[part 1 of 4: packages /MICROSAR/vDem42_swc/DataTypes to /MICROSAR/vDem42_swc/ComponentTypes]
AUTOSAR XML (schema 4-2-1)
package /MICROSAR/vDem42_swc/DataTypes
  12 x impl type:
    Dem_DTCFormatType: compu {0=DEM_DTC_FORMAT_OBD, 1=DEM_DTC_FORMAT_UDS, 2=DEM_DTC_FORMAT_J1939}, range raw 0..255, implementation-data-type=uint8
    Dem_DTCOriginType:
      compu {1=DEM_DTC_ORIGIN_PRIMARY_MEMORY, 2=DEM_DTC_ORIGIN_MIRROR_MEMORY, 3=DEM_DTC_ORIGIN_PERMANENT_MEMORY, 4=DEM_DTC_ORIGIN_OBD_RELEVANT_MEMORY, 5=DEM_DTC_ORIGIN_SECONDARY_MEMORY, 5=DEM_DTC_ORIGIN_USERDEFINED_MEMORY_10, 5=DEM_DTC_ORIGIN_USERDEFINED_MEMORY_11, 5=DEM_DTC_ORIGIN_USERDEFINED_MEMORY_12, 5=DEM_DTC_ORIGIN_USERDEFINED_MEMORY_13, 5=DEM_DTC_ORIGIN_USERDEFINED_MEMORY_14, 5=DEM_DTC_ORIGIN_USERDEFINED_MEMORY_15, 5=DEM_DTC_ORIGIN_USERDEFINED_MEMORY_16, 5=DEM_DTC_ORIGIN_USERDEFINED_MEMORY_17, 5=DEM_DTC_ORIGIN_USERDEFINED_MEMORY_18, 5=DEM_DTC_ORIGIN_USERDEFINED_MEMORY_19, 5=DEM_DTC_ORIGIN_USERDEFINED_MEMORY_1A, 5=DEM_DTC_ORIGIN_USERDEFINED_MEMORY_1B, 5=DEM_DTC_ORIGIN_USERDEFINED_MEMORY_1C, 5=DEM_DTC_ORIGIN_USERDEFINED_MEMORY_1D, 5=DEM_DTC_ORIGIN_USERDEFINED_MEMORY_1E, 5=DEM_DTC_ORIGIN_USERDEFINED_MEMORY_1F, 5=DEM_DTC_ORIGIN_USERDEFINED_MEMORY_20, 5=DEM_DTC_ORIGIN_USERDEFINED_MEMORY_21, 5=DEM_DTC_ORIGIN_USERDEFINED_MEMORY_22, 5=DEM_DTC_ORIGIN_USERDEFINED_MEMORY_23, 5=DEM_DTC_ORIGIN_USERDEFINED_MEMORY_24, 5=DEM_DTC_ORIGIN_USERDEFINED_MEMORY_25, 5=DEM_DTC_ORIGIN_USERDEFINED_MEMORY_26, 5=DEM_DTC_ORIGIN_USERDEFINED_MEMORY_27, 5=DEM_DTC_ORIGIN_USERDEFINED_MEMORY_28, 5=DEM_DTC_ORIGIN_USERDEFINED_MEMORY_29, 5=DEM_DTC_ORIGIN_USERDEFINED_MEMORY_2A, 5=DEM_DTC_ORIGIN_USERDEFINED_MEMORY_2B, 5=DEM_DTC_ORIGIN_USERDEFINED_MEMORY_2C, 5=DEM_DTC_ORIGIN_USERDEFINED_MEMORY_2D, 5=DEM_DTC_ORIGIN_USERDEFINED_MEMORY_2E, 5=DEM_DTC_ORIGIN_USERDEFINED_MEMORY_2F, 5=DEM_DTC_ORIGIN_USERDEFINED_MEMORY_30, 5=DEM_DTC_ORIGIN_USERDEFINED_MEMORY_31, 5=DEM_DTC_ORIGIN_USERDEFINED_MEMORY_32, 5=DEM_DTC_ORIGIN_USERDEFINED_MEMORY_33, 5=DEM_DTC_ORIGIN_USERDEFINED_MEMORY_34, 5=DEM_DTC_ORIGIN_USERDEFINED_MEMORY_35, 5=DEM_DTC_ORIGIN_USERDEFINED_MEMORY_36, 5=DEM_DTC_ORIGIN_USERDEFINED_MEMORY_37, 5=DEM_DTC_ORIGIN_USERDEFINED_MEMORY_38, 5=DEM_DTC_ORIGIN_USERDEFINED_MEMORY_39, 5=DEM_DTC_ORIGIN_USERDEFINED_MEMORY_3A, 5=DEM_DTC_ORIGIN_USERDEFINED_MEMORY_3B, 5=DEM_DTC_ORIGIN_USERDEFINED_MEMORY_3C, 5=DEM_DTC_ORIGIN_USERDEFINED_MEMORY_3D, 5=DEM_DTC_ORIGIN_USERDEFINED_MEMORY_3E, 5=DEM_DTC_ORIGIN_USERDEFINED_MEMORY_3F, 5=DEM_DTC_ORIGIN_USERDEFINED_MEMORY_40, 5=DEM_DTC_ORIGIN_USERDEFINED_MEMORY_41, 5=DEM_DTC_ORIGIN_USERDEFINED_MEMORY_42, 5=DEM_DTC_ORIGIN_USERDEFINED_MEMORY_43, 5=DEM_DTC_ORIGIN_USERDEFINED_MEMORY_44, 5=DEM_DTC_ORIGIN_USERDEFINED_MEMORY_45, 5=DEM_DTC_ORIGIN_USERDEFINED_MEMORY_46, 5=DEM_DTC_ORIGIN_USERDEFINED_MEMORY_47, 5=DEM_DTC_ORIGIN_USERDEFINED_MEMORY_48, 5=DEM_DTC_ORIGIN_USERDEFINED_MEMORY_49, 5=DEM_DTC_ORIGIN_USERDEFINED_MEMORY_4A, 5=DEM_DTC_ORIGIN_USERDEFINED_MEMORY_4B, 5=DEM_DTC_ORIGIN_USERDEFINED_MEMORY_4C, 5=DEM_DTC_ORIGIN_USERDEFINED_MEMORY_4D, 5=DEM_DTC_ORIGIN_USERDEFINED_MEMORY_4E, 5=DEM_DTC_ORIGIN_USERDEFINED_MEMORY_4F, 5=DEM_DTC_ORIGIN_USERDEFINED_MEMORY_50, 5=DEM_DTC_ORIGIN_USERDEFINED_MEMORY_51, 5=DEM_DTC_ORIGIN_USERDEFINED_MEMORY_52, 5=DEM_DTC_ORIGIN_USERDEFINED_MEMORY_53, 5=DEM_DTC_ORIGIN_USERDEFINED_MEMORY_54, 5=DEM_DTC_ORIGIN_USERDEFINED_MEMORY_55, 5=DEM_DTC_ORIGIN_USERDEFINED_MEMORY_56, 5=DEM_DTC_ORIGIN_USERDEFINED_MEMORY_57, 5=DEM_DTC_ORIGIN_USERDEFINED_MEMORY_58, 5=DEM_DTC_ORIGIN_USERDEFINED_MEMORY_59, 5=DEM_DTC_ORIGIN_USERDEFINED_MEMORY_5A, 5=DEM_DTC_ORIGIN_USERDEFINED_MEMORY_5B, 5=DEM_DTC_ORIGIN_USERDEFINED_MEMORY_5C, 5=DEM_DTC_ORIGIN_USERDEFINED_MEMORY_5D, 5=DEM_DTC_ORIGIN_USERDEFINED_MEMORY_5E, 5=DEM_DTC_ORIGIN_USERDEFINED_MEMORY_5F, 5=DEM_DTC_ORIGIN_USERDEFINED_MEMORY_60, 5=DEM_DTC_ORIGIN_USERDEFINED_MEMORY_61, 5=DEM_DTC_ORIGIN_USERDEFINED_MEMORY_62, 5=DEM_DTC_ORIGIN_USERDEFINED_MEMORY_63, 5=DEM_DTC_ORIGIN_USERDEFINED_MEMORY_64, 5=DEM_DTC_ORIGIN_USERDEFINED_MEMORY_65, 5=DEM_DTC_ORIGIN_USERDEFINED_MEMORY_66, 5=DEM_DTC_ORIGIN_USERDEFINED_MEMORY_67, 5=DEM_DTC_ORIGIN_USERDEFINED_MEMORY_68, 5=DEM_DTC_ORIGIN_USERDEFINED_MEMORY_69, 5=DEM_DTC_ORIGIN_USERDEFINED_MEMORY_6A, 5=DEM_DTC_ORIGIN_USERDEFINED_MEMORY_6B, 5=DEM_DTC_ORIGIN_USERDEFINED_MEMORY_6C, 5=DEM_DTC_ORIGIN_USERDEFINED_MEMORY_6D, 5=DEM_DTC_ORIGIN_USERDEFINED_MEMORY_6E, 5=DEM_DTC_ORIGIN_USERDEFINED_MEMORY_6F, 5=DEM_DTC_ORIGIN_USERDEFINED_MEMORY_70, 5=DEM_DTC_ORIGIN_USERDEFINED_MEMORY_71, 5=DEM_DTC_ORIGIN_USERDEFINED_MEMORY_72, 5=DEM_DTC_ORIGIN_USERDEFINED_MEMORY_73, 5=DEM_DTC_ORIGIN_USERDEFINED_MEMORY_74, 5=DEM_DTC_ORIGIN_USERDEFINED_MEMORY_75, 5=DEM_DTC_ORIGIN_USERDEFINED_MEMORY_76, 5=DEM_DTC_ORIGIN_USERDEFINED_MEMORY_77, 5=DEM_DTC_ORIGIN_USERDEFINED_MEMORY_78, 5=DEM_DTC_ORIGIN_USERDEFINED_MEMORY_79, 5=DEM_DTC_ORIGIN_USERDEFINED_MEMORY_7A, 5=DEM_DTC_ORIGIN_USERDEFINED_MEMORY_7B, 5=DEM_DTC_ORIGIN_USERDEFINED_MEMORY_7C, 5=DEM_DTC_ORIGIN_USERDEFINED_MEMORY_7D, 5=DEM_DTC_ORIGIN_USERDEFINED_MEMORY_7E, 5=DEM_DTC_ORIGIN_USERDEFINED_MEMORY_7F, 5=DEM_DTC_ORIGIN_USERDEFINED_MEMORY_80, 5=DEM_DTC_ORIGIN_USERDEFINED_MEMORY_81, 5=DEM_DTC_ORIGIN_USERDEFINED_MEMORY_82, 5=DEM_DTC_ORIGIN_USERDEFINED_MEMORY_83, 5=DEM_DTC_ORIGIN_USERDEFINED_MEMORY_84, 5=DEM_DTC_ORIGIN_USERDEFINED_MEMORY_85, 5=DEM_DTC_ORIGIN_USERDEFINED_MEMORY_86, 5=DEM_DTC_ORIGIN_USERDEFINED_MEMORY_87, 5=DEM_DTC_ORIGIN_USERDEFINED_MEMORY_88, 5=DEM_DTC_ORIGIN_USERDEFINED_MEMORY_89, 5=DEM_DTC_ORIGIN_USERDEFINED_MEMORY_8A, 5=DEM_DTC_ORIGIN_USERDEFINED_MEMORY_8B, 5=DEM_DTC_ORIGIN_USERDEFINED_MEMORY_8C, 5=DEM_DTC_ORIGIN_USERDEFINED_MEMORY_8D, 5=DEM_DTC_ORIGIN_USERDEFINED_MEMORY_8E, 5=DEM_DTC_ORIGIN_USERDEFINED_MEMORY_8F, 5=DEM_DTC_ORIGIN_USERDEFINED_MEMORY_90, 5=DEM_DTC_ORIGIN_USERDEFINED_MEMORY_91, 5=DEM_DTC_ORIGIN_USERDEFINED_MEMORY_92, 5=DEM_DTC_ORIGIN_USERDEFINED_MEMORY_93, 5=DEM_DTC_ORIGIN_USERDEFINED_MEMORY_94, 5=DEM_DTC_ORIGIN_USERDEFINED_MEMORY_95, 5=DEM_DTC_ORIGIN_USERDEFINED_MEMORY_96, 5=DEM_DTC_ORIGIN_USERDEFINED_MEMORY_97, 5=DEM_DTC_ORIGIN_USERDEFINED_MEMORY_98, 5=DEM_DTC_ORIGIN_USERDEFINED_MEMORY_99, 5=DEM_DTC_ORIGIN_USERDEFINED_MEMORY_9A, 5=DEM_DTC_ORIGIN_USERDEFINED_MEMORY_9B, 5=DEM_DTC_ORIGIN_USERDEFINED_MEMORY_9C, 5=DEM_DTC_ORIGIN_USERDEFINED_MEMORY_9D, 5=DEM_DTC_ORIGIN_USERDEFINED_MEMORY_9E, 5=DEM_DTC_ORIGIN_USERDEFINED_MEMORY_9F, 5=DEM_DTC_ORIGIN_USERDEFINED_MEMORY_A0, 5=DEM_DTC_ORIGIN_USERDEFINED_MEMORY_A1, 5=DEM_DTC_ORIGIN_USERDEFINED_MEMORY_A2, 5=DEM_DTC_ORIGIN_USERDEFINED_MEMORY_A3, 5=DEM_DTC_ORIGIN_USERDEFINED_MEMORY_A4, 5=DEM_DTC_ORIGIN_USERDEFINED_MEMORY_A5, 5=DEM_DTC_ORIGIN_USERDEFINED_MEMORY_A6, 5=DEM_DTC_ORIGIN_USERDEFINED_MEMORY_A7, 5=DEM_DTC_ORIGIN_USERDEFINED_MEMORY_A8, 5=DEM_DTC_ORIGIN_USERDEFINED_MEMORY_A9, 5=DEM_DTC_ORIGIN_USERDEFINED_MEMORY_AA, 5=DEM_DTC_ORIGIN_USERDEFINED_MEMORY_AB, 5=DEM_DTC_ORIGIN_USERDEFINED_MEMORY_AC, 5=DEM_DTC_ORIGIN_USERDEFINED_MEMORY_AD, 5=DEM_DTC_ORIGIN_USERDEFINED_MEMORY_AE, 5=DEM_DTC_ORIGIN_USERDEFINED_MEMORY_AF, 5=DEM_DTC_ORIGIN_USERDEFINED_MEMORY_B0, 5=DEM_DTC_ORIGIN_USERDEFINED_MEMORY_B1, 5=DEM_DTC_ORIGIN_USERDEFINED_MEMORY_B2, 5=DEM_DTC_ORIGIN_USERDEFINED_MEMORY_B3, 5=DEM_DTC_ORIGIN_USERDEFINED_MEMORY_B4, 5=DEM_DTC_ORIGIN_USERDEFINED_MEMORY_B5, 5=DEM_DTC_ORIGIN_USERDEFINED_MEMORY_B6, 5=DEM_DTC_ORIGIN_USERDEFINED_MEMORY_B7, 5=DEM_DTC_ORIGIN_USERDEFINED_MEMORY_B8, 5=DEM_DTC_ORIGIN_USERDEFINED_MEMORY_B9, 5=DEM_DTC_ORIGIN_USERDEFINED_MEMORY_BA, 5=DEM_DTC_ORIGIN_USERDEFINED_MEMORY_BB, 5=DEM_DTC_ORIGIN_USERDEFINED_MEMORY_BC, 5=DEM_DTC_ORIGIN_USERDEFINED_MEMORY_BD, 5=DEM_DTC_ORIGIN_USERDEFINED_MEMORY_BE, 5=DEM_DTC_ORIGIN_USERDEFINED_MEMORY_BF, 5=DEM_DTC_ORIGIN_USERDEFINED_MEMORY_C0, 5=DEM_DTC_ORIGIN_USERDEFINED_MEMORY_C1, 5=DEM_DTC_ORIGIN_USERDEFINED_MEMORY_C2, 5=DEM_DTC_ORIGIN_USERDEFINED_MEMORY_C3, 5=DEM_DTC_ORIGIN_USERDEFINED_MEMORY_C4, 5=DEM_DTC_ORIGIN_USERDEFINED_MEMORY_C5, 5=DEM_DTC_ORIGIN_USERDEFINED_MEMORY_C6, 5=DEM_DTC_ORIGIN_USERDEFINED_MEMORY_C7, 5=DEM_DTC_ORIGIN_USERDEFINED_MEMORY_C8, 5=DEM_DTC_ORIGIN_USERDEFINED_MEMORY_C9, 5=DEM_DTC_ORIGIN_USERDEFINED_MEMORY_CA, 5=DEM_DTC_ORIGIN_USERDEFINED_MEMORY_CB, 5=DEM_DTC_ORIGIN_USERDEFINED_MEMORY_CC, 5=DEM_DTC_ORIGIN_USERDEFINED_MEMORY_CD, 5=DEM_DTC_ORIGIN_USERDEFINED_MEMORY_CE, 5=DEM_DTC_ORIGIN_USERDEFINED_MEMORY_CF, 5=DEM_DTC_ORIGIN_USERDEFINED_MEMORY_D0, 5=DEM_DTC_ORIGIN_USERDEFINED_MEMORY_D1, 5=DEM_DTC_ORIGIN_USERDEFINED_MEMORY_D2, 5=DEM_DTC_ORIGIN_USERDEFINED_MEMORY_D3, 5=DEM_DTC_ORIGIN_USERDEFINED_MEMORY_D4, 5=DEM_DTC_ORIGIN_USERDEFINED_MEMORY_D5, 5=DEM_DTC_ORIGIN_USERDEFINED_MEMORY_D6, 5=DEM_DTC_ORIGIN_USERDEFINED_MEMORY_D7, 5=DEM_DTC_ORIGIN_USERDEFINED_MEMORY_D8, 5=DEM_DTC_ORIGIN_USERDEFINED_MEMORY_D9, 5=DEM_DTC_ORIGIN_USERDEFINED_MEMORY_DA, 5=DEM_DTC_ORIGIN_USERDEFINED_MEMORY_DB, 5=DEM_DTC_ORIGIN_USERDEFINED_MEMORY_DC, 5=DEM_DTC_ORIGIN_USERDEFINED_MEMORY_DD, 5=DEM_DTC_ORIGIN_USERDEFINED_MEMORY_DE, 5=DEM_DTC_ORIGIN_USERDEFINED_MEMORY_DF, 5=DEM_DTC_ORIGIN_USERDEFINED_MEMORY_E0, 5=DEM_DTC_ORIGIN_USERDEFINED_MEMORY_E1, 5=DEM_DTC_ORIGIN_USERDEFINED_MEMORY_E2, 5=DEM_DTC_ORIGIN_USERDEFINED_MEMORY_E3, 5=DEM_DTC_ORIGIN_USERDEFINED_MEMORY_E4, 5=DEM_DTC_ORIGIN_USERDEFINED_MEMORY_E5, 5=DEM_DTC_ORIGIN_USERDEFINED_MEMORY_E6, 5=DEM_DTC_ORIGIN_USERDEFINED_MEMORY_E7, 5=DEM_DTC_ORIGIN_USERDEFINED_MEMORY_E8, 5=DEM_DTC_ORIGIN_USERDEFINED_MEMORY_E9, 5=DEM_DTC_ORIGIN_USERDEFINED_MEMORY_EA, 5=DEM_DTC_ORIGIN_USERDEFINED_MEMORY_EB, 5=DEM_DTC_ORIGIN_USERDEFINED_MEMORY_EC, 5=DEM_DTC_ORIGIN_USERDEFINED_MEMORY_ED, 5=DEM_DTC_ORIGIN_USERDEFINED_MEMORY_EE, 5=DEM_DTC_ORIGIN_USERDEFINED_MEMORY_EF, 5=DEM_DTC_ORIGIN_USERDEFINED_MEMORY_F0, 5=DEM_DTC_ORIGIN_USERDEFINED_MEMORY_F1, 5=DEM_DTC_ORIGIN_USERDEFINED_MEMORY_F2, 5=DEM_DTC_ORIGIN_USERDEFINED_MEMORY_F3, 5=DEM_DTC_ORIGIN_USERDEFINED_MEMORY_F4, 5=DEM_DTC_ORIGIN_USERDEFINED_MEMORY_F5, 5=DEM_DTC_ORIGIN_USERDEFINED_MEMORY_F6, 5=DEM_DTC_ORIGIN_USERDEFINED_MEMORY_F7, 5=DEM_DTC_ORIGIN_USERDEFINED_MEMORY_F8, 5=DEM_DTC_ORIGIN_USERDEFINED_MEMORY_F9, 5=DEM_DTC_ORIGIN_USERDEFINED_MEMORY_FA, 5=DEM_DTC_ORIGIN_USERDEFINED_MEMORY_FB, 5=DEM_DTC_ORIGIN_USERDEFINED_MEMORY_FC, 5=DEM_DTC_ORIGIN_USERDEFINED_MEMORY_FD, 5=DEM_DTC_ORIGIN_USERDEFINED_MEMORY_FE, 5=DEM_DTC_ORIGIN_USERDEFINED_MEMORY_FF}
      range raw 0..65535
      implementation-data-type=uint16
    Dem_UdsStatusByteType: compu {mask 1: 1=DEM_UDS_STATUS_TF, mask 2: 2=DEM_UDS_STATUS_TFTOC, mask 4: 4=DEM_UDS_STATUS_PDTC, mask 8: 8=DEM_UDS_STATUS_CDTC, mask 16: 16=DEM_UDS_STATUS_TNCSLC, mask 32: 32=DEM_UDS_STATUS_TFSLC, mask 64: 64=DEM_UDS_STATUS_TNCTOC, mask 128: 128=DEM_UDS_STATUS_WIR}, range raw 0..255, implementation-data-type=uint8
    Dem_EventIdType: range raw 1..65535, implementation-data-type=uint16
    Dem_DebouncingStateType: compu {mask 1: 1=DEM_TEMPORARILY_DEFECTIVE, mask 2: 2=DEM_FINALLY_DEFECTIVE, mask 4: 4=DEM_TEMPORARILY_HEALED, mask 8: 8=DEM_TEST_COMPLETE, mask 16: 16=DEM_DTR_UPDATE}, range raw 0..255, implementation-data-type=uint8
    VDem42_DTCFormatType: compu {0=VDEM42_DTC_FORMAT_OBD, 1=VDEM42_DTC_FORMAT_UDS, 2=VDEM42_DTC_FORMAT_J1939}, range raw 0..255, implementation-data-type=uint8
    VDem42_DTCOriginType:
      compu {1=VDEM42_DTC_ORIGIN_PRIMARY_MEMORY, 2=VDEM42_DTC_ORIGIN_MIRROR_MEMORY, 3=VDEM42_DTC_ORIGIN_PERMANENT_MEMORY, 4=VDEM42_DTC_ORIGIN_OBD_RELEVANT_MEMORY, 5=VDEM42_DTC_ORIGIN_SECONDARY_MEMORY, 5=VDEM42_DTC_ORIGIN_USERDEFINED_MEMORY_10, 5=VDEM42_DTC_ORIGIN_USERDEFINED_MEMORY_11, 5=VDEM42_DTC_ORIGIN_USERDEFINED_MEMORY_12, 5=VDEM42_DTC_ORIGIN_USERDEFINED_MEMORY_13, 5=VDEM42_DTC_ORIGIN_USERDEFINED_MEMORY_14, 5=VDEM42_DTC_ORIGIN_USERDEFINED_MEMORY_15, 5=VDEM42_DTC_ORIGIN_USERDEFINED_MEMORY_16, 5=VDEM42_DTC_ORIGIN_USERDEFINED_MEMORY_17, 5=VDEM42_DTC_ORIGIN_USERDEFINED_MEMORY_18, 5=VDEM42_DTC_ORIGIN_USERDEFINED_MEMORY_19, 5=VDEM42_DTC_ORIGIN_USERDEFINED_MEMORY_1A, 5=VDEM42_DTC_ORIGIN_USERDEFINED_MEMORY_1B, 5=VDEM42_DTC_ORIGIN_USERDEFINED_MEMORY_1C, 5=VDEM42_DTC_ORIGIN_USERDEFINED_MEMORY_1D, 5=VDEM42_DTC_ORIGIN_USERDEFINED_MEMORY_1E, 5=VDEM42_DTC_ORIGIN_USERDEFINED_MEMORY_1F, 5=VDEM42_DTC_ORIGIN_USERDEFINED_MEMORY_20, 5=VDEM42_DTC_ORIGIN_USERDEFINED_MEMORY_21, 5=VDEM42_DTC_ORIGIN_USERDEFINED_MEMORY_22, 5=VDEM42_DTC_ORIGIN_USERDEFINED_MEMORY_23, 5=VDEM42_DTC_ORIGIN_USERDEFINED_MEMORY_24, 5=VDEM42_DTC_ORIGIN_USERDEFINED_MEMORY_25, 5=VDEM42_DTC_ORIGIN_USERDEFINED_MEMORY_26, 5=VDEM42_DTC_ORIGIN_USERDEFINED_MEMORY_27, 5=VDEM42_DTC_ORIGIN_USERDEFINED_MEMORY_28, 5=VDEM42_DTC_ORIGIN_USERDEFINED_MEMORY_29, 5=VDEM42_DTC_ORIGIN_USERDEFINED_MEMORY_2A, 5=VDEM42_DTC_ORIGIN_USERDEFINED_MEMORY_2B, 5=VDEM42_DTC_ORIGIN_USERDEFINED_MEMORY_2C, 5=VDEM42_DTC_ORIGIN_USERDEFINED_MEMORY_2D, 5=VDEM42_DTC_ORIGIN_USERDEFINED_MEMORY_2E, 5=VDEM42_DTC_ORIGIN_USERDEFINED_MEMORY_2F, 5=VDEM42_DTC_ORIGIN_USERDEFINED_MEMORY_30, 5=VDEM42_DTC_ORIGIN_USERDEFINED_MEMORY_31, 5=VDEM42_DTC_ORIGIN_USERDEFINED_MEMORY_32, 5=VDEM42_DTC_ORIGIN_USERDEFINED_MEMORY_33, 5=VDEM42_DTC_ORIGIN_USERDEFINED_MEMORY_34, 5=VDEM42_DTC_ORIGIN_USERDEFINED_MEMORY_35, 5=VDEM42_DTC_ORIGIN_USERDEFINED_MEMORY_36, 5=VDEM42_DTC_ORIGIN_USERDEFINED_MEMORY_37, 5=VDEM42_DTC_ORIGIN_USERDEFINED_MEMORY_38, 5=VDEM42_DTC_ORIGIN_USERDEFINED_MEMORY_39, 5=VDEM42_DTC_ORIGIN_USERDEFINED_MEMORY_3A, 5=VDEM42_DTC_ORIGIN_USERDEFINED_MEMORY_3B, 5=VDEM42_DTC_ORIGIN_USERDEFINED_MEMORY_3C, 5=VDEM42_DTC_ORIGIN_USERDEFINED_MEMORY_3D, 5=VDEM42_DTC_ORIGIN_USERDEFINED_MEMORY_3E, 5=VDEM42_DTC_ORIGIN_USERDEFINED_MEMORY_3F, 5=VDEM42_DTC_ORIGIN_USERDEFINED_MEMORY_40, 5=VDEM42_DTC_ORIGIN_USERDEFINED_MEMORY_41, 5=VDEM42_DTC_ORIGIN_USERDEFINED_MEMORY_42, 5=VDEM42_DTC_ORIGIN_USERDEFINED_MEMORY_43, 5=VDEM42_DTC_ORIGIN_USERDEFINED_MEMORY_44, 5=VDEM42_DTC_ORIGIN_USERDEFINED_MEMORY_45, 5=VDEM42_DTC_ORIGIN_USERDEFINED_MEMORY_46, 5=VDEM42_DTC_ORIGIN_USERDEFINED_MEMORY_47, 5=VDEM42_DTC_ORIGIN_USERDEFINED_MEMORY_48, 5=VDEM42_DTC_ORIGIN_USERDEFINED_MEMORY_49, 5=VDEM42_DTC_ORIGIN_USERDEFINED_MEMORY_4A, 5=VDEM42_DTC_ORIGIN_USERDEFINED_MEMORY_4B, 5=VDEM42_DTC_ORIGIN_USERDEFINED_MEMORY_4C, 5=VDEM42_DTC_ORIGIN_USERDEFINED_MEMORY_4D, 5=VDEM42_DTC_ORIGIN_USERDEFINED_MEMORY_4E, 5=VDEM42_DTC_ORIGIN_USERDEFINED_MEMORY_4F, 5=VDEM42_DTC_ORIGIN_USERDEFINED_MEMORY_50, 5=VDEM42_DTC_ORIGIN_USERDEFINED_MEMORY_51, 5=VDEM42_DTC_ORIGIN_USERDEFINED_MEMORY_52, 5=VDEM42_DTC_ORIGIN_USERDEFINED_MEMORY_53, 5=VDEM42_DTC_ORIGIN_USERDEFINED_MEMORY_54, 5=VDEM42_DTC_ORIGIN_USERDEFINED_MEMORY_55, 5=VDEM42_DTC_ORIGIN_USERDEFINED_MEMORY_56, 5=VDEM42_DTC_ORIGIN_USERDEFINED_MEMORY_57, 5=VDEM42_DTC_ORIGIN_USERDEFINED_MEMORY_58, 5=VDEM42_DTC_ORIGIN_USERDEFINED_MEMORY_59, 5=VDEM42_DTC_ORIGIN_USERDEFINED_MEMORY_5A, 5=VDEM42_DTC_ORIGIN_USERDEFINED_MEMORY_5B, 5=VDEM42_DTC_ORIGIN_USERDEFINED_MEMORY_5C, 5=VDEM42_DTC_ORIGIN_USERDEFINED_MEMORY_5D, 5=VDEM42_DTC_ORIGIN_USERDEFINED_MEMORY_5E, 5=VDEM42_DTC_ORIGIN_USERDEFINED_MEMORY_5F, 5=VDEM42_DTC_ORIGIN_USERDEFINED_MEMORY_60, 5=VDEM42_DTC_ORIGIN_USERDEFINED_MEMORY_61, 5=VDEM42_DTC_ORIGIN_USERDEFINED_MEMORY_62, 5=VDEM42_DTC_ORIGIN_USERDEFINED_MEMORY_63, 5=VDEM42_DTC_ORIGIN_USERDEFINED_MEMORY_64, 5=VDEM42_DTC_ORIGIN_USERDEFINED_MEMORY_65, 5=VDEM42_DTC_ORIGIN_USERDEFINED_MEMORY_66, 5=VDEM42_DTC_ORIGIN_USERDEFINED_MEMORY_67, 5=VDEM42_DTC_ORIGIN_USERDEFINED_MEMORY_68, 5=VDEM42_DTC_ORIGIN_USERDEFINED_MEMORY_69, 5=VDEM42_DTC_ORIGIN_USERDEFINED_MEMORY_6A, 5=VDEM42_DTC_ORIGIN_USERDEFINED_MEMORY_6B, 5=VDEM42_DTC_ORIGIN_USERDEFINED_MEMORY_6C, 5=VDEM42_DTC_ORIGIN_USERDEFINED_MEMORY_6D, 5=VDEM42_DTC_ORIGIN_USERDEFINED_MEMORY_6E, 5=VDEM42_DTC_ORIGIN_USERDEFINED_MEMORY_6F, 5=VDEM42_DTC_ORIGIN_USERDEFINED_MEMORY_70, 5=VDEM42_DTC_ORIGIN_USERDEFINED_MEMORY_71, 5=VDEM42_DTC_ORIGIN_USERDEFINED_MEMORY_72, 5=VDEM42_DTC_ORIGIN_USERDEFINED_MEMORY_73, 5=VDEM42_DTC_ORIGIN_USERDEFINED_MEMORY_74, 5=VDEM42_DTC_ORIGIN_USERDEFINED_MEMORY_75, 5=VDEM42_DTC_ORIGIN_USERDEFINED_MEMORY_76, 5=VDEM42_DTC_ORIGIN_USERDEFINED_MEMORY_77, 5=VDEM42_DTC_ORIGIN_USERDEFINED_MEMORY_78, 5=VDEM42_DTC_ORIGIN_USERDEFINED_MEMORY_79, 5=VDEM42_DTC_ORIGIN_USERDEFINED_MEMORY_7A, 5=VDEM42_DTC_ORIGIN_USERDEFINED_MEMORY_7B, 5=VDEM42_DTC_ORIGIN_USERDEFINED_MEMORY_7C, 5=VDEM42_DTC_ORIGIN_USERDEFINED_MEMORY_7D, 5=VDEM42_DTC_ORIGIN_USERDEFINED_MEMORY_7E, 5=VDEM42_DTC_ORIGIN_USERDEFINED_MEMORY_7F, 5=VDEM42_DTC_ORIGIN_USERDEFINED_MEMORY_80, 5=VDEM42_DTC_ORIGIN_USERDEFINED_MEMORY_81, 5=VDEM42_DTC_ORIGIN_USERDEFINED_MEMORY_82, 5=VDEM42_DTC_ORIGIN_USERDEFINED_MEMORY_83, 5=VDEM42_DTC_ORIGIN_USERDEFINED_MEMORY_84, 5=VDEM42_DTC_ORIGIN_USERDEFINED_MEMORY_85, 5=VDEM42_DTC_ORIGIN_USERDEFINED_MEMORY_86, 5=VDEM42_DTC_ORIGIN_USERDEFINED_MEMORY_87, 5=VDEM42_DTC_ORIGIN_USERDEFINED_MEMORY_88, 5=VDEM42_DTC_ORIGIN_USERDEFINED_MEMORY_89, 5=VDEM42_DTC_ORIGIN_USERDEFINED_MEMORY_8A, 5=VDEM42_DTC_ORIGIN_USERDEFINED_MEMORY_8B, 5=VDEM42_DTC_ORIGIN_USERDEFINED_MEMORY_8C, 5=VDEM42_DTC_ORIGIN_USERDEFINED_MEMORY_8D, 5=VDEM42_DTC_ORIGIN_USERDEFINED_MEMORY_8E, 5=VDEM42_DTC_ORIGIN_USERDEFINED_MEMORY_8F, 5=VDEM42_DTC_ORIGIN_USERDEFINED_MEMORY_90, 5=VDEM42_DTC_ORIGIN_USERDEFINED_MEMORY_91, 5=VDEM42_DTC_ORIGIN_USERDEFINED_MEMORY_92, 5=VDEM42_DTC_ORIGIN_USERDEFINED_MEMORY_93, 5=VDEM42_DTC_ORIGIN_USERDEFINED_MEMORY_94, 5=VDEM42_DTC_ORIGIN_USERDEFINED_MEMORY_95, 5=VDEM42_DTC_ORIGIN_USERDEFINED_MEMORY_96, 5=VDEM42_DTC_ORIGIN_USERDEFINED_MEMORY_97, 5=VDEM42_DTC_ORIGIN_USERDEFINED_MEMORY_98, 5=VDEM42_DTC_ORIGIN_USERDEFINED_MEMORY_99, 5=VDEM42_DTC_ORIGIN_USERDEFINED_MEMORY_9A, 5=VDEM42_DTC_ORIGIN_USERDEFINED_MEMORY_9B, 5=VDEM42_DTC_ORIGIN_USERDEFINED_MEMORY_9C, 5=VDEM42_DTC_ORIGIN_USERDEFINED_MEMORY_9D, 5=VDEM42_DTC_ORIGIN_USERDEFINED_MEMORY_9E, 5=VDEM42_DTC_ORIGIN_USERDEFINED_MEMORY_9F, 5=VDEM42_DTC_ORIGIN_USERDEFINED_MEMORY_A0, 5=VDEM42_DTC_ORIGIN_USERDEFINED_MEMORY_A1, 5=VDEM42_DTC_ORIGIN_USERDEFINED_MEMORY_A2, 5=VDEM42_DTC_ORIGIN_USERDEFINED_MEMORY_A3, 5=VDEM42_DTC_ORIGIN_USERDEFINED_MEMORY_A4, 5=VDEM42_DTC_ORIGIN_USERDEFINED_MEMORY_A5, 5=VDEM42_DTC_ORIGIN_USERDEFINED_MEMORY_A6, 5=VDEM42_DTC_ORIGIN_USERDEFINED_MEMORY_A7, 5=VDEM42_DTC_ORIGIN_USERDEFINED_MEMORY_A8, 5=VDEM42_DTC_ORIGIN_USERDEFINED_MEMORY_A9, 5=VDEM42_DTC_ORIGIN_USERDEFINED_MEMORY_AA, 5=VDEM42_DTC_ORIGIN_USERDEFINED_MEMORY_AB, 5=VDEM42_DTC_ORIGIN_USERDEFINED_MEMORY_AC, 5=VDEM42_DTC_ORIGIN_USERDEFINED_MEMORY_AD, 5=VDEM42_DTC_ORIGIN_USERDEFINED_MEMORY_AE, 5=VDEM42_DTC_ORIGIN_USERDEFINED_MEMORY_AF, 5=VDEM42_DTC_ORIGIN_USERDEFINED_MEMORY_B0, 5=VDEM42_DTC_ORIGIN_USERDEFINED_MEMORY_B1, 5=VDEM42_DTC_ORIGIN_USERDEFINED_MEMORY_B2, 5=VDEM42_DTC_ORIGIN_USERDEFINED_MEMORY_B3, 5=VDEM42_DTC_ORIGIN_USERDEFINED_MEMORY_B4, 5=VDEM42_DTC_ORIGIN_USERDEFINED_MEMORY_B5, 5=VDEM42_DTC_ORIGIN_USERDEFINED_MEMORY_B6, 5=VDEM42_DTC_ORIGIN_USERDEFINED_MEMORY_B7, 5=VDEM42_DTC_ORIGIN_USERDEFINED_MEMORY_B8, 5=VDEM42_DTC_ORIGIN_USERDEFINED_MEMORY_B9, 5=VDEM42_DTC_ORIGIN_USERDEFINED_MEMORY_BA, 5=VDEM42_DTC_ORIGIN_USERDEFINED_MEMORY_BB, 5=VDEM42_DTC_ORIGIN_USERDEFINED_MEMORY_BC, 5=VDEM42_DTC_ORIGIN_USERDEFINED_MEMORY_BD, 5=VDEM42_DTC_ORIGIN_USERDEFINED_MEMORY_BE, 5=VDEM42_DTC_ORIGIN_USERDEFINED_MEMORY_BF, 5=VDEM42_DTC_ORIGIN_USERDEFINED_MEMORY_C0, 5=VDEM42_DTC_ORIGIN_USERDEFINED_MEMORY_C1, 5=VDEM42_DTC_ORIGIN_USERDEFINED_MEMORY_C2, 5=VDEM42_DTC_ORIGIN_USERDEFINED_MEMORY_C3, 5=VDEM42_DTC_ORIGIN_USERDEFINED_MEMORY_C4, 5=VDEM42_DTC_ORIGIN_USERDEFINED_MEMORY_C5, 5=VDEM42_DTC_ORIGIN_USERDEFINED_MEMORY_C6, 5=VDEM42_DTC_ORIGIN_USERDEFINED_MEMORY_C7, 5=VDEM42_DTC_ORIGIN_USERDEFINED_MEMORY_C8, 5=VDEM42_DTC_ORIGIN_USERDEFINED_MEMORY_C9, 5=VDEM42_DTC_ORIGIN_USERDEFINED_MEMORY_CA, 5=VDEM42_DTC_ORIGIN_USERDEFINED_MEMORY_CB, 5=VDEM42_DTC_ORIGIN_USERDEFINED_MEMORY_CC, 5=VDEM42_DTC_ORIGIN_USERDEFINED_MEMORY_CD, 5=VDEM42_DTC_ORIGIN_USERDEFINED_MEMORY_CE, 5=VDEM42_DTC_ORIGIN_USERDEFINED_MEMORY_CF, 5=VDEM42_DTC_ORIGIN_USERDEFINED_MEMORY_D0, 5=VDEM42_DTC_ORIGIN_USERDEFINED_MEMORY_D1, 5=VDEM42_DTC_ORIGIN_USERDEFINED_MEMORY_D2, 5=VDEM42_DTC_ORIGIN_USERDEFINED_MEMORY_D3, 5=VDEM42_DTC_ORIGIN_USERDEFINED_MEMORY_D4, 5=VDEM42_DTC_ORIGIN_USERDEFINED_MEMORY_D5, 5=VDEM42_DTC_ORIGIN_USERDEFINED_MEMORY_D6, 5=VDEM42_DTC_ORIGIN_USERDEFINED_MEMORY_D7, 5=VDEM42_DTC_ORIGIN_USERDEFINED_MEMORY_D8, 5=VDEM42_DTC_ORIGIN_USERDEFINED_MEMORY_D9, 5=VDEM42_DTC_ORIGIN_USERDEFINED_MEMORY_DA, 5=VDEM42_DTC_ORIGIN_USERDEFINED_MEMORY_DB, 5=VDEM42_DTC_ORIGIN_USERDEFINED_MEMORY_DC, 5=VDEM42_DTC_ORIGIN_USERDEFINED_MEMORY_DD, 5=VDEM42_DTC_ORIGIN_USERDEFINED_MEMORY_DE, 5=VDEM42_DTC_ORIGIN_USERDEFINED_MEMORY_DF, 5=VDEM42_DTC_ORIGIN_USERDEFINED_MEMORY_E0, 5=VDEM42_DTC_ORIGIN_USERDEFINED_MEMORY_E1, 5=VDEM42_DTC_ORIGIN_USERDEFINED_MEMORY_E2, 5=VDEM42_DTC_ORIGIN_USERDEFINED_MEMORY_E3, 5=VDEM42_DTC_ORIGIN_USERDEFINED_MEMORY_E4, 5=VDEM42_DTC_ORIGIN_USERDEFINED_MEMORY_E5, 5=VDEM42_DTC_ORIGIN_USERDEFINED_MEMORY_E6, 5=VDEM42_DTC_ORIGIN_USERDEFINED_MEMORY_E7, 5=VDEM42_DTC_ORIGIN_USERDEFINED_MEMORY_E8, 5=VDEM42_DTC_ORIGIN_USERDEFINED_MEMORY_E9, 5=VDEM42_DTC_ORIGIN_USERDEFINED_MEMORY_EA, 5=VDEM42_DTC_ORIGIN_USERDEFINED_MEMORY_EB, 5=VDEM42_DTC_ORIGIN_USERDEFINED_MEMORY_EC, 5=VDEM42_DTC_ORIGIN_USERDEFINED_MEMORY_ED, 5=VDEM42_DTC_ORIGIN_USERDEFINED_MEMORY_EE, 5=VDEM42_DTC_ORIGIN_USERDEFINED_MEMORY_EF, 5=VDEM42_DTC_ORIGIN_USERDEFINED_MEMORY_F0, 5=VDEM42_DTC_ORIGIN_USERDEFINED_MEMORY_F1, 5=VDEM42_DTC_ORIGIN_USERDEFINED_MEMORY_F2, 5=VDEM42_DTC_ORIGIN_USERDEFINED_MEMORY_F3, 5=VDEM42_DTC_ORIGIN_USERDEFINED_MEMORY_F4, 5=VDEM42_DTC_ORIGIN_USERDEFINED_MEMORY_F5, 5=VDEM42_DTC_ORIGIN_USERDEFINED_MEMORY_F6, 5=VDEM42_DTC_ORIGIN_USERDEFINED_MEMORY_F7, 5=VDEM42_DTC_ORIGIN_USERDEFINED_MEMORY_F8, 5=VDEM42_DTC_ORIGIN_USERDEFINED_MEMORY_F9, 5=VDEM42_DTC_ORIGIN_USERDEFINED_MEMORY_FA, 5=VDEM42_DTC_ORIGIN_USERDEFINED_MEMORY_FB, 5=VDEM42_DTC_ORIGIN_USERDEFINED_MEMORY_FC, 5=VDEM42_DTC_ORIGIN_USERDEFINED_MEMORY_FD, 5=VDEM42_DTC_ORIGIN_USERDEFINED_MEMORY_FE, 5=VDEM42_DTC_ORIGIN_USERDEFINED_MEMORY_FF}
      range raw 0..255
      implementation-data-type=uint8
    VDem42_UdsStatusByteType: compu {mask 1: 1=VDEM42_UDS_STATUS_TF, mask 2: 2=VDEM42_UDS_STATUS_TFTOC, mask 4: 4=VDEM42_UDS_STATUS_PDTC, mask 8: 8=VDEM42_UDS_STATUS_CDTC, mask 16: 16=VDEM42_UDS_STATUS_TNCSLC, mask 32: 32=VDEM42_UDS_STATUS_TFSLC, mask 64: 64=VDEM42_UDS_STATUS_TNCTOC, mask 128: 128=VDEM42_UDS_STATUS_WIR}, range raw 0..255, implementation-data-type=uint8
    VDem42_EventIdType: range raw 1..65535, implementation-data-type=uint16
    VDem42_DebouncingStateType: compu {mask 1: 1=VDEM42_TEMPORARILY_DEFECTIVE, mask 2: 2=VDEM42_FINALLY_DEFECTIVE, mask 4: 4=VDEM42_TEMPORARILY_HEALED, mask 8: 8=VDEM42_TEST_COMPLETE, mask 16: 16=VDEM42_DTR_UPDATE}, range raw 0..255, implementation-data-type=uint8
    Dem_MaxDataValueType: category=ARRAY, sw-calibration-access=READ-ONLY
      element Dem_MaxDataValueTypeElement: array-size=2, array-size-semantics=FIXED-SIZE, implementation-data-type=uint8
    VDem42_MaxDataValueType: category=ARRAY, sw-calibration-access=READ-ONLY
      element VDem42_MaxDataValueTypeElement: array-size=2, array-size-semantics=FIXED-SIZE, implementation-data-type=uint8
package /MICROSAR/vDem42_swc/Interfaces
  7 x client server interface, all with is-service=true, service-kind=VENDOR-SPECIFIC:
    CddIf
      operation ClearDTC: possible-error=[CddIf/DEM_CLEAR_FAILED, DEM_CLEAR_PENDING, CddIf/DEM_CLEAR_BUSY, CddIf/DEM_CLEAR_MEMORY_ERROR, DEM_CLEAR_WRONG_DTC, DEM_CLEAR_WRONG_DTCORIGIN]
        arg DTC: type=uint32, direction=IN
        arg DTCFormat: type=VDem42_DTCFormatType, direction=IN
        arg DTCOrigin: type=VDem42_DTCOriginType, direction=IN
      6 x error:
        DEM_CLEAR_FAILED: error-code=3
        DEM_CLEAR_PENDING: error-code=4
        DEM_CLEAR_BUSY: error-code=5
        DEM_CLEAR_MEMORY_ERROR: error-code=6
        DEM_CLEAR_WRONG_DTC: error-code=1
        DEM_CLEAR_WRONG_DTCORIGIN: error-code=2
    DTCSuppression422
      operation SetDTCSuppression: possible-error=DTCSuppression422/E_NOT_OK
        arg DTC: type=uint32, direction=IN
        arg DTCFormat: type=VDem42_DTCFormatType, direction=IN
        arg SuppressionStatus: type=boolean, direction=IN
      operation GetDTCSuppression: possible-error=DTCSuppression422/E_NOT_OK
        arg DTC: type=uint32, direction=IN
        arg DTCFormat: type=VDem42_DTCFormatType, direction=IN
        arg SuppressionStatus: type=boolean, direction=OUT
      error E_NOT_OK: error-code=1
    ClearDTC
      operation ClearDTC: possible-error=[ClearDTC/E_NOT_OK, ClearDTC/DEM_CLEAR_FAILED, ClearDTC/DEM_PENDING, ClearDTC/DEM_CLEAR_BUSY, ClearDTC/DEM_CLEAR_MEMORY_ERROR, ClearDTC/DEM_WRONG_DTC, ClearDTC/DEM_WRONG_DTCORIGIN]
      operation SelectDTC: possible-error=ClearDTC/E_NOT_OK
        arg DTC: type=uint32, direction=IN
        arg DTCFormat: type=Dem_DTCFormatType, direction=IN
        arg DTCOrigin: type=Dem_DTCOriginType, direction=IN
      7 x error:
        E_NOT_OK: error-code=1
        DEM_CLEAR_FAILED: error-code=7
        DEM_PENDING: error-code=4
        DEM_CLEAR_BUSY: error-code=5
        DEM_CLEAR_MEMORY_ERROR: error-code=6
        DEM_WRONG_DTC: error-code=8
        DEM_WRONG_DTCORIGIN: error-code=9
    DTCSuppression43
      operation SetDTCSuppression: possible-error=[DTCSuppression43/E_NOT_OK, DTCSuppression43/DEM_WRONG_DTC, DTCSuppression43/DEM_WRONG_DTCORIGIN, DTCSuppression43/DEM_PENDING]
        arg SuppressionStatus: type=boolean, direction=IN
      operation GetDTCSuppression: possible-error=[DTCSuppression43/E_NOT_OK, DTCSuppression43/DEM_WRONG_DTC, DTCSuppression43/DEM_WRONG_DTCORIGIN, DTCSuppression43/DEM_PENDING]
        arg SuppressionStatus: type=boolean, direction=OUT
      4 x error:
        E_NOT_OK: error-code=1
        DEM_WRONG_DTC: error-code=8
        DEM_WRONG_DTCORIGIN: error-code=9
        DEM_PENDING: error-code=4
    GeneralDiagnosticInfo422
      10 x operation:
        GetEventStatus: possible-error=GeneralDiagnosticInfo422/E_NOT_OK
          arg EventId: type=VDem42_EventIdType, direction=IN
          arg EventStatusByte: type=VDem42_UdsStatusByteType, direction=OUT
        GetEventFailed: possible-error=GeneralDiagnosticInfo422/E_NOT_OK
          arg EventId: type=VDem42_EventIdType, direction=IN
          arg EventFailed: type=boolean, direction=OUT
        GetEventTested: possible-error=GeneralDiagnosticInfo422/E_NOT_OK
          arg EventId: type=VDem42_EventIdType, direction=IN
          arg EventTested: type=boolean, direction=OUT
        GetDTCOfEvent: possible-error=[GeneralDiagnosticInfo422/E_NOT_OK, GeneralDiagnosticInfo422/DEM_E_NO_DTC_AVAILABLE]
          arg EventId: type=VDem42_EventIdType, direction=IN
          arg DTCFormat: type=VDem42_DTCFormatType, direction=IN
          arg DTCOfEvent: type=uint32, direction=OUT
        GetFaultDetectionCounter: possible-error=[GeneralDiagnosticInfo422/E_NOT_OK, GeneralDiagnosticInfo422/DEM_E_NO_FDC_AVAILABLE]
          arg EventId: type=VDem42_EventIdType, direction=IN
          arg FaultDetectionCounter: type=sint8, direction=OUT
        GetEventFreezeFrameData: possible-error=[GeneralDiagnosticInfo422/E_NOT_OK, GeneralDiagnosticInfo422/DEM_E_NODATAAVAILABLE, GeneralDiagnosticInfo422/DEM_E_WRONG_RECORDNUMBER, GeneralDiagnosticInfo422/DEM_E_WRONG_DIDNUMBER]
          5 x arg:
            EventId: type=VDem42_EventIdType, direction=IN
            RecordNumber: type=uint8, direction=IN
            ReportTotalRecord: type=boolean, direction=IN
            DataId: type=uint16, direction=IN
            DestBuffer: type=VDem42_MaxDataValueType, direction=OUT
        GetEventFreezeFrameDataEx: possible-error=[GeneralDiagnosticInfo422/E_NOT_OK, GeneralDiagnosticInfo422/DEM_E_WRONG_BUFFERSIZE, GeneralDiagnosticInfo422/DEM_E_NODATAAVAILABLE, GeneralDiagnosticInfo422/DEM_E_WRONG_RECORDNUMBER, GeneralDiagnosticInfo422/DEM_E_WRONG_DIDNUMBER]
          5 x arg:
            EventId: type=VDem42_EventIdType, direction=IN
            RecordNumber: type=uint8, direction=IN
            DataId: type=uint16, direction=IN
            DestBuffer: type=VDem42_MaxDataValueType, direction=OUT
            BufSize: type=uint16, direction=INOUT
        GetEventExtendedDataRecord: possible-error=[GeneralDiagnosticInfo422/E_NOT_OK, GeneralDiagnosticInfo422/DEM_E_NODATAAVAILABLE, GeneralDiagnosticInfo422/DEM_E_WRONG_RECORDNUMBER]
          arg EventId: type=VDem42_EventIdType, direction=IN
          arg RecordNumber: type=uint8, direction=IN
          arg DestBuffer: type=VDem42_MaxDataValueType, direction=OUT
        GetEventExtendedDataRecordEx: possible-error=[GeneralDiagnosticInfo422/E_NOT_OK, GeneralDiagnosticInfo422/DEM_E_WRONG_BUFFERSIZE, GeneralDiagnosticInfo422/DEM_E_NODATAAVAILABLE, GeneralDiagnosticInfo422/DEM_E_WRONG_RECORDNUMBER]
          4 x arg:
            EventId: type=VDem42_EventIdType, direction=IN
            RecordNumber: type=uint8, direction=IN
            DestBuffer: type=VDem42_MaxDataValueType, direction=OUT
            BufSize: type=uint16, direction=INOUT
        GetDebouncingOfEvent: possible-error=GeneralDiagnosticInfo422/E_NOT_OK
          arg EventId: type=VDem42_EventIdType, direction=IN
          arg DebouncingState: type=VDem42_DebouncingStateType, direction=OUT
      7 x error:
        E_NOT_OK: error-code=1
        DEM_E_NO_DTC_AVAILABLE: error-code=2
        DEM_E_NO_FDC_AVAILABLE: error-code=3
        DEM_E_WRONG_BUFFERSIZE: error-code=21
        DEM_E_NODATAAVAILABLE: error-code=48
        DEM_E_WRONG_RECORDNUMBER: error-code=49
        DEM_E_WRONG_DIDNUMBER: error-code=50
    DiagnosticInfo422
      10 x operation:
        GetEventStatus: possible-error=DiagnosticInfo422/E_NOT_OK
          arg EventStatusByte: type=VDem42_UdsStatusByteType, direction=OUT
        GetEventFailed: possible-error=DiagnosticInfo422/E_NOT_OK
          arg EventFailed: type=boolean, direction=OUT
        GetEventTested: possible-error=DiagnosticInfo422/E_NOT_OK
          arg EventTested: type=boolean, direction=OUT
        GetDTCOfEvent: possible-error=[DiagnosticInfo422/E_NOT_OK, DiagnosticInfo422/DEM_E_NO_DTC_AVAILABLE]
          arg DTCFormat: type=VDem42_DTCFormatType, direction=IN
          arg DTCOfEvent: type=uint32, direction=OUT
        GetFaultDetectionCounter: possible-error=[DiagnosticInfo422/E_NOT_OK, DiagnosticInfo422/DEM_E_NO_FDC_AVAILABLE]
          arg FaultDetectionCounter: type=sint8, direction=OUT
        GetEventFreezeFrameData: possible-error=[DiagnosticInfo422/E_NOT_OK, DiagnosticInfo422/DEM_E_NODATAAVAILABLE, DiagnosticInfo422/DEM_E_WRONG_RECORDNUMBER, DiagnosticInfo422/DEM_E_WRONG_DIDNUMBER]
          4 x arg:
            RecordNumber: type=uint8, direction=IN
            ReportTotalRecord: type=boolean, direction=IN
            DataId: type=uint16, direction=IN
            DestBuffer: type=VDem42_MaxDataValueType, direction=OUT
        GetEventFreezeFrameDataEx: possible-error=[DiagnosticInfo422/E_NOT_OK, DiagnosticInfo422/DEM_E_WRONG_BUFFERSIZE, DiagnosticInfo422/DEM_E_NODATAAVAILABLE, DiagnosticInfo422/DEM_E_WRONG_RECORDNUMBER, DiagnosticInfo422/DEM_E_WRONG_DIDNUMBER]
          4 x arg:
            RecordNumber: type=uint8, direction=IN
            DataId: type=uint16, direction=IN
            DestBuffer: type=VDem42_MaxDataValueType, direction=OUT
            BufSize: type=uint16, direction=INOUT
        GetEventExtendedDataRecord: possible-error=[DiagnosticInfo422/E_NOT_OK, DiagnosticInfo422/DEM_E_NODATAAVAILABLE, DiagnosticInfo422/DEM_E_WRONG_RECORDNUMBER]
          arg RecordNumber: type=uint8, direction=IN
          arg DestBuffer: type=VDem42_MaxDataValueType, direction=OUT
        GetEventExtendedDataRecordEx: possible-error=[DiagnosticInfo422/E_NOT_OK, DiagnosticInfo422/DEM_E_WRONG_BUFFERSIZE, DiagnosticInfo422/DEM_E_NODATAAVAILABLE, DiagnosticInfo422/DEM_E_WRONG_RECORDNUMBER]
          arg RecordNumber: type=uint8, direction=IN
          arg DestBuffer: type=VDem42_MaxDataValueType, direction=OUT
          arg BufSize: type=uint16, direction=INOUT
        GetDebouncingOfEvent: possible-error=DiagnosticInfo422/E_NOT_OK
          arg DebouncingState: type=VDem42_DebouncingStateType, direction=OUT
      7 x error:
        E_NOT_OK: error-code=1
        DEM_E_NO_DTC_AVAILABLE: error-code=2
        DEM_E_NO_FDC_AVAILABLE: error-code=3
        DEM_E_WRONG_BUFFERSIZE: error-code=21
        DEM_E_NODATAAVAILABLE: error-code=48
        DEM_E_WRONG_RECORDNUMBER: error-code=49
        DEM_E_WRONG_DIDNUMBER: error-code=50
    GeneralDiagnosticInfo43
      8 x operation:
        GetEventUdsStatus: possible-error=GeneralDiagnosticInfo43/E_NOT_OK
          arg EventId: type=Dem_EventIdType, direction=IN
          arg UDSStatusByte: type=Dem_UdsStatusByteType, direction=OUT
        GetEventFailed: possible-error=GeneralDiagnosticInfo43/E_NOT_OK
          arg EventId: type=Dem_EventIdType, direction=IN
          arg EventFailed: type=boolean, direction=OUT
        GetEventTested: possible-error=GeneralDiagnosticInfo43/E_NOT_OK
          arg EventId: type=Dem_EventIdType, direction=IN
          arg EventTested: type=boolean, direction=OUT
        GetDTCOfEvent: possible-error=[GeneralDiagnosticInfo43/E_NOT_OK, GeneralDiagnosticInfo43/DEM_E_NO_DTC_AVAILABLE]
          arg EventId: type=Dem_EventIdType, direction=IN
          arg DTCFormat: type=Dem_DTCFormatType, direction=IN
          arg DTCOfEvent: type=uint32, direction=OUT
        GetFaultDetectionCounter: possible-error=[GeneralDiagnosticInfo43/E_NOT_OK, GeneralDiagnosticInfo43/DEM_E_NO_FDC_AVAILABLE]
          arg EventId: type=Dem_EventIdType, direction=IN
          arg FaultDetectionCounter: type=sint8, direction=OUT
        GetEventFreezeFrameDataEx: possible-error=[GeneralDiagnosticInfo43/E_NOT_OK, DEM_BUFFER_TOO_SMALL, DEM_NO_SUCH_ELEMENT]
          5 x arg:
            EventId: type=Dem_EventIdType, direction=IN
            RecordNumber: type=uint8, direction=IN
            DataId: type=uint16, direction=IN
            DestBuffer: type=Dem_MaxDataValueType, direction=OUT
            BufSize: type=uint16, direction=INOUT
        GetEventExtendedDataRecordEx: possible-error=[GeneralDiagnosticInfo43/E_NOT_OK, DEM_BUFFER_TOO_SMALL, DEM_NO_SUCH_ELEMENT]
          4 x arg:
            EventId: type=Dem_EventIdType, direction=IN
            RecordNumber: type=uint8, direction=IN
            DestBuffer: type=Dem_MaxDataValueType, direction=OUT
            BufSize: type=uint16, direction=INOUT
        GetDebouncingOfEvent: possible-error=GeneralDiagnosticInfo43/E_NOT_OK
          arg EventId: type=Dem_EventIdType, direction=IN
          arg DebouncingState: type=Dem_DebouncingStateType, direction=OUT
      5 x error:
        E_NOT_OK: error-code=1
        DEM_E_NO_DTC_AVAILABLE: error-code=10
        DEM_E_NO_FDC_AVAILABLE: error-code=14
        DEM_BUFFER_TOO_SMALL: error-code=21
        DEM_NO_SUCH_ELEMENT: error-code=48
package /MICROSAR/vDem42_swc/ComponentTypes
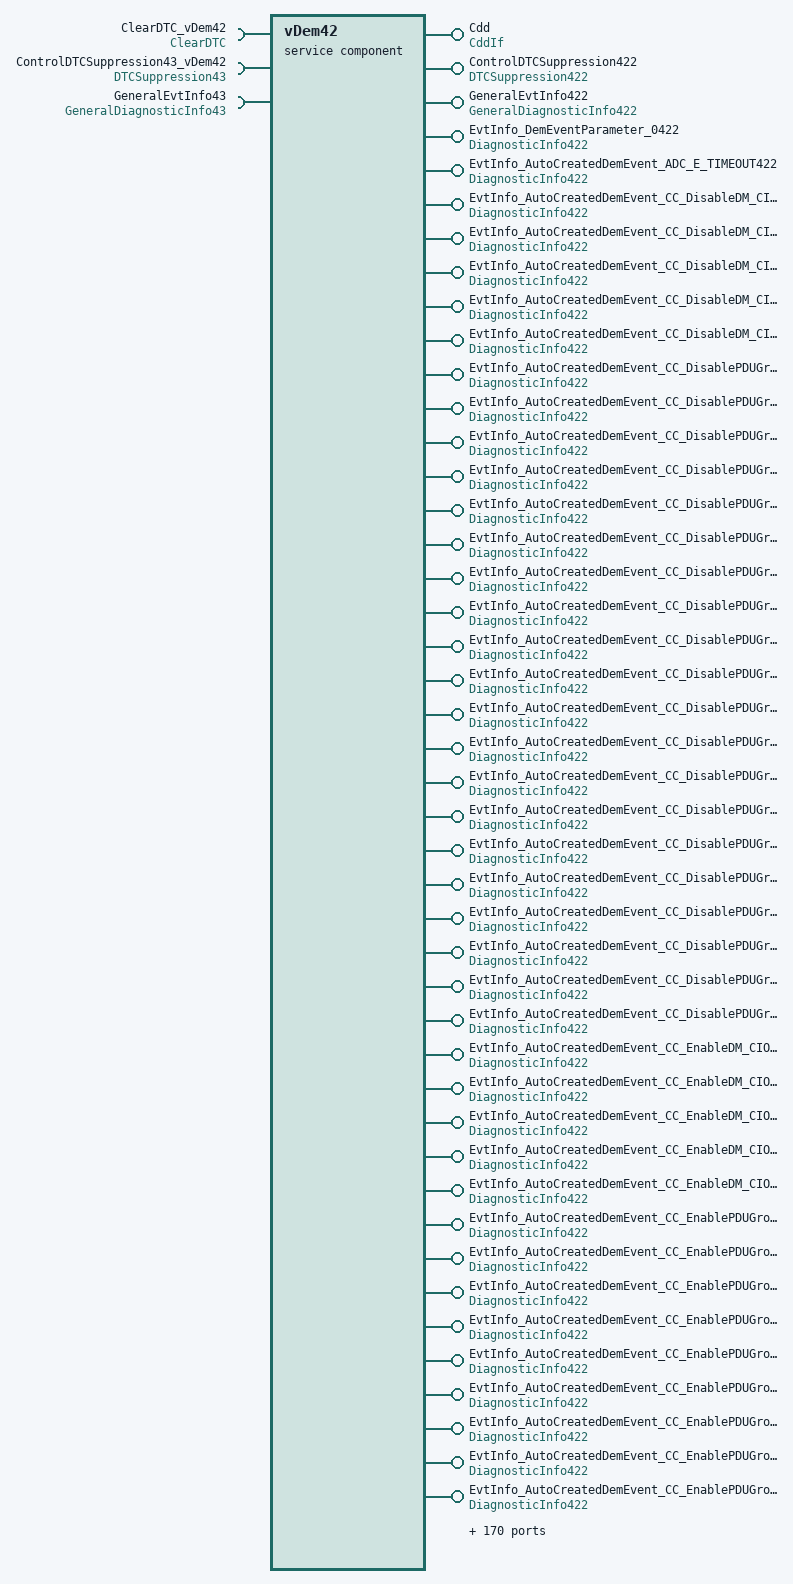
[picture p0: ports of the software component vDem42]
  service sw component type vDem42: category=SERVICE_COMPONENT
    provide port Cdd: provided-interface=CddIf
    provide port ControlDTCSuppression422: provided-interface=DTCSuppression422
    require port ClearDTC_vDem42: required-interface=ClearDTC
    require port ControlDTCSuppression43_vDem42: required-interface=DTCSuppression43
    provide port GeneralEvtInfo422: provided-interface=GeneralDiagnosticInfo422
    provide port EvtInfo_DemEventParameter_0422: provided-interface=DiagnosticInfo422
    require port GeneralEvtInfo43: required-interface=GeneralDiagnosticInfo43
    210 x provide port, all with provided-interface=DiagnosticInfo422:
      EvtInfo_AutoCreatedDemEvent_ADC_E_TIMEOUT422
      EvtInfo_AutoCreatedDemEvent_CC_DisableDM_CIOM_oBackbone1J1939_Rx_BC_405bc776_BswMReportFailToDemRef422
      EvtInfo_AutoCreatedDemEvent_CC_DisableDM_CIOM_oBackbone2_Rx_4e624434_BswMReportFailToDemRef422
      EvtInfo_AutoCreatedDemEvent_CC_DisableDM_CIOM_oCabSubnet_Rx_063a5fbc_BswMReportFailToDemRef422
      EvtInfo_AutoCreatedDemEvent_CC_DisableDM_CIOM_oFMSNet_Rx_BC_dd2c1510_BswMReportFailToDemRef422
      EvtInfo_AutoCreatedDemEvent_CC_DisableDM_CIOM_oSecuritySubnet_Rx_3a3c1dbc_BswMReportFailToDemRef422
      EvtInfo_AutoCreatedDemEvent_CC_DisablePDUGroup_CIOM_oBackbone1J1939_Rx_BC_405bc776_BswMReportFailToDemRef422
      EvtInfo_AutoCreatedDemEvent_CC_DisablePDUGroup_CIOM_oBackbone1J1939_Tx_0x31_BC_3782f500_BswMReportFailToDemRef422
      EvtInfo_AutoCreatedDemEvent_CC_DisablePDUGroup_CIOM_oBackbone2_Rx_4e624434_BswMReportFailToDemRef422
      EvtInfo_AutoCreatedDemEvent_CC_DisablePDUGroup_CIOM_oBackbone2_Tx_1838e3b2_BswMReportFailToDemRef422
      EvtInfo_AutoCreatedDemEvent_CC_DisablePDUGroup_CIOM_oCabSubnet_Rx_063a5fbc_BswMReportFailToDemRef422
      EvtInfo_AutoCreatedDemEvent_CC_DisablePDUGroup_CIOM_oCabSubnet_Tx_5060f83a_BswMReportFailToDemRef422
      EvtInfo_AutoCreatedDemEvent_CC_DisablePDUGroup_CIOM_oFMSNet_Rx_BC_dd2c1510_BswMReportFailToDemRef422
      EvtInfo_AutoCreatedDemEvent_CC_DisablePDUGroup_CIOM_oFMSNet_Tx_0x31_BC_38fc8c7d_BswMReportFailToDemRef422
      EvtInfo_AutoCreatedDemEvent_CC_DisablePDUGroup_CIOM_oLIN00_Rx_dd181faa_BswMReportFailToDemRef422
      EvtInfo_AutoCreatedDemEvent_CC_DisablePDUGroup_CIOM_oLIN00_Tx_8b42b82c_BswMReportFailToDemRef422
      EvtInfo_AutoCreatedDemEvent_CC_DisablePDUGroup_CIOM_oLIN01_Rx_65a478cf_BswMReportFailToDemRef422
      EvtInfo_AutoCreatedDemEvent_CC_DisablePDUGroup_CIOM_oLIN01_Tx_33fedf49_BswMReportFailToDemRef422
      EvtInfo_AutoCreatedDemEvent_CC_DisablePDUGroup_CIOM_oLIN02_Rx_7711d721_BswMReportFailToDemRef422
      EvtInfo_AutoCreatedDemEvent_CC_DisablePDUGroup_CIOM_oLIN02_Tx_214b70a7_BswMReportFailToDemRef422
      EvtInfo_AutoCreatedDemEvent_CC_DisablePDUGroup_CIOM_oLIN03_Rx_cfadb044_BswMReportFailToDemRef422
      EvtInfo_AutoCreatedDemEvent_CC_DisablePDUGroup_CIOM_oLIN03_Tx_99f717c2_BswMReportFailToDemRef422
      EvtInfo_AutoCreatedDemEvent_CC_DisablePDUGroup_CIOM_oLIN04_Rx_527a88fd_BswMReportFailToDemRef422
      EvtInfo_AutoCreatedDemEvent_CC_DisablePDUGroup_CIOM_oLIN04_Tx_04202f7b_BswMReportFailToDemRef422
      EvtInfo_AutoCreatedDemEvent_CC_DisablePDUGroup_CIOM_oSecuritySubnet_Rx_3a3c1dbc_BswMReportFailToDemRef422
      EvtInfo_AutoCreatedDemEvent_CC_DisablePDUGroup_CIOM_oSecuritySubnet_Tx_6c66ba3a_BswMReportFailToDemRef422
      EvtInfo_AutoCreatedDemEvent_CC_EnableDM_CIOM_oBackbone1J1939_Rx_BC_405bc776_BswMReportFailToDemRef422
      EvtInfo_AutoCreatedDemEvent_CC_EnableDM_CIOM_oBackbone2_Rx_4e624434_BswMReportFailToDemRef422
      EvtInfo_AutoCreatedDemEvent_CC_EnableDM_CIOM_oCabSubnet_Rx_063a5fbc_BswMReportFailToDemRef422
      EvtInfo_AutoCreatedDemEvent_CC_EnableDM_CIOM_oFMSNet_Rx_BC_dd2c1510_BswMReportFailToDemRef422
      EvtInfo_AutoCreatedDemEvent_CC_EnableDM_CIOM_oSecuritySubnet_Rx_3a3c1dbc_BswMReportFailToDemRef422
      EvtInfo_AutoCreatedDemEvent_CC_EnablePDUGroup_CIOM_oBackbone1J1939_Rx_BC_405bc776_BswMReportFailToDemRef422
      EvtInfo_AutoCreatedDemEvent_CC_EnablePDUGroup_CIOM_oBackbone1J1939_Tx_0x31_BC_3782f500_BswMReportFailToDemRef422
      EvtInfo_AutoCreatedDemEvent_CC_EnablePDUGroup_CIOM_oBackbone2_Rx_4e624434_BswMReportFailToDemRef422
      EvtInfo_AutoCreatedDemEvent_CC_EnablePDUGroup_CIOM_oBackbone2_Tx_1838e3b2_BswMReportFailToDemRef422
      EvtInfo_AutoCreatedDemEvent_CC_EnablePDUGroup_CIOM_oCabSubnet_Rx_063a5fbc_BswMReportFailToDemRef422
      EvtInfo_AutoCreatedDemEvent_CC_EnablePDUGroup_CIOM_oCabSubnet_Tx_5060f83a_BswMReportFailToDemRef422
      EvtInfo_AutoCreatedDemEvent_CC_EnablePDUGroup_CIOM_oFMSNet_Rx_BC_dd2c1510_BswMReportFailToDemRef422
      EvtInfo_AutoCreatedDemEvent_CC_EnablePDUGroup_CIOM_oFMSNet_Tx_0x31_BC_38fc8c7d_BswMReportFailToDemRef422
      EvtInfo_AutoCreatedDemEvent_CC_EnablePDUGroup_CIOM_oLIN00_Rx_dd181faa_BswMReportFailToDemRef422
      EvtInfo_AutoCreatedDemEvent_CC_EnablePDUGroup_CIOM_oLIN00_Tx_8b42b82c_BswMReportFailToDemRef422
      EvtInfo_AutoCreatedDemEvent_CC_EnablePDUGroup_CIOM_oLIN01_Rx_65a478cf_BswMReportFailToDemRef422
      EvtInfo_AutoCreatedDemEvent_CC_EnablePDUGroup_CIOM_oLIN01_Tx_33fedf49_BswMReportFailToDemRef422
      EvtInfo_AutoCreatedDemEvent_CC_EnablePDUGroup_CIOM_oLIN02_Rx_7711d721_BswMReportFailToDemRef422
      EvtInfo_AutoCreatedDemEvent_CC_EnablePDUGroup_CIOM_oLIN02_Tx_214b70a7_BswMReportFailToDemRef422
      EvtInfo_AutoCreatedDemEvent_CC_EnablePDUGroup_CIOM_oLIN03_Rx_cfadb044_BswMReportFailToDemRef422
      EvtInfo_AutoCreatedDemEvent_CC_EnablePDUGroup_CIOM_oLIN03_Tx_99f717c2_BswMReportFailToDemRef422
      EvtInfo_AutoCreatedDemEvent_CC_EnablePDUGroup_CIOM_oLIN04_Rx_527a88fd_BswMReportFailToDemRef422
      EvtInfo_AutoCreatedDemEvent_CC_EnablePDUGroup_CIOM_oLIN04_Tx_04202f7b_BswMReportFailToDemRef422
      EvtInfo_AutoCreatedDemEvent_CC_EnablePDUGroup_CIOM_oSecuritySubnet_Rx_3a3c1dbc_BswMReportFailToDemRef422
      EvtInfo_AutoCreatedDemEvent_CC_EnablePDUGroup_CIOM_oSecuritySubnet_Tx_6c66ba3a_BswMReportFailToDemRef422
      EvtInfo_AutoCreatedDemEvent_CC_J1939RmStateSwitch_CN_Backbone1J1939_0b1f4bae_CIOM_4d5cd289_J1939RM_STATE_OFFLINE_BswMRe_f9c55035
      EvtInfo_AutoCreatedDemEvent_CC_J1939RmStateSwitch_CN_Backbone1J1939_0b1f4bae_CIOM_4d5cd289_J1939RM_STATE_ONLINE_BswMRep_5375d7eb
      EvtInfo_AutoCreatedDemEvent_CC_J1939RmStateSwitch_CN_FMSNet_fce1aae5_CIOM_3a3d59b1_J1939RM_STATE_OFFLINE_BswMReportFail_5f9bde08
      EvtInfo_AutoCreatedDemEvent_CC_J1939RmStateSwitch_CN_FMSNet_fce1aae5_CIOM_3a3d59b1_J1939RM_STATE_ONLINE_BswMReportFailT_e97c0723
      EvtInfo_AutoCreatedDemEvent_CHNL_53cce282_CANSM_E_BUS_OFF422
      EvtInfo_AutoCreatedDemEvent_CHNL_53cce282_CANSM_E_MODE_REQUEST_TIMEOUT422
      EvtInfo_AutoCreatedDemEvent_CHNL_17344684_CANSM_E_BUS_OFF422
      EvtInfo_AutoCreatedDemEvent_CHNL_17344684_CANSM_E_MODE_REQUEST_TIMEOUT422
      EvtInfo_AutoCreatedDemEvent_CHNL_a6b6a922_CANSM_E_BUS_OFF422
      EvtInfo_AutoCreatedDemEvent_CHNL_a6b6a922_CANSM_E_MODE_REQUEST_TIMEOUT422
      EvtInfo_AutoCreatedDemEvent_CHNL_df893ad5_CANSM_E_BUS_OFF422
      EvtInfo_AutoCreatedDemEvent_CHNL_df893ad5_CANSM_E_MODE_REQUEST_TIMEOUT422
      EvtInfo_AutoCreatedDemEvent_CHNL_e058b4ae_CANSM_E_BUS_OFF422
      EvtInfo_AutoCreatedDemEvent_CHNL_e058b4ae_CANSM_E_MODE_REQUEST_TIMEOUT422
      EvtInfo_AutoCreatedDemEvent_ECUM_E_ALL_RUN_REQUESTS_KILLED422
      EvtInfo_AutoCreatedDemEvent_ECUM_E_CONFIGURATION_DATA_INCONSISTENT422
      EvtInfo_AutoCreatedDemEvent_ECUM_E_IMPROPER_CALLER422
      EvtInfo_AutoCreatedDemEvent_ECUM_E_RAM_CHECK_FAILED422
      EvtInfo_AutoCreatedDemEvent_ESH_Action_CancelNvMWriteAll_BswMReportFailToDemRef422
      EvtInfo_AutoCreatedDemEvent_ESH_Action_CancelWriteAllTimer_Start_BswMReportFailToDemRef422
      EvtInfo_AutoCreatedDemEvent_ESH_Action_CancelWriteAllTimer_Stop_BswMReportFailToDemRef422
      EvtInfo_AutoCreatedDemEvent_ESH_Action_ComMAllow_CN_Backbone1J1939_0b1f4bae_BswMReportFailToDemRef422
      EvtInfo_AutoCreatedDemEvent_ESH_Action_ComMAllow_CN_Backbone1J1939_0b1f4bae_BswMReportFailToDemRef_1422
      EvtInfo_AutoCreatedDemEvent_ESH_Action_ComMAllow_CN_Backbone2_78967e2c_BswMReportFailToDemRef422
      EvtInfo_AutoCreatedDemEvent_ESH_Action_ComMAllow_CN_Backbone2_78967e2c_BswMReportFailToDemRef_1422
      EvtInfo_AutoCreatedDemEvent_ESH_Action_ComMAllow_CN_CabSubnet_9ea693f1_BswMReportFailToDemRef422
      EvtInfo_AutoCreatedDemEvent_ESH_Action_ComMAllow_CN_CabSubnet_9ea693f1_BswMReportFailToDemRef_1422
      EvtInfo_AutoCreatedDemEvent_ESH_Action_ComMAllow_CN_FMSNet_fce1aae5_BswMReportFailToDemRef422
      EvtInfo_AutoCreatedDemEvent_ESH_Action_ComMAllow_CN_FMSNet_fce1aae5_BswMReportFailToDemRef_1422
      EvtInfo_AutoCreatedDemEvent_ESH_Action_ComMAllow_CN_LIN00_2cd9a7df_BswMReportFailToDemRef422
      EvtInfo_AutoCreatedDemEvent_ESH_Action_ComMAllow_CN_LIN00_2cd9a7df_BswMReportFailToDemRef_1422
      EvtInfo_AutoCreatedDemEvent_ESH_Action_ComMAllow_CN_LIN01_5bde9749_BswMReportFailToDemRef422
      EvtInfo_AutoCreatedDemEvent_ESH_Action_ComMAllow_CN_LIN01_5bde9749_BswMReportFailToDemRef_1422
      EvtInfo_AutoCreatedDemEvent_ESH_Action_ComMAllow_CN_LIN02_c2d7c6f3_BswMReportFailToDemRef422
      EvtInfo_AutoCreatedDemEvent_ESH_Action_ComMAllow_CN_LIN02_c2d7c6f3_BswMReportFailToDemRef_1422
      EvtInfo_AutoCreatedDemEvent_ESH_Action_ComMAllow_CN_LIN03_b5d0f665_BswMReportFailToDemRef422
      EvtInfo_AutoCreatedDemEvent_ESH_Action_ComMAllow_CN_LIN03_b5d0f665_BswMReportFailToDemRef_1422
      EvtInfo_AutoCreatedDemEvent_ESH_Action_ComMAllow_CN_LIN04_2bb463c6_BswMReportFailToDemRef422
      EvtInfo_AutoCreatedDemEvent_ESH_Action_ComMAllow_CN_LIN04_2bb463c6_BswMReportFailToDemRef_1422
      EvtInfo_AutoCreatedDemEvent_ESH_Action_ComMAllow_CN_SecuritySubnet_e7a0ee54_BswMReportFailToDemRef422
      EvtInfo_AutoCreatedDemEvent_ESH_Action_ComMAllow_CN_SecuritySubnet_e7a0ee54_BswMReportFailToDemRef_1422
      EvtInfo_AutoCreatedDemEvent_ESH_Action_ComMCheckPendingRequests_BswMReportFailToDemRef422
      EvtInfo_AutoCreatedDemEvent_ESH_Action_ComMCheckPendingRequests_BswMReportFailToDemRef_1422
      EvtInfo_AutoCreatedDemEvent_ESH_Action_ComMCheckPendingRequests_BswMReportFailToDemRef_2422
      EvtInfo_AutoCreatedDemEvent_ESH_Action_ComMDisallow_CN_Backbone1J1939_0b1f4bae_BswMReportFailToDemRef422
      EvtInfo_AutoCreatedDemEvent_ESH_Action_ComMDisallow_CN_Backbone2_78967e2c_BswMReportFailToDemRef422
      EvtInfo_AutoCreatedDemEvent_ESH_Action_ComMDisallow_CN_CabSubnet_9ea693f1_BswMReportFailToDemRef422
      EvtInfo_AutoCreatedDemEvent_ESH_Action_ComMDisallow_CN_FMSNet_fce1aae5_BswMReportFailToDemRef422
      EvtInfo_AutoCreatedDemEvent_ESH_Action_ComMDisallow_CN_LIN00_2cd9a7df_BswMReportFailToDemRef422
      EvtInfo_AutoCreatedDemEvent_ESH_Action_ComMDisallow_CN_LIN01_5bde9749_BswMReportFailToDemRef422
      EvtInfo_AutoCreatedDemEvent_ESH_Action_ComMDisallow_CN_LIN02_c2d7c6f3_BswMReportFailToDemRef422
      EvtInfo_AutoCreatedDemEvent_ESH_Action_ComMDisallow_CN_LIN03_b5d0f665_BswMReportFailToDemRef422
      EvtInfo_AutoCreatedDemEvent_ESH_Action_ComMDisallow_CN_LIN04_2bb463c6_BswMReportFailToDemRef422
      EvtInfo_AutoCreatedDemEvent_ESH_Action_ComMDisallow_CN_SecuritySubnet_e7a0ee54_BswMReportFailToDemRef422
      EvtInfo_AutoCreatedDemEvent_ESH_Action_DemInit_BswMReportFailToDemRef422
      EvtInfo_AutoCreatedDemEvent_ESH_Action_DemInitialized_BswMReportFailToDemRef422
      EvtInfo_AutoCreatedDemEvent_ESH_Action_DemNotInitialized_BswMReportFailToDemRef422
      EvtInfo_AutoCreatedDemEvent_ESH_Action_DemShutdown_BswMReportFailToDemRef422
      EvtInfo_AutoCreatedDemEvent_ESH_Action_ESH_PostRun_BswMReportFailToDemRef422
      EvtInfo_AutoCreatedDemEvent_ESH_Action_ESH_PrepShutdown_BswMReportFailToDemRef422
      EvtInfo_AutoCreatedDemEvent_ESH_Action_ESH_PrepShutdown_BswMReportFailToDemRef_1422
      EvtInfo_AutoCreatedDemEvent_ESH_Action_ESH_Run_BswMReportFailToDemRef422
      EvtInfo_AutoCreatedDemEvent_ESH_Action_ESH_Run_BswMReportFailToDemRef_1422
      EvtInfo_AutoCreatedDemEvent_ESH_Action_ESH_WaitForNvm_BswMReportFailToDemRef422
      EvtInfo_AutoCreatedDemEvent_ESH_Action_ESH_Wakeup_BswMReportFailToDemRef422
      EvtInfo_AutoCreatedDemEvent_ESH_Action_ESH_Wakeup_BswMReportFailToDemRef_1422
      EvtInfo_AutoCreatedDemEvent_ESH_Action_EcuMClearValidatedWakeupEvents_BswMReportFailToDemRef422
      EvtInfo_AutoCreatedDemEvent_ESH_Action_EcuMGoToSelectedShutdownTarget_BswMReportFailToDemRef422
      EvtInfo_AutoCreatedDemEvent_ESH_Action_EnterExclusiveArea_BswMReportFailToDemRef422
      EvtInfo_AutoCreatedDemEvent_ESH_Action_EnterExclusiveArea_BswMReportFailToDemRef_1422
      EvtInfo_AutoCreatedDemEvent_ESH_Action_ExitExclusiveArea_BswMReportFailToDemRef422
      EvtInfo_AutoCreatedDemEvent_ESH_Action_ExitExclusiveArea_BswMReportFailToDemRef_1422
      EvtInfo_AutoCreatedDemEvent_ESH_Action_NvMWriteAll_BswMReportFailToDemRef422
      EvtInfo_AutoCreatedDemEvent_ESH_Action_OnEnterPostRun_BswMReportFailToDemRef422
      EvtInfo_AutoCreatedDemEvent_ESH_Action_OnEnterPrepShutdown_BswMReportFailToDemRef422
      EvtInfo_AutoCreatedDemEvent_ESH_Action_OnEnterPrepShutdown_BswMReportFailToDemRef_1422
      EvtInfo_AutoCreatedDemEvent_ESH_Action_OnEnterRun_BswMReportFailToDemRef422
      EvtInfo_AutoCreatedDemEvent_ESH_Action_OnEnterRun_BswMReportFailToDemRef_1422
      EvtInfo_AutoCreatedDemEvent_ESH_Action_OnEnterShutdown_BswMReportFailToDemRef422
      EvtInfo_AutoCreatedDemEvent_ESH_Action_OnEnterWaitForNvm_BswMReportFailToDemRef422
      EvtInfo_AutoCreatedDemEvent_ESH_Action_OnEnterWakeup_BswMReportFailToDemRef422
      EvtInfo_AutoCreatedDemEvent_ESH_Action_OnEnterWakeup_BswMReportFailToDemRef_1422
      EvtInfo_AutoCreatedDemEvent_ESH_Action_SelfRunRequestTimer_Start_BswMReportFailToDemRef422
      EvtInfo_AutoCreatedDemEvent_ESH_Action_SelfRunRequestTimer_Start_BswMReportFailToDemRef_1422
      EvtInfo_AutoCreatedDemEvent_ESH_Action_SwitchPostRun_BswMReportFailToDemRef422
      EvtInfo_AutoCreatedDemEvent_ESH_Action_SwitchRun_BswMReportFailToDemRef422
      EvtInfo_AutoCreatedDemEvent_ESH_Action_SwitchRun_BswMReportFailToDemRef_1422
      EvtInfo_AutoCreatedDemEvent_ESH_Action_SwitchShutdown_BswMReportFailToDemRef422
      EvtInfo_AutoCreatedDemEvent_ESH_Action_SwitchShutdown_BswMReportFailToDemRef_1422
      EvtInfo_AutoCreatedDemEvent_ESH_Action_SwitchWakeup_BswMReportFailToDemRef422
      EvtInfo_AutoCreatedDemEvent_ESH_Action_SwitchWakeup_BswMReportFailToDemRef_1422
      EvtInfo_AutoCreatedDemEvent_ESH_Action_WriteAllTimer_Start_BswMReportFailToDemRef422
      EvtInfo_AutoCreatedDemEvent_ESH_Action_WriteAllTimer_Stop_BswMReportFailToDemRef422
      EvtInfo_AutoCreatedDemEvent_ESH_Action_WriteAllTimer_Stop_BswMReportFailToDemRef_1422
      EvtInfo_AutoCreatedDemEvent_ESH_DemInit_BswMReportFailToDemRef422
      EvtInfo_AutoCreatedDemEvent_ESH_PostRunNested_BswMReportFailToDemRef422
      EvtInfo_AutoCreatedDemEvent_ESH_PostRunToPrepNested_BswMReportFailToDemRef422
      EvtInfo_AutoCreatedDemEvent_ESH_RunToPostRunNested_BswMReportFailToDemRef422
      EvtInfo_AutoCreatedDemEvent_FLS_E_COMPARE_FAILED422
      EvtInfo_AutoCreatedDemEvent_FLS_E_ERASE_FAILED422
      EvtInfo_AutoCreatedDemEvent_FLS_E_READ_FAILED422
      EvtInfo_AutoCreatedDemEvent_FLS_E_UNEXPECTED_FLASH_ID422
      EvtInfo_AutoCreatedDemEvent_FLS_E_WRITE_FAILED422
      EvtInfo_AutoCreatedDemEvent_GPT_E_TIMEOUT422
      EvtInfo_AutoCreatedDemEvent_INIT_Action_BrsHw_EnableHwAccess_BswMReportFailToDemRef422
      EvtInfo_AutoCreatedDemEvent_INIT_Action_CanIf_Init_BswMReportFailToDemRef422
      EvtInfo_AutoCreatedDemEvent_INIT_Action_CanNm_Init_BswMReportFailToDemRef422
      EvtInfo_AutoCreatedDemEvent_INIT_Action_CanSM_Init_BswMReportFailToDemRef422
      EvtInfo_AutoCreatedDemEvent_INIT_Action_CanTp_Init_BswMReportFailToDemRef422
      EvtInfo_AutoCreatedDemEvent_INIT_Action_Can_Init_BswMReportFailToDemRef422
      EvtInfo_AutoCreatedDemEvent_INIT_Action_ComM_Init_BswMReportFailToDemRef422
      EvtInfo_AutoCreatedDemEvent_INIT_Action_Com_Init_BswMReportFailToDemRef422
      EvtInfo_AutoCreatedDemEvent_INIT_Action_Dcm_Init_BswMReportFailToDemRef422
      EvtInfo_AutoCreatedDemEvent_INIT_Action_Dem_Init_BswMReportFailToDemRef422
      EvtInfo_AutoCreatedDemEvent_INIT_Action_EnableInterrupts_BswMReportFailToDemRef422
      EvtInfo_AutoCreatedDemEvent_INIT_Action_Fee_Init_BswMReportFailToDemRef422
      EvtInfo_AutoCreatedDemEvent_INIT_Action_Issm_Init_BswMReportFailToDemRef422
      EvtInfo_AutoCreatedDemEvent_INIT_Action_J1939Nm_Init_BswMReportFailToDemRef422
      EvtInfo_AutoCreatedDemEvent_INIT_Action_J1939Rm_Init_BswMReportFailToDemRef422
      EvtInfo_AutoCreatedDemEvent_INIT_Action_J1939Tp_Init_BswMReportFailToDemRef422
      EvtInfo_AutoCreatedDemEvent_INIT_Action_LinIf_Init_BswMReportFailToDemRef422
      EvtInfo_AutoCreatedDemEvent_INIT_Action_LinSM_Init_BswMReportFailToDemRef422
      EvtInfo_AutoCreatedDemEvent_INIT_Action_LinTp_Init_BswMReportFailToDemRef422
      EvtInfo_AutoCreatedDemEvent_INIT_Action_Lin_Init_BswMReportFailToDemRef422
      EvtInfo_AutoCreatedDemEvent_INIT_Action_Nm_Init_BswMReportFailToDemRef422
      EvtInfo_AutoCreatedDemEvent_INIT_Action_NvMReadAll_BswMReportFailToDemRef422
      EvtInfo_AutoCreatedDemEvent_INIT_Action_NvM_Init_BswMReportFailToDemRef422
      EvtInfo_AutoCreatedDemEvent_INIT_Action_PduR_Init_BswMReportFailToDemRef422
      EvtInfo_AutoCreatedDemEvent_INIT_Action_RteStart_BswMReportFailToDemRef422
      EvtInfo_AutoCreatedDemEvent_J1939NM_E_ADDRESS_LOST422
      EvtInfo_AutoCreatedDemEvent_J1939TpConfiguration_J1939TP_E_COMMUNICATION422
      EvtInfo_AutoCreatedDemEvent_LIN_E_TIMEOUT422
      EvtInfo_AutoCreatedDemEvent_MCL_E_DMA_BUS422
      EvtInfo_AutoCreatedDemEvent_MCL_E_DMA_DESCRIPTOR422
      EvtInfo_AutoCreatedDemEvent_MCL_E_DMA_ECC422
      EvtInfo_AutoCreatedDemEvent_MCL_E_DMA_INCONSISTENCY422
      EvtInfo_AutoCreatedDemEvent_MCL_E_DMA_PRIORITY422
      EvtInfo_AutoCreatedDemEvent_MCL_E_DMA_UNRECOGNIZED422
      EvtInfo_AutoCreatedDemEvent_MCU_E_CLOCK_FAILURE422
      EvtInfo_AutoCreatedDemEvent_MCU_E_INVALIDMODE_CONFIG422
      EvtInfo_AutoCreatedDemEvent_MCU_E_SSCM_CER_FAILURE422
      EvtInfo_AutoCreatedDemEvent_MCU_E_TIMEOUT_FAILURE422
      EvtInfo_AutoCreatedDemEvent_NVM_E_INTEGRITY_FAILED422
      EvtInfo_AutoCreatedDemEvent_NVM_E_LOSS_OF_REDUNDANCY422
      EvtInfo_AutoCreatedDemEvent_NVM_E_QUEUE_OVERFLOW422
      EvtInfo_AutoCreatedDemEvent_NVM_E_REQ_FAILED422
      EvtInfo_AutoCreatedDemEvent_NVM_E_VERIFY_FAILED422
      EvtInfo_AutoCreatedDemEvent_NVM_E_WRITE_PROTECTED422
      EvtInfo_AutoCreatedDemEvent_NVM_E_WRONG_BLOCK_ID422
      EvtInfo_AutoCreatedDemEvent_SPI_E_HARDWARE_ERROR422
      EvtInfo_AutoCreatedDemEvent_SpiDriver_SPI_E_HARDWARE_ERROR422
      EvtInfo_AutoCreatedDemEvent_WDG_E_CORRUPT_CONFIG422
      EvtInfo_AutoCreatedDemEvent_WDG_E_DISABLE_REJECTED422
      EvtInfo_AutoCreatedDemEvent_WDG_E_FORBIDDEN_INVOCATION422
      EvtInfo_AutoCreatedDemEvent_WDG_E_INVALID_CALL422
      EvtInfo_AutoCreatedDemEvent_WDG_E_INVALID_PARAMETER422
      EvtInfo_AutoCreatedDemEvent_WDG_E_MODE_FAILED422
      EvtInfo_AutoCreatedDemEvent_WDG_E_UNLOCKED422
      EvtInfo_DEM_EVENT_StartApplication422
    behavior vDem42InternalBehavior: handle-termination-and-restart=NO-SUPPORT, included-data-type-set=data-type=[Dem_DTCFormatType, Dem_DTCOriginType, Dem_UdsStatusByteType, Dem_EventIdType, Dem_MaxDataValueType, Dem_DebouncingStateType, VDem42_DTCFormatType, VDem42_DTCOriginType, VDem42_UdsStatusByteType, VDem42_EventIdType, VDem42_MaxDataValueType, VDem42_DebouncingStateType]
      2123 x operation invoked event:
        OpEventClearDTC_ClearDTC_Cdd: start-on-event=ClearDTC, operation=Cdd.ClearDTC
        OpEventSetDTCSuppression_SetDTCSuppression_ControlDTCSuppression422: start-on-event=SetDTCSuppression, operation=ControlDTCSuppression422.SetDTCSuppression
        OpEventGetDTCSuppression_GetDTCSuppression_ControlDTCSuppression422: start-on-event=GetDTCSuppression, operation=ControlDTCSuppression422.GetDTCSuppression
        OpEventGetEventStatus_GetEventStatus_GeneralEvtInfo422: start-on-event=GetEventStatus, operation=GeneralEvtInfo422.GetEventStatus
        OpEventGetEventStatus_GetEventStatus_EvtInfo_DemEventParameter_0422: start-on-event=GetEventStatus, operation=EvtInfo_DemEventParameter_0422.GetEventStatus
        OpEventGetEventFailed_GetEventFailed_GeneralEvtInfo422: start-on-event=GetEventFailed, operation=GeneralEvtInfo422.GetEventFailed
        OpEventGetEventFailed_GetEventFailed_EvtInfo_DemEventParameter_0422: start-on-event=GetEventFailed, operation=EvtInfo_DemEventParameter_0422.GetEventFailed
        OpEventGetEventTested_GetEventTested_GeneralEvtInfo422: start-on-event=GetEventTested, operation=GeneralEvtInfo422.GetEventTested
        OpEventGetEventTested_GetEventTested_EvtInfo_DemEventParameter_0422: start-on-event=GetEventTested, operation=EvtInfo_DemEventParameter_0422.GetEventTested
        OpEventGetDTCOfEvent_GetDTCOfEvent_GeneralEvtInfo422: start-on-event=GetDTCOfEvent, operation=GeneralEvtInfo422.GetDTCOfEvent
        OpEventGetDTCOfEvent_GetDTCOfEvent_EvtInfo_DemEventParameter_0422: start-on-event=GetDTCOfEvent, operation=EvtInfo_DemEventParameter_0422.GetDTCOfEvent
        OpEventGetFaultDetectionCounter_GetFaultDetectionCounter_GeneralEvtInfo422: start-on-event=GetFaultDetectionCounter, operation=GeneralEvtInfo422.GetFaultDetectionCounter
        OpEventGetFaultDetectionCounter_GetFaultDetectionCounter_EvtInfo_DemEventParameter_0422: start-on-event=GetFaultDetectionCounter, operation=EvtInfo_DemEventParameter_0422.GetFaultDetectionCounter
        OpEventGetEventFreezeFrameData_GetEventFreezeFrameData_GeneralEvtInfo422: start-on-event=GetEventFreezeFrameData, operation=GeneralEvtInfo422.GetEventFreezeFrameData
        OpEventGetEventFreezeFrameData_GetEventFreezeFrameData_EvtInfo_DemEventParameter_0422: start-on-event=GetEventFreezeFrameData, operation=EvtInfo_DemEventParameter_0422.GetEventFreezeFrameData
        OpEventGetEventFreezeFrameDataEx_GetEventFreezeFrameDataEx_GeneralEvtInfo422: start-on-event=GetEventFreezeFrameDataEx, operation=GeneralEvtInfo422.GetEventFreezeFrameDataEx
        OpEventGetEventFreezeFrameDataEx_GetEventFreezeFrameDataEx_EvtInfo_DemEventParameter_0422: start-on-event=GetEventFreezeFrameDataEx, operation=EvtInfo_DemEventParameter_0422.GetEventFreezeFrameDataEx
        OpEventGetEventExtendedDataRecord_GetEventExtendedDataRecord_GeneralEvtInfo422: start-on-event=GetEventExtendedDataRecord, operation=GeneralEvtInfo422.GetEventExtendedDataRecord
        OpEventGetEventExtendedDataRecord_GetEventExtendedDataRecord_EvtInfo_DemEventParameter_0422: start-on-event=GetEventExtendedDataRecord, operation=EvtInfo_DemEventParameter_0422.GetEventExtendedDataRecord
        OpEventGetEventExtendedDataRecordEx_GetEventExtendedDataRecordEx_GeneralEvtInfo422: start-on-event=GetEventExtendedDataRecordEx, operation=GeneralEvtInfo422.GetEventExtendedDataRecordEx
        OpEventGetEventExtendedDataRecordEx_GetEventExtendedDataRecordEx_EvtInfo_DemEventParameter_0422: start-on-event=GetEventExtendedDataRecordEx, operation=EvtInfo_DemEventParameter_0422.GetEventExtendedDataRecordEx
        OpEventGetDebouncingOfEvent_GetDebouncingOfEvent_GeneralEvtInfo422: start-on-event=GetDebouncingOfEvent, operation=GeneralEvtInfo422.GetDebouncingOfEvent
        OpEventGetDebouncingOfEvent_GetDebouncingOfEvent_EvtInfo_DemEventParameter_0422: start-on-event=GetDebouncingOfEvent, operation=EvtInfo_DemEventParameter_0422.GetDebouncingOfEvent
        OpEventGetEventStatus_GetEventStatus_EvtInfo_AutoCreatedDemEvent_ADC_E_TIMEOUT422: start-on-event=GetEventStatus, operation=EvtInfo_AutoCreatedDemEvent_ADC_E_TIMEOUT422.GetEventStatus
        OpEventGetEventStatus_GetEventStatus_EvtInfo_AutoCreatedDemEvent_CC_DisableDM_CIOM_oBackbone1J1939_Rx_BC_405bc776_BswMR_dabe3454: start-on-event=GetEventStatus, operation=EvtInfo_AutoCreatedDemEvent_CC_DisableDM_CIOM_oBackbone1J1939_Rx_BC_405bc776_BswMReportFailToDemRef422.GetEventStatus
        OpEventGetEventStatus_GetEventStatus_EvtInfo_AutoCreatedDemEvent_CC_DisableDM_CIOM_oBackbone2_Rx_4e624434_BswMReportFai_fbc3118c: start-on-event=GetEventStatus, operation=EvtInfo_AutoCreatedDemEvent_CC_DisableDM_CIOM_oBackbone2_Rx_4e624434_BswMReportFailToDemRef422.GetEventStatus
        OpEventGetEventStatus_GetEventStatus_EvtInfo_AutoCreatedDemEvent_CC_DisableDM_CIOM_oCabSubnet_Rx_063a5fbc_BswMReportFai_86815a06: start-on-event=GetEventStatus, operation=EvtInfo_AutoCreatedDemEvent_CC_DisableDM_CIOM_oCabSubnet_Rx_063a5fbc_BswMReportFailToDemRef422.GetEventStatus
        OpEventGetEventStatus_GetEventStatus_EvtInfo_AutoCreatedDemEvent_CC_DisableDM_CIOM_oFMSNet_Rx_BC_dd2c1510_BswMReportFai_99919b80: start-on-event=GetEventStatus, operation=EvtInfo_AutoCreatedDemEvent_CC_DisableDM_CIOM_oFMSNet_Rx_BC_dd2c1510_BswMReportFailToDemRef422.GetEventStatus
        OpEventGetEventStatus_GetEventStatus_EvtInfo_AutoCreatedDemEvent_CC_DisableDM_CIOM_oSecuritySubnet_Rx_3a3c1dbc_BswMRepo_4cec0c05: start-on-event=GetEventStatus, operation=EvtInfo_AutoCreatedDemEvent_CC_DisableDM_CIOM_oSecuritySubnet_Rx_3a3c1dbc_BswMReportFailToDemRef422.GetEventStatus
        OpEventGetEventStatus_GetEventStatus_EvtInfo_AutoCreatedDemEvent_CC_DisablePDUGroup_CIOM_oBackbone1J1939_Rx_BC_405bc776_34c44423: start-on-event=GetEventStatus, operation=EvtInfo_AutoCreatedDemEvent_CC_DisablePDUGroup_CIOM_oBackbone1J1939_Rx_BC_405bc776_BswMReportFailToDemRef422.GetEventStatus
        OpEventGetEventStatus_GetEventStatus_EvtInfo_AutoCreatedDemEvent_CC_DisablePDUGroup_CIOM_oBackbone1J1939_Tx_0x31_BC_378_74304846: start-on-event=GetEventStatus, operation=EvtInfo_AutoCreatedDemEvent_CC_DisablePDUGroup_CIOM_oBackbone1J1939_Tx_0x31_BC_3782f500_BswMReportFailToDemRef422.GetEventStatus
        OpEventGetEventStatus_GetEventStatus_EvtInfo_AutoCreatedDemEvent_CC_DisablePDUGroup_CIOM_oBackbone2_Rx_4e624434_BswMRep_f9a8afd4: start-on-event=GetEventStatus, operation=EvtInfo_AutoCreatedDemEvent_CC_DisablePDUGroup_CIOM_oBackbone2_Rx_4e624434_BswMReportFailToDemRef422.GetEventStatus
        OpEventGetEventStatus_GetEventStatus_EvtInfo_AutoCreatedDemEvent_CC_DisablePDUGroup_CIOM_oBackbone2_Tx_1838e3b2_BswMRep_f57e09fa: start-on-event=GetEventStatus, operation=EvtInfo_AutoCreatedDemEvent_CC_DisablePDUGroup_CIOM_oBackbone2_Tx_1838e3b2_BswMReportFailToDemRef422.GetEventStatus
        OpEventGetEventStatus_GetEventStatus_EvtInfo_AutoCreatedDemEvent_CC_DisablePDUGroup_CIOM_oCabSubnet_Rx_063a5fbc_BswMRep_84eae45e: start-on-event=GetEventStatus, operation=EvtInfo_AutoCreatedDemEvent_CC_DisablePDUGroup_CIOM_oCabSubnet_Rx_063a5fbc_BswMReportFailToDemRef422.GetEventStatus
        OpEventGetEventStatus_GetEventStatus_EvtInfo_AutoCreatedDemEvent_CC_DisablePDUGroup_CIOM_oCabSubnet_Tx_5060f83a_BswMRep_1698bb6c: start-on-event=GetEventStatus, operation=EvtInfo_AutoCreatedDemEvent_CC_DisablePDUGroup_CIOM_oCabSubnet_Tx_5060f83a_BswMReportFailToDemRef422.GetEventStatus
        OpEventGetEventStatus_GetEventStatus_EvtInfo_AutoCreatedDemEvent_CC_DisablePDUGroup_CIOM_oFMSNet_Rx_BC_dd2c1510_BswMRep_9bfa25d8: start-on-event=GetEventStatus, operation=EvtInfo_AutoCreatedDemEvent_CC_DisablePDUGroup_CIOM_oFMSNet_Rx_BC_dd2c1510_BswMReportFailToDemRef422.GetEventStatus
        OpEventGetEventStatus_GetEventStatus_EvtInfo_AutoCreatedDemEvent_CC_DisablePDUGroup_CIOM_oFMSNet_Tx_0x31_BC_38fc8c7d_Bs_7f5ba649: start-on-event=GetEventStatus, operation=EvtInfo_AutoCreatedDemEvent_CC_DisablePDUGroup_CIOM_oFMSNet_Tx_0x31_BC_38fc8c7d_BswMReportFailToDemRef422.GetEventStatus
        OpEventGetEventStatus_GetEventStatus_EvtInfo_AutoCreatedDemEvent_CC_DisablePDUGroup_CIOM_oLIN00_Rx_dd181faa_BswMReportF_3a7c3142: start-on-event=GetEventStatus, operation=EvtInfo_AutoCreatedDemEvent_CC_DisablePDUGroup_CIOM_oLIN00_Rx_dd181faa_BswMReportFailToDemRef422.GetEventStatus
        OpEventGetEventStatus_GetEventStatus_EvtInfo_AutoCreatedDemEvent_CC_DisablePDUGroup_CIOM_oLIN00_Tx_8b42b82c_BswMReportF_469bff8b: start-on-event=GetEventStatus, operation=EvtInfo_AutoCreatedDemEvent_CC_DisablePDUGroup_CIOM_oLIN00_Tx_8b42b82c_BswMReportFailToDemRef422.GetEventStatus
        OpEventGetEventStatus_GetEventStatus_EvtInfo_AutoCreatedDemEvent_CC_DisablePDUGroup_CIOM_oLIN01_Rx_65a478cf_BswMReportF_03cc1647: start-on-event=GetEventStatus, operation=EvtInfo_AutoCreatedDemEvent_CC_DisablePDUGroup_CIOM_oLIN01_Rx_65a478cf_BswMReportFailToDemRef422.GetEventStatus
        OpEventGetEventStatus_GetEventStatus_EvtInfo_AutoCreatedDemEvent_CC_DisablePDUGroup_CIOM_oLIN01_Tx_33fedf49_BswMReportF_9d5fece0: start-on-event=GetEventStatus, operation=EvtInfo_AutoCreatedDemEvent_CC_DisablePDUGroup_CIOM_oLIN01_Tx_33fedf49_BswMReportFailToDemRef422.GetEventStatus
        OpEventGetEventStatus_GetEventStatus_EvtInfo_AutoCreatedDemEvent_CC_DisablePDUGroup_CIOM_oLIN02_Rx_7711d721_BswMReportF_edd5eab3: start-on-event=GetEventStatus, operation=EvtInfo_AutoCreatedDemEvent_CC_DisablePDUGroup_CIOM_oLIN02_Rx_7711d721_BswMReportFailToDemRef422.GetEventStatus
        OpEventGetEventStatus_GetEventStatus_EvtInfo_AutoCreatedDemEvent_CC_DisablePDUGroup_CIOM_oLIN02_Tx_214b70a7_BswMReportF_3de05a08: start-on-event=GetEventStatus, operation=EvtInfo_AutoCreatedDemEvent_CC_DisablePDUGroup_CIOM_oLIN02_Tx_214b70a7_BswMReportFailToDemRef422.GetEventStatus
        OpEventGetEventStatus_GetEventStatus_EvtInfo_AutoCreatedDemEvent_CC_DisablePDUGroup_CIOM_oLIN03_Rx_cfadb044_BswMReportF_71bb5d2b: start-on-event=GetEventStatus, operation=EvtInfo_AutoCreatedDemEvent_CC_DisablePDUGroup_CIOM_oLIN03_Rx_cfadb044_BswMReportFailToDemRef422.GetEventStatus
        OpEventGetEventStatus_GetEventStatus_EvtInfo_AutoCreatedDemEvent_CC_DisablePDUGroup_CIOM_oLIN03_Tx_99f717c2_BswMReportF_7e0c437f: start-on-event=GetEventStatus, operation=EvtInfo_AutoCreatedDemEvent_CC_DisablePDUGroup_CIOM_oLIN03_Tx_99f717c2_BswMReportFailToDemRef422.GetEventStatus
        OpEventGetEventStatus_GetEventStatus_EvtInfo_AutoCreatedDemEvent_CC_DisablePDUGroup_CIOM_oLIN04_Rx_527a88fd_BswMReportF_e308806f: start-on-event=GetEventStatus, operation=EvtInfo_AutoCreatedDemEvent_CC_DisablePDUGroup_CIOM_oLIN04_Rx_527a88fd_BswMReportFailToDemRef422.GetEventStatus
        OpEventGetEventStatus_GetEventStatus_EvtInfo_AutoCreatedDemEvent_CC_DisablePDUGroup_CIOM_oLIN04_Tx_04202f7b_BswMReportF_7c00835a: start-on-event=GetEventStatus, operation=EvtInfo_AutoCreatedDemEvent_CC_DisablePDUGroup_CIOM_oLIN04_Tx_04202f7b_BswMReportFailToDemRef422.GetEventStatus
        OpEventGetEventStatus_GetEventStatus_EvtInfo_AutoCreatedDemEvent_CC_DisablePDUGroup_CIOM_oSecuritySubnet_Rx_3a3c1dbc_Bs_cf96f7e5: start-on-event=GetEventStatus, operation=EvtInfo_AutoCreatedDemEvent_CC_DisablePDUGroup_CIOM_oSecuritySubnet_Rx_3a3c1dbc_BswMReportFailToDemRef422.GetEventStatus
        OpEventGetEventStatus_GetEventStatus_EvtInfo_AutoCreatedDemEvent_CC_DisablePDUGroup_CIOM_oSecuritySubnet_Tx_6c66ba3a_Bs_461c5543: start-on-event=GetEventStatus, operation=EvtInfo_AutoCreatedDemEvent_CC_DisablePDUGroup_CIOM_oSecuritySubnet_Tx_6c66ba3a_BswMReportFailToDemRef422.GetEventStatus
        OpEventGetEventStatus_GetEventStatus_EvtInfo_AutoCreatedDemEvent_CC_EnableDM_CIOM_oBackbone1J1939_Rx_BC_405bc776_BswMRe_f457c10b: start-on-event=GetEventStatus, operation=EvtInfo_AutoCreatedDemEvent_CC_EnableDM_CIOM_oBackbone1J1939_Rx_BC_405bc776_BswMReportFailToDemRef422.GetEventStatus
        OpEventGetEventStatus_GetEventStatus_EvtInfo_AutoCreatedDemEvent_CC_EnableDM_CIOM_oBackbone2_Rx_4e624434_BswMReportFail_a1cd21d1: start-on-event=GetEventStatus, operation=EvtInfo_AutoCreatedDemEvent_CC_EnableDM_CIOM_oBackbone2_Rx_4e624434_BswMReportFailToDemRef422.GetEventStatus
        OpEventGetEventStatus_GetEventStatus_EvtInfo_AutoCreatedDemEvent_CC_EnableDM_CIOM_oCabSubnet_Rx_063a5fbc_BswMReportFail_dc8f6a5b: start-on-event=GetEventStatus, operation=EvtInfo_AutoCreatedDemEvent_CC_EnableDM_CIOM_oCabSubnet_Rx_063a5fbc_BswMReportFailToDemRef422.GetEventStatus
        OpEventGetEventStatus_GetEventStatus_EvtInfo_AutoCreatedDemEvent_CC_EnableDM_CIOM_oFMSNet_Rx_BC_dd2c1510_BswMReportFail_c39fabdd: start-on-event=GetEventStatus, operation=EvtInfo_AutoCreatedDemEvent_CC_EnableDM_CIOM_oFMSNet_Rx_BC_dd2c1510_BswMReportFailToDemRef422.GetEventStatus
        OpEventGetEventStatus_GetEventStatus_EvtInfo_AutoCreatedDemEvent_CC_EnableDM_CIOM_oSecuritySubnet_Rx_3a3c1dbc_BswMRepor_368e670a: start-on-event=GetEventStatus, operation=EvtInfo_AutoCreatedDemEvent_CC_EnableDM_CIOM_oSecuritySubnet_Rx_3a3c1dbc_BswMReportFailToDemRef422.GetEventStatus
        OpEventGetEventStatus_GetEventStatus_EvtInfo_AutoCreatedDemEvent_CC_EnablePDUGroup_CIOM_oBackbone1J1939_Rx_BC_405bc776_d06c4474: start-on-event=GetEventStatus, operation=EvtInfo_AutoCreatedDemEvent_CC_EnablePDUGroup_CIOM_oBackbone1J1939_Rx_BC_405bc776_BswMReportFailToDemRef422.GetEventStatus
        OpEventGetEventStatus_GetEventStatus_EvtInfo_AutoCreatedDemEvent_CC_EnablePDUGroup_CIOM_oBackbone1J1939_Tx_0x31_BC_3782_137a61ad: start-on-event=GetEventStatus, operation=EvtInfo_AutoCreatedDemEvent_CC_EnablePDUGroup_CIOM_oBackbone1J1939_Tx_0x31_BC_3782f500_BswMReportFailToDemRef422.GetEventStatus
        OpEventGetEventStatus_GetEventStatus_EvtInfo_AutoCreatedDemEvent_CC_EnablePDUGroup_CIOM_oBackbone2_Rx_4e624434_BswMRepo_696dd02e: start-on-event=GetEventStatus, operation=EvtInfo_AutoCreatedDemEvent_CC_EnablePDUGroup_CIOM_oBackbone2_Rx_4e624434_BswMReportFailToDemRef422.GetEventStatus
        OpEventGetEventStatus_GetEventStatus_EvtInfo_AutoCreatedDemEvent_CC_EnablePDUGroup_CIOM_oBackbone2_Tx_1838e3b2_BswMRepo_65bb7600: start-on-event=GetEventStatus, operation=EvtInfo_AutoCreatedDemEvent_CC_EnablePDUGroup_CIOM_oBackbone2_Tx_1838e3b2_BswMReportFailToDemRef422.GetEventStatus
        OpEventGetEventStatus_GetEventStatus_EvtInfo_AutoCreatedDemEvent_CC_EnablePDUGroup_CIOM_oCabSubnet_Rx_063a5fbc_BswMRepo_142f9ba4: start-on-event=GetEventStatus, operation=EvtInfo_AutoCreatedDemEvent_CC_EnablePDUGroup_CIOM_oCabSubnet_Rx_063a5fbc_BswMReportFailToDemRef422.GetEventStatus
        OpEventGetEventStatus_GetEventStatus_EvtInfo_AutoCreatedDemEvent_CC_EnablePDUGroup_CIOM_oCabSubnet_Tx_5060f83a_BswMRepo_865dc496: start-on-event=GetEventStatus, operation=EvtInfo_AutoCreatedDemEvent_CC_EnablePDUGroup_CIOM_oCabSubnet_Tx_5060f83a_BswMReportFailToDemRef422.GetEventStatus
        OpEventGetEventStatus_GetEventStatus_EvtInfo_AutoCreatedDemEvent_CC_EnablePDUGroup_CIOM_oFMSNet_Rx_BC_dd2c1510_BswMRepo_0b3f5a22: start-on-event=GetEventStatus, operation=EvtInfo_AutoCreatedDemEvent_CC_EnablePDUGroup_CIOM_oFMSNet_Rx_BC_dd2c1510_BswMReportFailToDemRef422.GetEventStatus
        OpEventGetEventStatus_GetEventStatus_EvtInfo_AutoCreatedDemEvent_CC_EnablePDUGroup_CIOM_oFMSNet_Tx_0x31_BC_38fc8c7d_Bsw_a8a680ce: start-on-event=GetEventStatus, operation=EvtInfo_AutoCreatedDemEvent_CC_EnablePDUGroup_CIOM_oFMSNet_Tx_0x31_BC_38fc8c7d_BswMReportFailToDemRef422.GetEventStatus
        OpEventGetEventStatus_GetEventStatus_EvtInfo_AutoCreatedDemEvent_CC_EnablePDUGroup_CIOM_oLIN00_Rx_dd181faa_BswMReportFa_13b078f9: start-on-event=GetEventStatus, operation=EvtInfo_AutoCreatedDemEvent_CC_EnablePDUGroup_CIOM_oLIN00_Rx_dd181faa_BswMReportFailToDemRef422.GetEventStatus
        OpEventGetEventStatus_GetEventStatus_EvtInfo_AutoCreatedDemEvent_CC_EnablePDUGroup_CIOM_oLIN00_Tx_8b42b82c_BswMReportFa_6f57b630: start-on-event=GetEventStatus, operation=EvtInfo_AutoCreatedDemEvent_CC_EnablePDUGroup_CIOM_oLIN00_Tx_8b42b82c_BswMReportFailToDemRef422.GetEventStatus
        OpEventGetEventStatus_GetEventStatus_EvtInfo_AutoCreatedDemEvent_CC_EnablePDUGroup_CIOM_oLIN01_Rx_65a478cf_BswMReportFa_2a005ffc: start-on-event=GetEventStatus, operation=EvtInfo_AutoCreatedDemEvent_CC_EnablePDUGroup_CIOM_oLIN01_Rx_65a478cf_BswMReportFailToDemRef422.GetEventStatus
        OpEventGetEventStatus_GetEventStatus_EvtInfo_AutoCreatedDemEvent_CC_EnablePDUGroup_CIOM_oLIN01_Tx_33fedf49_BswMReportFa_b493a55b: start-on-event=GetEventStatus, operation=EvtInfo_AutoCreatedDemEvent_CC_EnablePDUGroup_CIOM_oLIN01_Tx_33fedf49_BswMReportFailToDemRef422.GetEventStatus
        OpEventGetEventStatus_GetEventStatus_EvtInfo_AutoCreatedDemEvent_CC_EnablePDUGroup_CIOM_oLIN02_Rx_7711d721_BswMReportFa_c419a308: start-on-event=GetEventStatus, operation=EvtInfo_AutoCreatedDemEvent_CC_EnablePDUGroup_CIOM_oLIN02_Rx_7711d721_BswMReportFailToDemRef422.GetEventStatus
        OpEventGetEventStatus_GetEventStatus_EvtInfo_AutoCreatedDemEvent_CC_EnablePDUGroup_CIOM_oLIN02_Tx_214b70a7_BswMReportFa_142c13b3: start-on-event=GetEventStatus, operation=EvtInfo_AutoCreatedDemEvent_CC_EnablePDUGroup_CIOM_oLIN02_Tx_214b70a7_BswMReportFailToDemRef422.GetEventStatus
        OpEventGetEventStatus_GetEventStatus_EvtInfo_AutoCreatedDemEvent_CC_EnablePDUGroup_CIOM_oLIN03_Rx_cfadb044_BswMReportFa_58771490: start-on-event=GetEventStatus, operation=EvtInfo_AutoCreatedDemEvent_CC_EnablePDUGroup_CIOM_oLIN03_Rx_cfadb044_BswMReportFailToDemRef422.GetEventStatus
        OpEventGetEventStatus_GetEventStatus_EvtInfo_AutoCreatedDemEvent_CC_EnablePDUGroup_CIOM_oLIN03_Tx_99f717c2_BswMReportFa_57c00ac4: start-on-event=GetEventStatus, operation=EvtInfo_AutoCreatedDemEvent_CC_EnablePDUGroup_CIOM_oLIN03_Tx_99f717c2_BswMReportFailToDemRef422.GetEventStatus
        OpEventGetEventStatus_GetEventStatus_EvtInfo_AutoCreatedDemEvent_CC_EnablePDUGroup_CIOM_oLIN04_Rx_527a88fd_BswMReportFa_cac4c9d4: start-on-event=GetEventStatus, operation=EvtInfo_AutoCreatedDemEvent_CC_EnablePDUGroup_CIOM_oLIN04_Rx_527a88fd_BswMReportFailToDemRef422.GetEventStatus
        OpEventGetEventStatus_GetEventStatus_EvtInfo_AutoCreatedDemEvent_CC_EnablePDUGroup_CIOM_oLIN04_Tx_04202f7b_BswMReportFa_55cccae1: start-on-event=GetEventStatus, operation=EvtInfo_AutoCreatedDemEvent_CC_EnablePDUGroup_CIOM_oLIN04_Tx_04202f7b_BswMReportFailToDemRef422.GetEventStatus
        OpEventGetEventStatus_GetEventStatus_EvtInfo_AutoCreatedDemEvent_CC_EnablePDUGroup_CIOM_oSecuritySubnet_Rx_3a3c1dbc_Bsw_186bd162: start-on-event=GetEventStatus, operation=EvtInfo_AutoCreatedDemEvent_CC_EnablePDUGroup_CIOM_oSecuritySubnet_Rx_3a3c1dbc_BswMReportFailToDemRef422.GetEventStatus
        OpEventGetEventStatus_GetEventStatus_EvtInfo_AutoCreatedDemEvent_CC_EnablePDUGroup_CIOM_oSecuritySubnet_Tx_6c66ba3a_Bsw_91e173c4: start-on-event=GetEventStatus, operation=EvtInfo_AutoCreatedDemEvent_CC_EnablePDUGroup_CIOM_oSecuritySubnet_Tx_6c66ba3a_BswMReportFailToDemRef422.GetEventStatus
        OpEventGetEventStatus_GetEventStatus_EvtInfo_AutoCreatedDemEvent_CC_J1939RmStateSwitch_CN_Backbone1J1939_0b1f4bae_CIOM_ac00fde3: start-on-event=GetEventStatus, operation=EvtInfo_AutoCreatedDemEvent_CC_J1939RmStateSwitch_CN_Backbone1J1939_0b1f4bae_CIOM_4d5cd289_J1939RM_STATE_OFFLINE_BswMRe_f9c55035.GetEventStatus
        OpEventGetEventStatus_GetEventStatus_EvtInfo_AutoCreatedDemEvent_CC_J1939RmStateSwitch_CN_Backbone1J1939_0b1f4bae_CIOM_ea5c78e9: start-on-event=GetEventStatus, operation=EvtInfo_AutoCreatedDemEvent_CC_J1939RmStateSwitch_CN_Backbone1J1939_0b1f4bae_CIOM_4d5cd289_J1939RM_STATE_ONLINE_BswMRep_5375d7eb.GetEventStatus
        OpEventGetEventStatus_GetEventStatus_EvtInfo_AutoCreatedDemEvent_CC_J1939RmStateSwitch_CN_FMSNet_fce1aae5_CIOM_3a3d59b1_f421dd0d: start-on-event=GetEventStatus, operation=EvtInfo_AutoCreatedDemEvent_CC_J1939RmStateSwitch_CN_FMSNet_fce1aae5_CIOM_3a3d59b1_J1939RM_STATE_OFFLINE_BswMReportFail_5f9bde08.GetEventStatus
        OpEventGetEventStatus_GetEventStatus_EvtInfo_AutoCreatedDemEvent_CC_J1939RmStateSwitch_CN_FMSNet_fce1aae5_CIOM_3a3d59b1_1a39d183: start-on-event=GetEventStatus, operation=EvtInfo_AutoCreatedDemEvent_CC_J1939RmStateSwitch_CN_FMSNet_fce1aae5_CIOM_3a3d59b1_J1939RM_STATE_ONLINE_BswMReportFailT_e97c0723.GetEventStatus
        OpEventGetEventStatus_GetEventStatus_EvtInfo_AutoCreatedDemEvent_CHNL_53cce282_CANSM_E_BUS_OFF422: start-on-event=GetEventStatus, operation=EvtInfo_AutoCreatedDemEvent_CHNL_53cce282_CANSM_E_BUS_OFF422.GetEventStatus
        OpEventGetEventStatus_GetEventStatus_EvtInfo_AutoCreatedDemEvent_CHNL_53cce282_CANSM_E_MODE_REQUEST_TIMEOUT422: start-on-event=GetEventStatus, operation=EvtInfo_AutoCreatedDemEvent_CHNL_53cce282_CANSM_E_MODE_REQUEST_TIMEOUT422.GetEventStatus
        OpEventGetEventStatus_GetEventStatus_EvtInfo_AutoCreatedDemEvent_CHNL_17344684_CANSM_E_BUS_OFF422: start-on-event=GetEventStatus, operation=EvtInfo_AutoCreatedDemEvent_CHNL_17344684_CANSM_E_BUS_OFF422.GetEventStatus
        OpEventGetEventStatus_GetEventStatus_EvtInfo_AutoCreatedDemEvent_CHNL_17344684_CANSM_E_MODE_REQUEST_TIMEOUT422: start-on-event=GetEventStatus, operation=EvtInfo_AutoCreatedDemEvent_CHNL_17344684_CANSM_E_MODE_REQUEST_TIMEOUT422.GetEventStatus
        OpEventGetEventStatus_GetEventStatus_EvtInfo_AutoCreatedDemEvent_CHNL_a6b6a922_CANSM_E_BUS_OFF422: start-on-event=GetEventStatus, operation=EvtInfo_AutoCreatedDemEvent_CHNL_a6b6a922_CANSM_E_BUS_OFF422.GetEventStatus
        OpEventGetEventStatus_GetEventStatus_EvtInfo_AutoCreatedDemEvent_CHNL_a6b6a922_CANSM_E_MODE_REQUEST_TIMEOUT422: start-on-event=GetEventStatus, operation=EvtInfo_AutoCreatedDemEvent_CHNL_a6b6a922_CANSM_E_MODE_REQUEST_TIMEOUT422.GetEventStatus
        OpEventGetEventStatus_GetEventStatus_EvtInfo_AutoCreatedDemEvent_CHNL_df893ad5_CANSM_E_BUS_OFF422: start-on-event=GetEventStatus, operation=EvtInfo_AutoCreatedDemEvent_CHNL_df893ad5_CANSM_E_BUS_OFF422.GetEventStatus
        OpEventGetEventStatus_GetEventStatus_EvtInfo_AutoCreatedDemEvent_CHNL_df893ad5_CANSM_E_MODE_REQUEST_TIMEOUT422: start-on-event=GetEventStatus, operation=EvtInfo_AutoCreatedDemEvent_CHNL_df893ad5_CANSM_E_MODE_REQUEST_TIMEOUT422.GetEventStatus
        OpEventGetEventStatus_GetEventStatus_EvtInfo_AutoCreatedDemEvent_CHNL_e058b4ae_CANSM_E_BUS_OFF422: start-on-event=GetEventStatus, operation=EvtInfo_AutoCreatedDemEvent_CHNL_e058b4ae_CANSM_E_BUS_OFF422.GetEventStatus
        OpEventGetEventStatus_GetEventStatus_EvtInfo_AutoCreatedDemEvent_CHNL_e058b4ae_CANSM_E_MODE_REQUEST_TIMEOUT422: start-on-event=GetEventStatus, operation=EvtInfo_AutoCreatedDemEvent_CHNL_e058b4ae_CANSM_E_MODE_REQUEST_TIMEOUT422.GetEventStatus
        OpEventGetEventStatus_GetEventStatus_EvtInfo_AutoCreatedDemEvent_ECUM_E_ALL_RUN_REQUESTS_KILLED422: start-on-event=GetEventStatus, operation=EvtInfo_AutoCreatedDemEvent_ECUM_E_ALL_RUN_REQUESTS_KILLED422.GetEventStatus
        OpEventGetEventStatus_GetEventStatus_EvtInfo_AutoCreatedDemEvent_ECUM_E_CONFIGURATION_DATA_INCONSISTENT422: start-on-event=GetEventStatus, operation=EvtInfo_AutoCreatedDemEvent_ECUM_E_CONFIGURATION_DATA_INCONSISTENT422.GetEventStatus
        OpEventGetEventStatus_GetEventStatus_EvtInfo_AutoCreatedDemEvent_ECUM_E_IMPROPER_CALLER422: start-on-event=GetEventStatus, operation=EvtInfo_AutoCreatedDemEvent_ECUM_E_IMPROPER_CALLER422.GetEventStatus
        OpEventGetEventStatus_GetEventStatus_EvtInfo_AutoCreatedDemEvent_ECUM_E_RAM_CHECK_FAILED422: start-on-event=GetEventStatus, operation=EvtInfo_AutoCreatedDemEvent_ECUM_E_RAM_CHECK_FAILED422.GetEventStatus
        OpEventGetEventStatus_GetEventStatus_EvtInfo_AutoCreatedDemEvent_ESH_Action_CancelNvMWriteAll_BswMReportFailToDemRef422: start-on-event=GetEventStatus, operation=EvtInfo_AutoCreatedDemEvent_ESH_Action_CancelNvMWriteAll_BswMReportFailToDemRef422.GetEventStatus
        OpEventGetEventStatus_GetEventStatus_EvtInfo_AutoCreatedDemEvent_ESH_Action_CancelWriteAllTimer_Start_BswMReportFailToDemRef422: start-on-event=GetEventStatus, operation=EvtInfo_AutoCreatedDemEvent_ESH_Action_CancelWriteAllTimer_Start_BswMReportFailToDemRef422.GetEventStatus
        OpEventGetEventStatus_GetEventStatus_EvtInfo_AutoCreatedDemEvent_ESH_Action_CancelWriteAllTimer_Stop_BswMReportFailToDemRef422: start-on-event=GetEventStatus, operation=EvtInfo_AutoCreatedDemEvent_ESH_Action_CancelWriteAllTimer_Stop_BswMReportFailToDemRef422.GetEventStatus
        OpEventGetEventStatus_GetEventStatus_EvtInfo_AutoCreatedDemEvent_ESH_Action_ComMAllow_CN_Backbone1J1939_0b1f4bae_BswMRe_04ecdabc: start-on-event=GetEventStatus, operation=EvtInfo_AutoCreatedDemEvent_ESH_Action_ComMAllow_CN_Backbone1J1939_0b1f4bae_BswMReportFailToDemRef422.GetEventStatus
        OpEventGetEventStatus_GetEventStatus_EvtInfo_AutoCreatedDemEvent_ESH_Action_ComMAllow_CN_Backbone1J1939_0b1f4bae_BswMRe_b2d25c9c: start-on-event=GetEventStatus, operation=EvtInfo_AutoCreatedDemEvent_ESH_Action_ComMAllow_CN_Backbone1J1939_0b1f4bae_BswMReportFailToDemRef_1422.GetEventStatus
        OpEventGetEventStatus_GetEventStatus_EvtInfo_AutoCreatedDemEvent_ESH_Action_ComMAllow_CN_Backbone2_78967e2c_BswMReportF_236b97e6: start-on-event=GetEventStatus, operation=EvtInfo_AutoCreatedDemEvent_ESH_Action_ComMAllow_CN_Backbone2_78967e2c_BswMReportFailToDemRef422.GetEventStatus
        OpEventGetEventStatus_GetEventStatus_EvtInfo_AutoCreatedDemEvent_ESH_Action_ComMAllow_CN_Backbone2_78967e2c_BswMReportF_faebf3e8: start-on-event=GetEventStatus, operation=EvtInfo_AutoCreatedDemEvent_ESH_Action_ComMAllow_CN_Backbone2_78967e2c_BswMReportFailToDemRef_1422.GetEventStatus
        OpEventGetEventStatus_GetEventStatus_EvtInfo_AutoCreatedDemEvent_ESH_Action_ComMAllow_CN_CabSubnet_9ea693f1_BswMReportF_8f61b130: start-on-event=GetEventStatus, operation=EvtInfo_AutoCreatedDemEvent_ESH_Action_ComMAllow_CN_CabSubnet_9ea693f1_BswMReportFailToDemRef422.GetEventStatus
        OpEventGetEventStatus_GetEventStatus_EvtInfo_AutoCreatedDemEvent_ESH_Action_ComMAllow_CN_CabSubnet_9ea693f1_BswMReportF_ff84b886: start-on-event=GetEventStatus, operation=EvtInfo_AutoCreatedDemEvent_ESH_Action_ComMAllow_CN_CabSubnet_9ea693f1_BswMReportFailToDemRef_1422.GetEventStatus
        OpEventGetEventStatus_GetEventStatus_EvtInfo_AutoCreatedDemEvent_ESH_Action_ComMAllow_CN_FMSNet_fce1aae5_BswMReportFail_991e3c63: start-on-event=GetEventStatus, operation=EvtInfo_AutoCreatedDemEvent_ESH_Action_ComMAllow_CN_FMSNet_fce1aae5_BswMReportFailToDemRef422.GetEventStatus
        OpEventGetEventStatus_GetEventStatus_EvtInfo_AutoCreatedDemEvent_ESH_Action_ComMAllow_CN_FMSNet_fce1aae5_BswMReportFail_fd1b5ff3: start-on-event=GetEventStatus, operation=EvtInfo_AutoCreatedDemEvent_ESH_Action_ComMAllow_CN_FMSNet_fce1aae5_BswMReportFailToDemRef_1422.GetEventStatus
        OpEventGetEventStatus_GetEventStatus_EvtInfo_AutoCreatedDemEvent_ESH_Action_ComMAllow_CN_LIN00_2cd9a7df_BswMReportFailT_d0611023: start-on-event=GetEventStatus, operation=EvtInfo_AutoCreatedDemEvent_ESH_Action_ComMAllow_CN_LIN00_2cd9a7df_BswMReportFailToDemRef422.GetEventStatus
        OpEventGetEventStatus_GetEventStatus_EvtInfo_AutoCreatedDemEvent_ESH_Action_ComMAllow_CN_LIN00_2cd9a7df_BswMReportFailT_3fba356a: start-on-event=GetEventStatus, operation=EvtInfo_AutoCreatedDemEvent_ESH_Action_ComMAllow_CN_LIN00_2cd9a7df_BswMReportFailToDemRef_1422.GetEventStatus
        OpEventGetEventStatus_GetEventStatus_EvtInfo_AutoCreatedDemEvent_ESH_Action_ComMAllow_CN_LIN01_5bde9749_BswMReportFailT_eb51614f: start-on-event=GetEventStatus, operation=EvtInfo_AutoCreatedDemEvent_ESH_Action_ComMAllow_CN_LIN01_5bde9749_BswMReportFailToDemRef422.GetEventStatus
        OpEventGetEventStatus_GetEventStatus_EvtInfo_AutoCreatedDemEvent_ESH_Action_ComMAllow_CN_LIN01_5bde9749_BswMReportFailT_d1f06b5b: start-on-event=GetEventStatus, operation=EvtInfo_AutoCreatedDemEvent_ESH_Action_ComMAllow_CN_LIN01_5bde9749_BswMReportFailToDemRef_1422.GetEventStatus
        OpEventGetEventStatus_GetEventStatus_EvtInfo_AutoCreatedDemEvent_ESH_Action_ComMAllow_CN_LIN02_c2d7c6f3_BswMReportFailT_3232a17e: start-on-event=GetEventStatus, operation=EvtInfo_AutoCreatedDemEvent_ESH_Action_ComMAllow_CN_LIN02_c2d7c6f3_BswMReportFailToDemRef422.GetEventStatus
        OpEventGetEventStatus_GetEventStatus_EvtInfo_AutoCreatedDemEvent_ESH_Action_ComMAllow_CN_LIN02_c2d7c6f3_BswMReportFailT_8cc9773a: start-on-event=GetEventStatus, operation=EvtInfo_AutoCreatedDemEvent_ESH_Action_ComMAllow_CN_LIN02_c2d7c6f3_BswMReportFailToDemRef_1422.GetEventStatus
        OpEventGetEventStatus_GetEventStatus_EvtInfo_AutoCreatedDemEvent_ESH_Action_ComMAllow_CN_LIN03_b5d0f665_BswMReportFailT_2c30e84c: start-on-event=GetEventStatus, operation=EvtInfo_AutoCreatedDemEvent_ESH_Action_ComMAllow_CN_LIN03_b5d0f665_BswMReportFailToDemRef422.GetEventStatus
        OpEventGetEventStatus_GetEventStatus_EvtInfo_AutoCreatedDemEvent_ESH_Action_ComMAllow_CN_LIN03_b5d0f665_BswMReportFailT_6eb9c47d: start-on-event=GetEventStatus, operation=EvtInfo_AutoCreatedDemEvent_ESH_Action_ComMAllow_CN_LIN03_b5d0f665_BswMReportFailToDemRef_1422.GetEventStatus
        OpEventGetEventStatus_GetEventStatus_EvtInfo_AutoCreatedDemEvent_ESH_Action_ComMAllow_CN_LIN04_2bb463c6_BswMReportFailT_a77430d4: start-on-event=GetEventStatus, operation=EvtInfo_AutoCreatedDemEvent_ESH_Action_ComMAllow_CN_LIN04_2bb463c6_BswMReportFailToDemRef422.GetEventStatus
        OpEventGetEventStatus_GetEventStatus_EvtInfo_AutoCreatedDemEvent_ESH_Action_ComMAllow_CN_LIN04_2bb463c6_BswMReportFailT_5f2915cd: start-on-event=GetEventStatus, operation=EvtInfo_AutoCreatedDemEvent_ESH_Action_ComMAllow_CN_LIN04_2bb463c6_BswMReportFailToDemRef_1422.GetEventStatus
        OpEventGetEventStatus_GetEventStatus_EvtInfo_AutoCreatedDemEvent_ESH_Action_ComMAllow_CN_SecuritySubnet_e7a0ee54_BswMRe_be3bf3d4: start-on-event=GetEventStatus, operation=EvtInfo_AutoCreatedDemEvent_ESH_Action_ComMAllow_CN_SecuritySubnet_e7a0ee54_BswMReportFailToDemRef422.GetEventStatus
        OpEventGetEventStatus_GetEventStatus_EvtInfo_AutoCreatedDemEvent_ESH_Action_ComMAllow_CN_SecuritySubnet_e7a0ee54_BswMRe_5d449f88: start-on-event=GetEventStatus, operation=EvtInfo_AutoCreatedDemEvent_ESH_Action_ComMAllow_CN_SecuritySubnet_e7a0ee54_BswMReportFailToDemRef_1422.GetEventStatus
        OpEventGetEventStatus_GetEventStatus_EvtInfo_AutoCreatedDemEvent_ESH_Action_ComMCheckPendingRequests_BswMReportFailToDemRef422: start-on-event=GetEventStatus, operation=EvtInfo_AutoCreatedDemEvent_ESH_Action_ComMCheckPendingRequests_BswMReportFailToDemRef422.GetEventStatus
        OpEventGetEventStatus_GetEventStatus_EvtInfo_AutoCreatedDemEvent_ESH_Action_ComMCheckPendingRequests_BswMReportFailToDemRef_1422: start-on-event=GetEventStatus, operation=EvtInfo_AutoCreatedDemEvent_ESH_Action_ComMCheckPendingRequests_BswMReportFailToDemRef_1422.GetEventStatus
        OpEventGetEventStatus_GetEventStatus_EvtInfo_AutoCreatedDemEvent_ESH_Action_ComMCheckPendingRequests_BswMReportFailToDemRef_2422: start-on-event=GetEventStatus, operation=EvtInfo_AutoCreatedDemEvent_ESH_Action_ComMCheckPendingRequests_BswMReportFailToDemRef_2422.GetEventStatus
        OpEventGetEventStatus_GetEventStatus_EvtInfo_AutoCreatedDemEvent_ESH_Action_ComMDisallow_CN_Backbone1J1939_0b1f4bae_Bsw_53362860: start-on-event=GetEventStatus, operation=EvtInfo_AutoCreatedDemEvent_ESH_Action_ComMDisallow_CN_Backbone1J1939_0b1f4bae_BswMReportFailToDemRef422.GetEventStatus
        OpEventGetEventStatus_GetEventStatus_EvtInfo_AutoCreatedDemEvent_ESH_Action_ComMDisallow_CN_Backbone2_78967e2c_BswMRepo_b6ed8164: start-on-event=GetEventStatus, operation=EvtInfo_AutoCreatedDemEvent_ESH_Action_ComMDisallow_CN_Backbone2_78967e2c_BswMReportFailToDemRef422.GetEventStatus
        OpEventGetEventStatus_GetEventStatus_EvtInfo_AutoCreatedDemEvent_ESH_Action_ComMDisallow_CN_CabSubnet_9ea693f1_BswMRepo_1ae7a7b2: start-on-event=GetEventStatus, operation=EvtInfo_AutoCreatedDemEvent_ESH_Action_ComMDisallow_CN_CabSubnet_9ea693f1_BswMReportFailToDemRef422.GetEventStatus
        OpEventGetEventStatus_GetEventStatus_EvtInfo_AutoCreatedDemEvent_ESH_Action_ComMDisallow_CN_FMSNet_fce1aae5_BswMReportF_2f9cd75a: start-on-event=GetEventStatus, operation=EvtInfo_AutoCreatedDemEvent_ESH_Action_ComMDisallow_CN_FMSNet_fce1aae5_BswMReportFailToDemRef422.GetEventStatus
        OpEventGetEventStatus_GetEventStatus_EvtInfo_AutoCreatedDemEvent_ESH_Action_ComMDisallow_CN_LIN00_2cd9a7df_BswMReportFa_34a7141c: start-on-event=GetEventStatus, operation=EvtInfo_AutoCreatedDemEvent_ESH_Action_ComMDisallow_CN_LIN00_2cd9a7df_BswMReportFailToDemRef422.GetEventStatus
        OpEventGetEventStatus_GetEventStatus_EvtInfo_AutoCreatedDemEvent_ESH_Action_ComMDisallow_CN_LIN01_5bde9749_BswMReportFa_0f976570: start-on-event=GetEventStatus, operation=EvtInfo_AutoCreatedDemEvent_ESH_Action_ComMDisallow_CN_LIN01_5bde9749_BswMReportFailToDemRef422.GetEventStatus
        OpEventGetEventStatus_GetEventStatus_EvtInfo_AutoCreatedDemEvent_ESH_Action_ComMDisallow_CN_LIN02_c2d7c6f3_BswMReportFa_d6f4a541: start-on-event=GetEventStatus, operation=EvtInfo_AutoCreatedDemEvent_ESH_Action_ComMDisallow_CN_LIN02_c2d7c6f3_BswMReportFailToDemRef422.GetEventStatus
        OpEventGetEventStatus_GetEventStatus_EvtInfo_AutoCreatedDemEvent_ESH_Action_ComMDisallow_CN_LIN03_b5d0f665_BswMReportFa_c8f6ec73: start-on-event=GetEventStatus, operation=EvtInfo_AutoCreatedDemEvent_ESH_Action_ComMDisallow_CN_LIN03_b5d0f665_BswMReportFailToDemRef422.GetEventStatus
        OpEventGetEventStatus_GetEventStatus_EvtInfo_AutoCreatedDemEvent_ESH_Action_ComMDisallow_CN_LIN04_2bb463c6_BswMReportFa_43b234eb: start-on-event=GetEventStatus, operation=EvtInfo_AutoCreatedDemEvent_ESH_Action_ComMDisallow_CN_LIN04_2bb463c6_BswMReportFailToDemRef422.GetEventStatus
        OpEventGetEventStatus_GetEventStatus_EvtInfo_AutoCreatedDemEvent_ESH_Action_ComMDisallow_CN_SecuritySubnet_e7a0ee54_Bsw_e9e10108: start-on-event=GetEventStatus, operation=EvtInfo_AutoCreatedDemEvent_ESH_Action_ComMDisallow_CN_SecuritySubnet_e7a0ee54_BswMReportFailToDemRef422.GetEventStatus
        OpEventGetEventStatus_GetEventStatus_EvtInfo_AutoCreatedDemEvent_ESH_Action_DemInit_BswMReportFailToDemRef422: start-on-event=GetEventStatus, operation=EvtInfo_AutoCreatedDemEvent_ESH_Action_DemInit_BswMReportFailToDemRef422.GetEventStatus
        OpEventGetEventStatus_GetEventStatus_EvtInfo_AutoCreatedDemEvent_ESH_Action_DemInitialized_BswMReportFailToDemRef422: start-on-event=GetEventStatus, operation=EvtInfo_AutoCreatedDemEvent_ESH_Action_DemInitialized_BswMReportFailToDemRef422.GetEventStatus
        OpEventGetEventStatus_GetEventStatus_EvtInfo_AutoCreatedDemEvent_ESH_Action_DemNotInitialized_BswMReportFailToDemRef422: start-on-event=GetEventStatus, operation=EvtInfo_AutoCreatedDemEvent_ESH_Action_DemNotInitialized_BswMReportFailToDemRef422.GetEventStatus
        OpEventGetEventStatus_GetEventStatus_EvtInfo_AutoCreatedDemEvent_ESH_Action_DemShutdown_BswMReportFailToDemRef422: start-on-event=GetEventStatus, operation=EvtInfo_AutoCreatedDemEvent_ESH_Action_DemShutdown_BswMReportFailToDemRef422.GetEventStatus
        OpEventGetEventStatus_GetEventStatus_EvtInfo_AutoCreatedDemEvent_ESH_Action_ESH_PostRun_BswMReportFailToDemRef422: start-on-event=GetEventStatus, operation=EvtInfo_AutoCreatedDemEvent_ESH_Action_ESH_PostRun_BswMReportFailToDemRef422.GetEventStatus
        OpEventGetEventStatus_GetEventStatus_EvtInfo_AutoCreatedDemEvent_ESH_Action_ESH_PrepShutdown_BswMReportFailToDemRef422: start-on-event=GetEventStatus, operation=EvtInfo_AutoCreatedDemEvent_ESH_Action_ESH_PrepShutdown_BswMReportFailToDemRef422.GetEventStatus
        OpEventGetEventStatus_GetEventStatus_EvtInfo_AutoCreatedDemEvent_ESH_Action_ESH_PrepShutdown_BswMReportFailToDemRef_1422: start-on-event=GetEventStatus, operation=EvtInfo_AutoCreatedDemEvent_ESH_Action_ESH_PrepShutdown_BswMReportFailToDemRef_1422.GetEventStatus
        OpEventGetEventStatus_GetEventStatus_EvtInfo_AutoCreatedDemEvent_ESH_Action_ESH_Run_BswMReportFailToDemRef422: start-on-event=GetEventStatus, operation=EvtInfo_AutoCreatedDemEvent_ESH_Action_ESH_Run_BswMReportFailToDemRef422.GetEventStatus
        OpEventGetEventStatus_GetEventStatus_EvtInfo_AutoCreatedDemEvent_ESH_Action_ESH_Run_BswMReportFailToDemRef_1422: start-on-event=GetEventStatus, operation=EvtInfo_AutoCreatedDemEvent_ESH_Action_ESH_Run_BswMReportFailToDemRef_1422.GetEventStatus
        OpEventGetEventStatus_GetEventStatus_EvtInfo_AutoCreatedDemEvent_ESH_Action_ESH_WaitForNvm_BswMReportFailToDemRef422: start-on-event=GetEventStatus, operation=EvtInfo_AutoCreatedDemEvent_ESH_Action_ESH_WaitForNvm_BswMReportFailToDemRef422.GetEventStatus
        OpEventGetEventStatus_GetEventStatus_EvtInfo_AutoCreatedDemEvent_ESH_Action_ESH_Wakeup_BswMReportFailToDemRef422: start-on-event=GetEventStatus, operation=EvtInfo_AutoCreatedDemEvent_ESH_Action_ESH_Wakeup_BswMReportFailToDemRef422.GetEventStatus
        OpEventGetEventStatus_GetEventStatus_EvtInfo_AutoCreatedDemEvent_ESH_Action_ESH_Wakeup_BswMReportFailToDemRef_1422: start-on-event=GetEventStatus, operation=EvtInfo_AutoCreatedDemEvent_ESH_Action_ESH_Wakeup_BswMReportFailToDemRef_1422.GetEventStatus
        OpEventGetEventStatus_GetEventStatus_EvtInfo_AutoCreatedDemEvent_ESH_Action_EcuMClearValidatedWakeupEvents_BswMReportFa_383d56d6: start-on-event=GetEventStatus, operation=EvtInfo_AutoCreatedDemEvent_ESH_Action_EcuMClearValidatedWakeupEvents_BswMReportFailToDemRef422.GetEventStatus
        OpEventGetEventStatus_GetEventStatus_EvtInfo_AutoCreatedDemEvent_ESH_Action_EcuMGoToSelectedShutdownTarget_BswMReportFa_c3f519c3: start-on-event=GetEventStatus, operation=EvtInfo_AutoCreatedDemEvent_ESH_Action_EcuMGoToSelectedShutdownTarget_BswMReportFailToDemRef422.GetEventStatus
        OpEventGetEventStatus_GetEventStatus_EvtInfo_AutoCreatedDemEvent_ESH_Action_EnterExclusiveArea_BswMReportFailToDemRef422: start-on-event=GetEventStatus, operation=EvtInfo_AutoCreatedDemEvent_ESH_Action_EnterExclusiveArea_BswMReportFailToDemRef422.GetEventStatus
        OpEventGetEventStatus_GetEventStatus_EvtInfo_AutoCreatedDemEvent_ESH_Action_EnterExclusiveArea_BswMReportFailToDemRef_1422: start-on-event=GetEventStatus, operation=EvtInfo_AutoCreatedDemEvent_ESH_Action_EnterExclusiveArea_BswMReportFailToDemRef_1422.GetEventStatus
        OpEventGetEventStatus_GetEventStatus_EvtInfo_AutoCreatedDemEvent_ESH_Action_ExitExclusiveArea_BswMReportFailToDemRef422: start-on-event=GetEventStatus, operation=EvtInfo_AutoCreatedDemEvent_ESH_Action_ExitExclusiveArea_BswMReportFailToDemRef422.GetEventStatus
        OpEventGetEventStatus_GetEventStatus_EvtInfo_AutoCreatedDemEvent_ESH_Action_ExitExclusiveArea_BswMReportFailToDemRef_1422: start-on-event=GetEventStatus, operation=EvtInfo_AutoCreatedDemEvent_ESH_Action_ExitExclusiveArea_BswMReportFailToDemRef_1422.GetEventStatus
        OpEventGetEventStatus_GetEventStatus_EvtInfo_AutoCreatedDemEvent_ESH_Action_NvMWriteAll_BswMReportFailToDemRef422: start-on-event=GetEventStatus, operation=EvtInfo_AutoCreatedDemEvent_ESH_Action_NvMWriteAll_BswMReportFailToDemRef422.GetEventStatus
        OpEventGetEventStatus_GetEventStatus_EvtInfo_AutoCreatedDemEvent_ESH_Action_OnEnterPostRun_BswMReportFailToDemRef422: start-on-event=GetEventStatus, operation=EvtInfo_AutoCreatedDemEvent_ESH_Action_OnEnterPostRun_BswMReportFailToDemRef422.GetEventStatus
        OpEventGetEventStatus_GetEventStatus_EvtInfo_AutoCreatedDemEvent_ESH_Action_OnEnterPrepShutdown_BswMReportFailToDemRef422: start-on-event=GetEventStatus, operation=EvtInfo_AutoCreatedDemEvent_ESH_Action_OnEnterPrepShutdown_BswMReportFailToDemRef422.GetEventStatus
        OpEventGetEventStatus_GetEventStatus_EvtInfo_AutoCreatedDemEvent_ESH_Action_OnEnterPrepShutdown_BswMReportFailToDemRef_1422: start-on-event=GetEventStatus, operation=EvtInfo_AutoCreatedDemEvent_ESH_Action_OnEnterPrepShutdown_BswMReportFailToDemRef_1422.GetEventStatus
        OpEventGetEventStatus_GetEventStatus_EvtInfo_AutoCreatedDemEvent_ESH_Action_OnEnterRun_BswMReportFailToDemRef422: start-on-event=GetEventStatus, operation=EvtInfo_AutoCreatedDemEvent_ESH_Action_OnEnterRun_BswMReportFailToDemRef422.GetEventStatus
        OpEventGetEventStatus_GetEventStatus_EvtInfo_AutoCreatedDemEvent_ESH_Action_OnEnterRun_BswMReportFailToDemRef_1422: start-on-event=GetEventStatus, operation=EvtInfo_AutoCreatedDemEvent_ESH_Action_OnEnterRun_BswMReportFailToDemRef_1422.GetEventStatus
        OpEventGetEventStatus_GetEventStatus_EvtInfo_AutoCreatedDemEvent_ESH_Action_OnEnterShutdown_BswMReportFailToDemRef422: start-on-event=GetEventStatus, operation=EvtInfo_AutoCreatedDemEvent_ESH_Action_OnEnterShutdown_BswMReportFailToDemRef422.GetEventStatus
        OpEventGetEventStatus_GetEventStatus_EvtInfo_AutoCreatedDemEvent_ESH_Action_OnEnterWaitForNvm_BswMReportFailToDemRef422: start-on-event=GetEventStatus, operation=EvtInfo_AutoCreatedDemEvent_ESH_Action_OnEnterWaitForNvm_BswMReportFailToDemRef422.GetEventStatus
        OpEventGetEventStatus_GetEventStatus_EvtInfo_AutoCreatedDemEvent_ESH_Action_OnEnterWakeup_BswMReportFailToDemRef422: start-on-event=GetEventStatus, operation=EvtInfo_AutoCreatedDemEvent_ESH_Action_OnEnterWakeup_BswMReportFailToDemRef422.GetEventStatus
        OpEventGetEventStatus_GetEventStatus_EvtInfo_AutoCreatedDemEvent_ESH_Action_OnEnterWakeup_BswMReportFailToDemRef_1422: start-on-event=GetEventStatus, operation=EvtInfo_AutoCreatedDemEvent_ESH_Action_OnEnterWakeup_BswMReportFailToDemRef_1422.GetEventStatus
        OpEventGetEventStatus_GetEventStatus_EvtInfo_AutoCreatedDemEvent_ESH_Action_SelfRunRequestTimer_Start_BswMReportFailToDemRef422: start-on-event=GetEventStatus, operation=EvtInfo_AutoCreatedDemEvent_ESH_Action_SelfRunRequestTimer_Start_BswMReportFailToDemRef422.GetEventStatus
        OpEventGetEventStatus_GetEventStatus_EvtInfo_AutoCreatedDemEvent_ESH_Action_SelfRunRequestTimer_Start_BswMReportFailToD_744cad9b: start-on-event=GetEventStatus, operation=EvtInfo_AutoCreatedDemEvent_ESH_Action_SelfRunRequestTimer_Start_BswMReportFailToDemRef_1422.GetEventStatus
        OpEventGetEventStatus_GetEventStatus_EvtInfo_AutoCreatedDemEvent_ESH_Action_SwitchPostRun_BswMReportFailToDemRef422: start-on-event=GetEventStatus, operation=EvtInfo_AutoCreatedDemEvent_ESH_Action_SwitchPostRun_BswMReportFailToDemRef422.GetEventStatus
        OpEventGetEventStatus_GetEventStatus_EvtInfo_AutoCreatedDemEvent_ESH_Action_SwitchRun_BswMReportFailToDemRef422: start-on-event=GetEventStatus, operation=EvtInfo_AutoCreatedDemEvent_ESH_Action_SwitchRun_BswMReportFailToDemRef422.GetEventStatus
        OpEventGetEventStatus_GetEventStatus_EvtInfo_AutoCreatedDemEvent_ESH_Action_SwitchRun_BswMReportFailToDemRef_1422: start-on-event=GetEventStatus, operation=EvtInfo_AutoCreatedDemEvent_ESH_Action_SwitchRun_BswMReportFailToDemRef_1422.GetEventStatus
        OpEventGetEventStatus_GetEventStatus_EvtInfo_AutoCreatedDemEvent_ESH_Action_SwitchShutdown_BswMReportFailToDemRef422: start-on-event=GetEventStatus, operation=EvtInfo_AutoCreatedDemEvent_ESH_Action_SwitchShutdown_BswMReportFailToDemRef422.GetEventStatus
        OpEventGetEventStatus_GetEventStatus_EvtInfo_AutoCreatedDemEvent_ESH_Action_SwitchShutdown_BswMReportFailToDemRef_1422: start-on-event=GetEventStatus, operation=EvtInfo_AutoCreatedDemEvent_ESH_Action_SwitchShutdown_BswMReportFailToDemRef_1422.GetEventStatus
        OpEventGetEventStatus_GetEventStatus_EvtInfo_AutoCreatedDemEvent_ESH_Action_SwitchWakeup_BswMReportFailToDemRef422: start-on-event=GetEventStatus, operation=EvtInfo_AutoCreatedDemEvent_ESH_Action_SwitchWakeup_BswMReportFailToDemRef422.GetEventStatus
        OpEventGetEventStatus_GetEventStatus_EvtInfo_AutoCreatedDemEvent_ESH_Action_SwitchWakeup_BswMReportFailToDemRef_1422: start-on-event=GetEventStatus, operation=EvtInfo_AutoCreatedDemEvent_ESH_Action_SwitchWakeup_BswMReportFailToDemRef_1422.GetEventStatus
        OpEventGetEventStatus_GetEventStatus_EvtInfo_AutoCreatedDemEvent_ESH_Action_WriteAllTimer_Start_BswMReportFailToDemRef422: start-on-event=GetEventStatus, operation=EvtInfo_AutoCreatedDemEvent_ESH_Action_WriteAllTimer_Start_BswMReportFailToDemRef422.GetEventStatus
        OpEventGetEventStatus_GetEventStatus_EvtInfo_AutoCreatedDemEvent_ESH_Action_WriteAllTimer_Stop_BswMReportFailToDemRef422: start-on-event=GetEventStatus, operation=EvtInfo_AutoCreatedDemEvent_ESH_Action_WriteAllTimer_Stop_BswMReportFailToDemRef422.GetEventStatus
        OpEventGetEventStatus_GetEventStatus_EvtInfo_AutoCreatedDemEvent_ESH_Action_WriteAllTimer_Stop_BswMReportFailToDemRef_1422: start-on-event=GetEventStatus, operation=EvtInfo_AutoCreatedDemEvent_ESH_Action_WriteAllTimer_Stop_BswMReportFailToDemRef_1422.GetEventStatus
        OpEventGetEventStatus_GetEventStatus_EvtInfo_AutoCreatedDemEvent_ESH_DemInit_BswMReportFailToDemRef422: start-on-event=GetEventStatus, operation=EvtInfo_AutoCreatedDemEvent_ESH_DemInit_BswMReportFailToDemRef422.GetEventStatus
        OpEventGetEventStatus_GetEventStatus_EvtInfo_AutoCreatedDemEvent_ESH_PostRunNested_BswMReportFailToDemRef422: start-on-event=GetEventStatus, operation=EvtInfo_AutoCreatedDemEvent_ESH_PostRunNested_BswMReportFailToDemRef422.GetEventStatus
        OpEventGetEventStatus_GetEventStatus_EvtInfo_AutoCreatedDemEvent_ESH_PostRunToPrepNested_BswMReportFailToDemRef422: start-on-event=GetEventStatus, operation=EvtInfo_AutoCreatedDemEvent_ESH_PostRunToPrepNested_BswMReportFailToDemRef422.GetEventStatus
        OpEventGetEventStatus_GetEventStatus_EvtInfo_AutoCreatedDemEvent_ESH_RunToPostRunNested_BswMReportFailToDemRef422: start-on-event=GetEventStatus, operation=EvtInfo_AutoCreatedDemEvent_ESH_RunToPostRunNested_BswMReportFailToDemRef422.GetEventStatus
        OpEventGetEventStatus_GetEventStatus_EvtInfo_AutoCreatedDemEvent_FLS_E_COMPARE_FAILED422: start-on-event=GetEventStatus, operation=EvtInfo_AutoCreatedDemEvent_FLS_E_COMPARE_FAILED422.GetEventStatus
        OpEventGetEventStatus_GetEventStatus_EvtInfo_AutoCreatedDemEvent_FLS_E_ERASE_FAILED422: start-on-event=GetEventStatus, operation=EvtInfo_AutoCreatedDemEvent_FLS_E_ERASE_FAILED422.GetEventStatus
        OpEventGetEventStatus_GetEventStatus_EvtInfo_AutoCreatedDemEvent_FLS_E_READ_FAILED422: start-on-event=GetEventStatus, operation=EvtInfo_AutoCreatedDemEvent_FLS_E_READ_FAILED422.GetEventStatus
        OpEventGetEventStatus_GetEventStatus_EvtInfo_AutoCreatedDemEvent_FLS_E_UNEXPECTED_FLASH_ID422: start-on-event=GetEventStatus, operation=EvtInfo_AutoCreatedDemEvent_FLS_E_UNEXPECTED_FLASH_ID422.GetEventStatus
        OpEventGetEventStatus_GetEventStatus_EvtInfo_AutoCreatedDemEvent_FLS_E_WRITE_FAILED422: start-on-event=GetEventStatus, operation=EvtInfo_AutoCreatedDemEvent_FLS_E_WRITE_FAILED422.GetEventStatus
        OpEventGetEventStatus_GetEventStatus_EvtInfo_AutoCreatedDemEvent_GPT_E_TIMEOUT422: start-on-event=GetEventStatus, operation=EvtInfo_AutoCreatedDemEvent_GPT_E_TIMEOUT422.GetEventStatus
        OpEventGetEventStatus_GetEventStatus_EvtInfo_AutoCreatedDemEvent_INIT_Action_BrsHw_EnableHwAccess_BswMReportFailToDemRef422: start-on-event=GetEventStatus, operation=EvtInfo_AutoCreatedDemEvent_INIT_Action_BrsHw_EnableHwAccess_BswMReportFailToDemRef422.GetEventStatus
        OpEventGetEventStatus_GetEventStatus_EvtInfo_AutoCreatedDemEvent_INIT_Action_CanIf_Init_BswMReportFailToDemRef422: start-on-event=GetEventStatus, operation=EvtInfo_AutoCreatedDemEvent_INIT_Action_CanIf_Init_BswMReportFailToDemRef422.GetEventStatus
        OpEventGetEventStatus_GetEventStatus_EvtInfo_AutoCreatedDemEvent_INIT_Action_CanNm_Init_BswMReportFailToDemRef422: start-on-event=GetEventStatus, operation=EvtInfo_AutoCreatedDemEvent_INIT_Action_CanNm_Init_BswMReportFailToDemRef422.GetEventStatus
        OpEventGetEventStatus_GetEventStatus_EvtInfo_AutoCreatedDemEvent_INIT_Action_CanSM_Init_BswMReportFailToDemRef422: start-on-event=GetEventStatus, operation=EvtInfo_AutoCreatedDemEvent_INIT_Action_CanSM_Init_BswMReportFailToDemRef422.GetEventStatus
        OpEventGetEventStatus_GetEventStatus_EvtInfo_AutoCreatedDemEvent_INIT_Action_CanTp_Init_BswMReportFailToDemRef422: start-on-event=GetEventStatus, operation=EvtInfo_AutoCreatedDemEvent_INIT_Action_CanTp_Init_BswMReportFailToDemRef422.GetEventStatus
        OpEventGetEventStatus_GetEventStatus_EvtInfo_AutoCreatedDemEvent_INIT_Action_Can_Init_BswMReportFailToDemRef422: start-on-event=GetEventStatus, operation=EvtInfo_AutoCreatedDemEvent_INIT_Action_Can_Init_BswMReportFailToDemRef422.GetEventStatus
        OpEventGetEventStatus_GetEventStatus_EvtInfo_AutoCreatedDemEvent_INIT_Action_ComM_Init_BswMReportFailToDemRef422: start-on-event=GetEventStatus, operation=EvtInfo_AutoCreatedDemEvent_INIT_Action_ComM_Init_BswMReportFailToDemRef422.GetEventStatus
        OpEventGetEventStatus_GetEventStatus_EvtInfo_AutoCreatedDemEvent_INIT_Action_Com_Init_BswMReportFailToDemRef422: start-on-event=GetEventStatus, operation=EvtInfo_AutoCreatedDemEvent_INIT_Action_Com_Init_BswMReportFailToDemRef422.GetEventStatus
        OpEventGetEventStatus_GetEventStatus_EvtInfo_AutoCreatedDemEvent_INIT_Action_Dcm_Init_BswMReportFailToDemRef422: start-on-event=GetEventStatus, operation=EvtInfo_AutoCreatedDemEvent_INIT_Action_Dcm_Init_BswMReportFailToDemRef422.GetEventStatus
        OpEventGetEventStatus_GetEventStatus_EvtInfo_AutoCreatedDemEvent_INIT_Action_Dem_Init_BswMReportFailToDemRef422: start-on-event=GetEventStatus, operation=EvtInfo_AutoCreatedDemEvent_INIT_Action_Dem_Init_BswMReportFailToDemRef422.GetEventStatus
        OpEventGetEventStatus_GetEventStatus_EvtInfo_AutoCreatedDemEvent_INIT_Action_EnableInterrupts_BswMReportFailToDemRef422: start-on-event=GetEventStatus, operation=EvtInfo_AutoCreatedDemEvent_INIT_Action_EnableInterrupts_BswMReportFailToDemRef422.GetEventStatus
        OpEventGetEventStatus_GetEventStatus_EvtInfo_AutoCreatedDemEvent_INIT_Action_Fee_Init_BswMReportFailToDemRef422: start-on-event=GetEventStatus, operation=EvtInfo_AutoCreatedDemEvent_INIT_Action_Fee_Init_BswMReportFailToDemRef422.GetEventStatus
        OpEventGetEventStatus_GetEventStatus_EvtInfo_AutoCreatedDemEvent_INIT_Action_Issm_Init_BswMReportFailToDemRef422: start-on-event=GetEventStatus, operation=EvtInfo_AutoCreatedDemEvent_INIT_Action_Issm_Init_BswMReportFailToDemRef422.GetEventStatus
        OpEventGetEventStatus_GetEventStatus_EvtInfo_AutoCreatedDemEvent_INIT_Action_J1939Nm_Init_BswMReportFailToDemRef422: start-on-event=GetEventStatus, operation=EvtInfo_AutoCreatedDemEvent_INIT_Action_J1939Nm_Init_BswMReportFailToDemRef422.GetEventStatus
        OpEventGetEventStatus_GetEventStatus_EvtInfo_AutoCreatedDemEvent_INIT_Action_J1939Rm_Init_BswMReportFailToDemRef422: start-on-event=GetEventStatus, operation=EvtInfo_AutoCreatedDemEvent_INIT_Action_J1939Rm_Init_BswMReportFailToDemRef422.GetEventStatus
        OpEventGetEventStatus_GetEventStatus_EvtInfo_AutoCreatedDemEvent_INIT_Action_J1939Tp_Init_BswMReportFailToDemRef422: start-on-event=GetEventStatus, operation=EvtInfo_AutoCreatedDemEvent_INIT_Action_J1939Tp_Init_BswMReportFailToDemRef422.GetEventStatus
        OpEventGetEventStatus_GetEventStatus_EvtInfo_AutoCreatedDemEvent_INIT_Action_LinIf_Init_BswMReportFailToDemRef422: start-on-event=GetEventStatus, operation=EvtInfo_AutoCreatedDemEvent_INIT_Action_LinIf_Init_BswMReportFailToDemRef422.GetEventStatus
        OpEventGetEventStatus_GetEventStatus_EvtInfo_AutoCreatedDemEvent_INIT_Action_LinSM_Init_BswMReportFailToDemRef422: start-on-event=GetEventStatus, operation=EvtInfo_AutoCreatedDemEvent_INIT_Action_LinSM_Init_BswMReportFailToDemRef422.GetEventStatus
        OpEventGetEventStatus_GetEventStatus_EvtInfo_AutoCreatedDemEvent_INIT_Action_LinTp_Init_BswMReportFailToDemRef422: start-on-event=GetEventStatus, operation=EvtInfo_AutoCreatedDemEvent_INIT_Action_LinTp_Init_BswMReportFailToDemRef422.GetEventStatus
        OpEventGetEventStatus_GetEventStatus_EvtInfo_AutoCreatedDemEvent_INIT_Action_Lin_Init_BswMReportFailToDemRef422: start-on-event=GetEventStatus, operation=EvtInfo_AutoCreatedDemEvent_INIT_Action_Lin_Init_BswMReportFailToDemRef422.GetEventStatus
        OpEventGetEventStatus_GetEventStatus_EvtInfo_AutoCreatedDemEvent_INIT_Action_Nm_Init_BswMReportFailToDemRef422: start-on-event=GetEventStatus, operation=EvtInfo_AutoCreatedDemEvent_INIT_Action_Nm_Init_BswMReportFailToDemRef422.GetEventStatus
        OpEventGetEventStatus_GetEventStatus_EvtInfo_AutoCreatedDemEvent_INIT_Action_NvMReadAll_BswMReportFailToDemRef422: start-on-event=GetEventStatus, operation=EvtInfo_AutoCreatedDemEvent_INIT_Action_NvMReadAll_BswMReportFailToDemRef422.GetEventStatus
        OpEventGetEventStatus_GetEventStatus_EvtInfo_AutoCreatedDemEvent_INIT_Action_NvM_Init_BswMReportFailToDemRef422: start-on-event=GetEventStatus, operation=EvtInfo_AutoCreatedDemEvent_INIT_Action_NvM_Init_BswMReportFailToDemRef422.GetEventStatus
        OpEventGetEventStatus_GetEventStatus_EvtInfo_AutoCreatedDemEvent_INIT_Action_PduR_Init_BswMReportFailToDemRef422: start-on-event=GetEventStatus, operation=EvtInfo_AutoCreatedDemEvent_INIT_Action_PduR_Init_BswMReportFailToDemRef422.GetEventStatus
        OpEventGetEventStatus_GetEventStatus_EvtInfo_AutoCreatedDemEvent_INIT_Action_RteStart_BswMReportFailToDemRef422: start-on-event=GetEventStatus, operation=EvtInfo_AutoCreatedDemEvent_INIT_Action_RteStart_BswMReportFailToDemRef422.GetEventStatus
        OpEventGetEventStatus_GetEventStatus_EvtInfo_AutoCreatedDemEvent_J1939NM_E_ADDRESS_LOST422: start-on-event=GetEventStatus, operation=EvtInfo_AutoCreatedDemEvent_J1939NM_E_ADDRESS_LOST422.GetEventStatus
        OpEventGetEventStatus_GetEventStatus_EvtInfo_AutoCreatedDemEvent_J1939TpConfiguration_J1939TP_E_COMMUNICATION422: start-on-event=GetEventStatus, operation=EvtInfo_AutoCreatedDemEvent_J1939TpConfiguration_J1939TP_E_COMMUNICATION422.GetEventStatus
        OpEventGetEventStatus_GetEventStatus_EvtInfo_AutoCreatedDemEvent_LIN_E_TIMEOUT422: start-on-event=GetEventStatus, operation=EvtInfo_AutoCreatedDemEvent_LIN_E_TIMEOUT422.GetEventStatus
        OpEventGetEventStatus_GetEventStatus_EvtInfo_AutoCreatedDemEvent_MCL_E_DMA_BUS422: start-on-event=GetEventStatus, operation=EvtInfo_AutoCreatedDemEvent_MCL_E_DMA_BUS422.GetEventStatus
        OpEventGetEventStatus_GetEventStatus_EvtInfo_AutoCreatedDemEvent_MCL_E_DMA_DESCRIPTOR422: start-on-event=GetEventStatus, operation=EvtInfo_AutoCreatedDemEvent_MCL_E_DMA_DESCRIPTOR422.GetEventStatus
        OpEventGetEventStatus_GetEventStatus_EvtInfo_AutoCreatedDemEvent_MCL_E_DMA_ECC422: start-on-event=GetEventStatus, operation=EvtInfo_AutoCreatedDemEvent_MCL_E_DMA_ECC422.GetEventStatus
        OpEventGetEventStatus_GetEventStatus_EvtInfo_AutoCreatedDemEvent_MCL_E_DMA_INCONSISTENCY422: start-on-event=GetEventStatus, operation=EvtInfo_AutoCreatedDemEvent_MCL_E_DMA_INCONSISTENCY422.GetEventStatus
        OpEventGetEventStatus_GetEventStatus_EvtInfo_AutoCreatedDemEvent_MCL_E_DMA_PRIORITY422: start-on-event=GetEventStatus, operation=EvtInfo_AutoCreatedDemEvent_MCL_E_DMA_PRIORITY422.GetEventStatus
        OpEventGetEventStatus_GetEventStatus_EvtInfo_AutoCreatedDemEvent_MCL_E_DMA_UNRECOGNIZED422: start-on-event=GetEventStatus, operation=EvtInfo_AutoCreatedDemEvent_MCL_E_DMA_UNRECOGNIZED422.GetEventStatus
        OpEventGetEventStatus_GetEventStatus_EvtInfo_AutoCreatedDemEvent_MCU_E_CLOCK_FAILURE422: start-on-event=GetEventStatus, operation=EvtInfo_AutoCreatedDemEvent_MCU_E_CLOCK_FAILURE422.GetEventStatus
        OpEventGetEventStatus_GetEventStatus_EvtInfo_AutoCreatedDemEvent_MCU_E_INVALIDMODE_CONFIG422: start-on-event=GetEventStatus, operation=EvtInfo_AutoCreatedDemEvent_MCU_E_INVALIDMODE_CONFIG422.GetEventStatus
        OpEventGetEventStatus_GetEventStatus_EvtInfo_AutoCreatedDemEvent_MCU_E_SSCM_CER_FAILURE422: start-on-event=GetEventStatus, operation=EvtInfo_AutoCreatedDemEvent_MCU_E_SSCM_CER_FAILURE422.GetEventStatus
        OpEventGetEventStatus_GetEventStatus_EvtInfo_AutoCreatedDemEvent_MCU_E_TIMEOUT_FAILURE422: start-on-event=GetEventStatus, operation=EvtInfo_AutoCreatedDemEvent_MCU_E_TIMEOUT_FAILURE422.GetEventStatus
        OpEventGetEventStatus_GetEventStatus_EvtInfo_AutoCreatedDemEvent_NVM_E_INTEGRITY_FAILED422: start-on-event=GetEventStatus, operation=EvtInfo_AutoCreatedDemEvent_NVM_E_INTEGRITY_FAILED422.GetEventStatus
        OpEventGetEventStatus_GetEventStatus_EvtInfo_AutoCreatedDemEvent_NVM_E_LOSS_OF_REDUNDANCY422: start-on-event=GetEventStatus, operation=EvtInfo_AutoCreatedDemEvent_NVM_E_LOSS_OF_REDUNDANCY422.GetEventStatus
        OpEventGetEventStatus_GetEventStatus_EvtInfo_AutoCreatedDemEvent_NVM_E_QUEUE_OVERFLOW422: start-on-event=GetEventStatus, operation=EvtInfo_AutoCreatedDemEvent_NVM_E_QUEUE_OVERFLOW422.GetEventStatus
        OpEventGetEventStatus_GetEventStatus_EvtInfo_AutoCreatedDemEvent_NVM_E_REQ_FAILED422: start-on-event=GetEventStatus, operation=EvtInfo_AutoCreatedDemEvent_NVM_E_REQ_FAILED422.GetEventStatus
        OpEventGetEventStatus_GetEventStatus_EvtInfo_AutoCreatedDemEvent_NVM_E_VERIFY_FAILED422: start-on-event=GetEventStatus, operation=EvtInfo_AutoCreatedDemEvent_NVM_E_VERIFY_FAILED422.GetEventStatus
        OpEventGetEventStatus_GetEventStatus_EvtInfo_AutoCreatedDemEvent_NVM_E_WRITE_PROTECTED422: start-on-event=GetEventStatus, operation=EvtInfo_AutoCreatedDemEvent_NVM_E_WRITE_PROTECTED422.GetEventStatus
        OpEventGetEventStatus_GetEventStatus_EvtInfo_AutoCreatedDemEvent_NVM_E_WRONG_BLOCK_ID422: start-on-event=GetEventStatus, operation=EvtInfo_AutoCreatedDemEvent_NVM_E_WRONG_BLOCK_ID422.GetEventStatus
        OpEventGetEventStatus_GetEventStatus_EvtInfo_AutoCreatedDemEvent_SPI_E_HARDWARE_ERROR422: start-on-event=GetEventStatus, operation=EvtInfo_AutoCreatedDemEvent_SPI_E_HARDWARE_ERROR422.GetEventStatus
        OpEventGetEventStatus_GetEventStatus_EvtInfo_AutoCreatedDemEvent_SpiDriver_SPI_E_HARDWARE_ERROR422: start-on-event=GetEventStatus, operation=EvtInfo_AutoCreatedDemEvent_SpiDriver_SPI_E_HARDWARE_ERROR422.GetEventStatus
        OpEventGetEventStatus_GetEventStatus_EvtInfo_AutoCreatedDemEvent_WDG_E_CORRUPT_CONFIG422: start-on-event=GetEventStatus, operation=EvtInfo_AutoCreatedDemEvent_WDG_E_CORRUPT_CONFIG422.GetEventStatus
        OpEventGetEventStatus_GetEventStatus_EvtInfo_AutoCreatedDemEvent_WDG_E_DISABLE_REJECTED422: start-on-event=GetEventStatus, operation=EvtInfo_AutoCreatedDemEvent_WDG_E_DISABLE_REJECTED422.GetEventStatus
        OpEventGetEventStatus_GetEventStatus_EvtInfo_AutoCreatedDemEvent_WDG_E_FORBIDDEN_INVOCATION422: start-on-event=GetEventStatus, operation=EvtInfo_AutoCreatedDemEvent_WDG_E_FORBIDDEN_INVOCATION422.GetEventStatus
        OpEventGetEventStatus_GetEventStatus_EvtInfo_AutoCreatedDemEvent_WDG_E_INVALID_CALL422: start-on-event=GetEventStatus, operation=EvtInfo_AutoCreatedDemEvent_WDG_E_INVALID_CALL422.GetEventStatus
        OpEventGetEventStatus_GetEventStatus_EvtInfo_AutoCreatedDemEvent_WDG_E_INVALID_PARAMETER422: start-on-event=GetEventStatus, operation=EvtInfo_AutoCreatedDemEvent_WDG_E_INVALID_PARAMETER422.GetEventStatus
        OpEventGetEventStatus_GetEventStatus_EvtInfo_AutoCreatedDemEvent_WDG_E_MODE_FAILED422: start-on-event=GetEventStatus, operation=EvtInfo_AutoCreatedDemEvent_WDG_E_MODE_FAILED422.GetEventStatus
        OpEventGetEventStatus_GetEventStatus_EvtInfo_AutoCreatedDemEvent_WDG_E_UNLOCKED422: start-on-event=GetEventStatus, operation=EvtInfo_AutoCreatedDemEvent_WDG_E_UNLOCKED422.GetEventStatus
        OpEventGetEventFailed_GetEventFailed_EvtInfo_AutoCreatedDemEvent_ADC_E_TIMEOUT422: start-on-event=GetEventFailed, operation=EvtInfo_AutoCreatedDemEvent_ADC_E_TIMEOUT422.GetEventFailed
        OpEventGetEventFailed_GetEventFailed_EvtInfo_AutoCreatedDemEvent_CC_DisableDM_CIOM_oBackbone1J1939_Rx_BC_405bc776_BswMR_606ecfb1: start-on-event=GetEventFailed, operation=EvtInfo_AutoCreatedDemEvent_CC_DisableDM_CIOM_oBackbone1J1939_Rx_BC_405bc776_BswMReportFailToDemRef422.GetEventFailed
        OpEventGetEventFailed_GetEventFailed_EvtInfo_AutoCreatedDemEvent_CC_DisableDM_CIOM_oBackbone2_Rx_4e624434_BswMReportFai_00d16a1b: start-on-event=GetEventFailed, operation=EvtInfo_AutoCreatedDemEvent_CC_DisableDM_CIOM_oBackbone2_Rx_4e624434_BswMReportFailToDemRef422.GetEventFailed
        OpEventGetEventFailed_GetEventFailed_EvtInfo_AutoCreatedDemEvent_CC_DisableDM_CIOM_oCabSubnet_Rx_063a5fbc_BswMReportFai_7d932191: start-on-event=GetEventFailed, operation=EvtInfo_AutoCreatedDemEvent_CC_DisableDM_CIOM_oCabSubnet_Rx_063a5fbc_BswMReportFailToDemRef422.GetEventFailed
        OpEventGetEventFailed_GetEventFailed_EvtInfo_AutoCreatedDemEvent_CC_DisableDM_CIOM_oFMSNet_Rx_BC_dd2c1510_BswMReportFai_6283e017: start-on-event=GetEventFailed, operation=EvtInfo_AutoCreatedDemEvent_CC_DisableDM_CIOM_oFMSNet_Rx_BC_dd2c1510_BswMReportFailToDemRef422.GetEventFailed
        OpEventGetEventFailed_GetEventFailed_EvtInfo_AutoCreatedDemEvent_CC_DisableDM_CIOM_oSecuritySubnet_Rx_3a3c1dbc_BswMRepo_7b1e9ff0: start-on-event=GetEventFailed, operation=EvtInfo_AutoCreatedDemEvent_CC_DisableDM_CIOM_oSecuritySubnet_Rx_3a3c1dbc_BswMReportFailToDemRef422.GetEventFailed
        OpEventGetEventFailed_GetEventFailed_EvtInfo_AutoCreatedDemEvent_CC_DisablePDUGroup_CIOM_oBackbone1J1939_Rx_BC_405bc776_a3346d01: start-on-event=GetEventFailed, operation=EvtInfo_AutoCreatedDemEvent_CC_DisablePDUGroup_CIOM_oBackbone1J1939_Rx_BC_405bc776_BswMReportFailToDemRef422.GetEventFailed
        OpEventGetEventFailed_GetEventFailed_EvtInfo_AutoCreatedDemEvent_CC_DisablePDUGroup_CIOM_oBackbone1J1939_Tx_0x31_BC_378_99cfbb9b: start-on-event=GetEventFailed, operation=EvtInfo_AutoCreatedDemEvent_CC_DisablePDUGroup_CIOM_oBackbone1J1939_Tx_0x31_BC_3782f500_BswMReportFailToDemRef422.GetEventFailed
        OpEventGetEventFailed_GetEventFailed_EvtInfo_AutoCreatedDemEvent_CC_DisablePDUGroup_CIOM_oBackbone2_Rx_4e624434_BswMRep_34485bd4: start-on-event=GetEventFailed, operation=EvtInfo_AutoCreatedDemEvent_CC_DisablePDUGroup_CIOM_oBackbone2_Rx_4e624434_BswMReportFailToDemRef422.GetEventFailed
        OpEventGetEventFailed_GetEventFailed_EvtInfo_AutoCreatedDemEvent_CC_DisablePDUGroup_CIOM_oBackbone2_Tx_1838e3b2_BswMRep_389efdfa: start-on-event=GetEventFailed, operation=EvtInfo_AutoCreatedDemEvent_CC_DisablePDUGroup_CIOM_oBackbone2_Tx_1838e3b2_BswMReportFailToDemRef422.GetEventFailed
        OpEventGetEventFailed_GetEventFailed_EvtInfo_AutoCreatedDemEvent_CC_DisablePDUGroup_CIOM_oCabSubnet_Rx_063a5fbc_BswMRep_490a105e: start-on-event=GetEventFailed, operation=EvtInfo_AutoCreatedDemEvent_CC_DisablePDUGroup_CIOM_oCabSubnet_Rx_063a5fbc_BswMReportFailToDemRef422.GetEventFailed
        OpEventGetEventFailed_GetEventFailed_EvtInfo_AutoCreatedDemEvent_CC_DisablePDUGroup_CIOM_oCabSubnet_Tx_5060f83a_BswMRep_db784f6c: start-on-event=GetEventFailed, operation=EvtInfo_AutoCreatedDemEvent_CC_DisablePDUGroup_CIOM_oCabSubnet_Tx_5060f83a_BswMReportFailToDemRef422.GetEventFailed
        OpEventGetEventFailed_GetEventFailed_EvtInfo_AutoCreatedDemEvent_CC_DisablePDUGroup_CIOM_oFMSNet_Rx_BC_dd2c1510_BswMRep_561ad1d8: start-on-event=GetEventFailed, operation=EvtInfo_AutoCreatedDemEvent_CC_DisablePDUGroup_CIOM_oFMSNet_Rx_BC_dd2c1510_BswMReportFailToDemRef422.GetEventFailed
        OpEventGetEventFailed_GetEventFailed_EvtInfo_AutoCreatedDemEvent_CC_DisablePDUGroup_CIOM_oFMSNet_Tx_0x31_BC_38fc8c7d_Bs_a1e95e1a: start-on-event=GetEventFailed, operation=EvtInfo_AutoCreatedDemEvent_CC_DisablePDUGroup_CIOM_oFMSNet_Tx_0x31_BC_38fc8c7d_BswMReportFailToDemRef422.GetEventFailed
        OpEventGetEventFailed_GetEventFailed_EvtInfo_AutoCreatedDemEvent_CC_DisablePDUGroup_CIOM_oLIN00_Rx_dd181faa_BswMReportF_c3ab7e39: start-on-event=GetEventFailed, operation=EvtInfo_AutoCreatedDemEvent_CC_DisablePDUGroup_CIOM_oLIN00_Rx_dd181faa_BswMReportFailToDemRef422.GetEventFailed
        OpEventGetEventFailed_GetEventFailed_EvtInfo_AutoCreatedDemEvent_CC_DisablePDUGroup_CIOM_oLIN00_Tx_8b42b82c_BswMReportF_bf4cb0f0: start-on-event=GetEventFailed, operation=EvtInfo_AutoCreatedDemEvent_CC_DisablePDUGroup_CIOM_oLIN00_Tx_8b42b82c_BswMReportFailToDemRef422.GetEventFailed
        OpEventGetEventFailed_GetEventFailed_EvtInfo_AutoCreatedDemEvent_CC_DisablePDUGroup_CIOM_oLIN01_Rx_65a478cf_BswMReportF_fa1b593c: start-on-event=GetEventFailed, operation=EvtInfo_AutoCreatedDemEvent_CC_DisablePDUGroup_CIOM_oLIN01_Rx_65a478cf_BswMReportFailToDemRef422.GetEventFailed
        OpEventGetEventFailed_GetEventFailed_EvtInfo_AutoCreatedDemEvent_CC_DisablePDUGroup_CIOM_oLIN01_Tx_33fedf49_BswMReportF_6488a39b: start-on-event=GetEventFailed, operation=EvtInfo_AutoCreatedDemEvent_CC_DisablePDUGroup_CIOM_oLIN01_Tx_33fedf49_BswMReportFailToDemRef422.GetEventFailed
        OpEventGetEventFailed_GetEventFailed_EvtInfo_AutoCreatedDemEvent_CC_DisablePDUGroup_CIOM_oLIN02_Rx_7711d721_BswMReportF_1402a5c8: start-on-event=GetEventFailed, operation=EvtInfo_AutoCreatedDemEvent_CC_DisablePDUGroup_CIOM_oLIN02_Rx_7711d721_BswMReportFailToDemRef422.GetEventFailed
        OpEventGetEventFailed_GetEventFailed_EvtInfo_AutoCreatedDemEvent_CC_DisablePDUGroup_CIOM_oLIN02_Tx_214b70a7_BswMReportF_c4371573: start-on-event=GetEventFailed, operation=EvtInfo_AutoCreatedDemEvent_CC_DisablePDUGroup_CIOM_oLIN02_Tx_214b70a7_BswMReportFailToDemRef422.GetEventFailed
        OpEventGetEventFailed_GetEventFailed_EvtInfo_AutoCreatedDemEvent_CC_DisablePDUGroup_CIOM_oLIN03_Rx_cfadb044_BswMReportF_886c1250: start-on-event=GetEventFailed, operation=EvtInfo_AutoCreatedDemEvent_CC_DisablePDUGroup_CIOM_oLIN03_Rx_cfadb044_BswMReportFailToDemRef422.GetEventFailed
        OpEventGetEventFailed_GetEventFailed_EvtInfo_AutoCreatedDemEvent_CC_DisablePDUGroup_CIOM_oLIN03_Tx_99f717c2_BswMReportF_87db0c04: start-on-event=GetEventFailed, operation=EvtInfo_AutoCreatedDemEvent_CC_DisablePDUGroup_CIOM_oLIN03_Tx_99f717c2_BswMReportFailToDemRef422.GetEventFailed
        OpEventGetEventFailed_GetEventFailed_EvtInfo_AutoCreatedDemEvent_CC_DisablePDUGroup_CIOM_oLIN04_Rx_527a88fd_BswMReportF_1adfcf14: start-on-event=GetEventFailed, operation=EvtInfo_AutoCreatedDemEvent_CC_DisablePDUGroup_CIOM_oLIN04_Rx_527a88fd_BswMReportFailToDemRef422.GetEventFailed
        OpEventGetEventFailed_GetEventFailed_EvtInfo_AutoCreatedDemEvent_CC_DisablePDUGroup_CIOM_oLIN04_Tx_04202f7b_BswMReportF_85d7cc21: start-on-event=GetEventFailed, operation=EvtInfo_AutoCreatedDemEvent_CC_DisablePDUGroup_CIOM_oLIN04_Tx_04202f7b_BswMReportFailToDemRef422.GetEventFailed
        OpEventGetEventFailed_GetEventFailed_EvtInfo_AutoCreatedDemEvent_CC_DisablePDUGroup_CIOM_oSecuritySubnet_Rx_3a3c1dbc_Bs_11240fb6: start-on-event=GetEventFailed, operation=EvtInfo_AutoCreatedDemEvent_CC_DisablePDUGroup_CIOM_oSecuritySubnet_Rx_3a3c1dbc_BswMReportFailToDemRef422.GetEventFailed
        OpEventGetEventFailed_GetEventFailed_EvtInfo_AutoCreatedDemEvent_CC_DisablePDUGroup_CIOM_oSecuritySubnet_Tx_6c66ba3a_Bs_98aead10: start-on-event=GetEventFailed, operation=EvtInfo_AutoCreatedDemEvent_CC_DisablePDUGroup_CIOM_oSecuritySubnet_Tx_6c66ba3a_BswMReportFailToDemRef422.GetEventFailed
        OpEventGetEventFailed_GetEventFailed_EvtInfo_AutoCreatedDemEvent_CC_EnableDM_CIOM_oBackbone1J1939_Rx_BC_405bc776_BswMRe_f49a21ff: start-on-event=GetEventFailed, operation=EvtInfo_AutoCreatedDemEvent_CC_EnableDM_CIOM_oBackbone1J1939_Rx_BC_405bc776_BswMReportFailToDemRef422.GetEventFailed
        OpEventGetEventFailed_GetEventFailed_EvtInfo_AutoCreatedDemEvent_CC_EnableDM_CIOM_oBackbone2_Rx_4e624434_BswMReportFail_67fad38e: start-on-event=GetEventFailed, operation=EvtInfo_AutoCreatedDemEvent_CC_EnableDM_CIOM_oBackbone2_Rx_4e624434_BswMReportFailToDemRef422.GetEventFailed
        OpEventGetEventFailed_GetEventFailed_EvtInfo_AutoCreatedDemEvent_CC_EnableDM_CIOM_oCabSubnet_Rx_063a5fbc_BswMReportFail_1ab89804: start-on-event=GetEventFailed, operation=EvtInfo_AutoCreatedDemEvent_CC_EnableDM_CIOM_oCabSubnet_Rx_063a5fbc_BswMReportFailToDemRef422.GetEventFailed
        OpEventGetEventFailed_GetEventFailed_EvtInfo_AutoCreatedDemEvent_CC_EnableDM_CIOM_oFMSNet_Rx_BC_dd2c1510_BswMReportFail_05a85982: start-on-event=GetEventFailed, operation=EvtInfo_AutoCreatedDemEvent_CC_EnableDM_CIOM_oFMSNet_Rx_BC_dd2c1510_BswMReportFailToDemRef422.GetEventFailed
        OpEventGetEventFailed_GetEventFailed_EvtInfo_AutoCreatedDemEvent_CC_EnableDM_CIOM_oSecuritySubnet_Rx_3a3c1dbc_BswMRepor_1c2662e1: start-on-event=GetEventFailed, operation=EvtInfo_AutoCreatedDemEvent_CC_EnableDM_CIOM_oSecuritySubnet_Rx_3a3c1dbc_BswMReportFailToDemRef422.GetEventFailed
        OpEventGetEventFailed_GetEventFailed_EvtInfo_AutoCreatedDemEvent_CC_EnablePDUGroup_CIOM_oBackbone1J1939_Rx_BC_405bc776_f29cee7f: start-on-event=GetEventFailed, operation=EvtInfo_AutoCreatedDemEvent_CC_EnablePDUGroup_CIOM_oBackbone1J1939_Rx_BC_405bc776_BswMReportFailToDemRef422.GetEventFailed
        OpEventGetEventFailed_GetEventFailed_EvtInfo_AutoCreatedDemEvent_CC_EnablePDUGroup_CIOM_oBackbone1J1939_Tx_0x31_BC_3782_540a9c2d: start-on-event=GetEventFailed, operation=EvtInfo_AutoCreatedDemEvent_CC_EnablePDUGroup_CIOM_oBackbone1J1939_Tx_0x31_BC_3782f500_BswMReportFailToDemRef422.GetEventFailed
        OpEventGetEventFailed_GetEventFailed_EvtInfo_AutoCreatedDemEvent_CC_EnablePDUGroup_CIOM_oBackbone2_Rx_4e624434_BswMRepo_5e9f43db: start-on-event=GetEventFailed, operation=EvtInfo_AutoCreatedDemEvent_CC_EnablePDUGroup_CIOM_oBackbone2_Rx_4e624434_BswMReportFailToDemRef422.GetEventFailed
        OpEventGetEventFailed_GetEventFailed_EvtInfo_AutoCreatedDemEvent_CC_EnablePDUGroup_CIOM_oBackbone2_Tx_1838e3b2_BswMRepo_5249e5f5: start-on-event=GetEventFailed, operation=EvtInfo_AutoCreatedDemEvent_CC_EnablePDUGroup_CIOM_oBackbone2_Tx_1838e3b2_BswMReportFailToDemRef422.GetEventFailed
        OpEventGetEventFailed_GetEventFailed_EvtInfo_AutoCreatedDemEvent_CC_EnablePDUGroup_CIOM_oCabSubnet_Rx_063a5fbc_BswMRepo_23dd0851: start-on-event=GetEventFailed, operation=EvtInfo_AutoCreatedDemEvent_CC_EnablePDUGroup_CIOM_oCabSubnet_Rx_063a5fbc_BswMReportFailToDemRef422.GetEventFailed
        OpEventGetEventFailed_GetEventFailed_EvtInfo_AutoCreatedDemEvent_CC_EnablePDUGroup_CIOM_oCabSubnet_Tx_5060f83a_BswMRepo_b1af5763: start-on-event=GetEventFailed, operation=EvtInfo_AutoCreatedDemEvent_CC_EnablePDUGroup_CIOM_oCabSubnet_Tx_5060f83a_BswMReportFailToDemRef422.GetEventFailed
        OpEventGetEventFailed_GetEventFailed_EvtInfo_AutoCreatedDemEvent_CC_EnablePDUGroup_CIOM_oFMSNet_Rx_BC_dd2c1510_BswMRepo_3ccdc9d7: start-on-event=GetEventFailed, operation=EvtInfo_AutoCreatedDemEvent_CC_EnablePDUGroup_CIOM_oFMSNet_Rx_BC_dd2c1510_BswMReportFailToDemRef422.GetEventFailed
        OpEventGetEventFailed_GetEventFailed_EvtInfo_AutoCreatedDemEvent_CC_EnablePDUGroup_CIOM_oFMSNet_Tx_0x31_BC_38fc8c7d_Bsw_a1c01623: start-on-event=GetEventFailed, operation=EvtInfo_AutoCreatedDemEvent_CC_EnablePDUGroup_CIOM_oFMSNet_Tx_0x31_BC_38fc8c7d_BswMReportFailToDemRef422.GetEventFailed
        OpEventGetEventFailed_GetEventFailed_EvtInfo_AutoCreatedDemEvent_CC_EnablePDUGroup_CIOM_oLIN00_Rx_dd181faa_BswMReportFa_7d206c65: start-on-event=GetEventFailed, operation=EvtInfo_AutoCreatedDemEvent_CC_EnablePDUGroup_CIOM_oLIN00_Rx_dd181faa_BswMReportFailToDemRef422.GetEventFailed
        OpEventGetEventFailed_GetEventFailed_EvtInfo_AutoCreatedDemEvent_CC_EnablePDUGroup_CIOM_oLIN00_Tx_8b42b82c_BswMReportFa_01c7a2ac: start-on-event=GetEventFailed, operation=EvtInfo_AutoCreatedDemEvent_CC_EnablePDUGroup_CIOM_oLIN00_Tx_8b42b82c_BswMReportFailToDemRef422.GetEventFailed
        OpEventGetEventFailed_GetEventFailed_EvtInfo_AutoCreatedDemEvent_CC_EnablePDUGroup_CIOM_oLIN01_Rx_65a478cf_BswMReportFa_44904b60: start-on-event=GetEventFailed, operation=EvtInfo_AutoCreatedDemEvent_CC_EnablePDUGroup_CIOM_oLIN01_Rx_65a478cf_BswMReportFailToDemRef422.GetEventFailed
        OpEventGetEventFailed_GetEventFailed_EvtInfo_AutoCreatedDemEvent_CC_EnablePDUGroup_CIOM_oLIN01_Tx_33fedf49_BswMReportFa_da03b1c7: start-on-event=GetEventFailed, operation=EvtInfo_AutoCreatedDemEvent_CC_EnablePDUGroup_CIOM_oLIN01_Tx_33fedf49_BswMReportFailToDemRef422.GetEventFailed
        OpEventGetEventFailed_GetEventFailed_EvtInfo_AutoCreatedDemEvent_CC_EnablePDUGroup_CIOM_oLIN02_Rx_7711d721_BswMReportFa_aa89b794: start-on-event=GetEventFailed, operation=EvtInfo_AutoCreatedDemEvent_CC_EnablePDUGroup_CIOM_oLIN02_Rx_7711d721_BswMReportFailToDemRef422.GetEventFailed
        OpEventGetEventFailed_GetEventFailed_EvtInfo_AutoCreatedDemEvent_CC_EnablePDUGroup_CIOM_oLIN02_Tx_214b70a7_BswMReportFa_7abc072f: start-on-event=GetEventFailed, operation=EvtInfo_AutoCreatedDemEvent_CC_EnablePDUGroup_CIOM_oLIN02_Tx_214b70a7_BswMReportFailToDemRef422.GetEventFailed
        OpEventGetEventFailed_GetEventFailed_EvtInfo_AutoCreatedDemEvent_CC_EnablePDUGroup_CIOM_oLIN03_Rx_cfadb044_BswMReportFa_36e7000c: start-on-event=GetEventFailed, operation=EvtInfo_AutoCreatedDemEvent_CC_EnablePDUGroup_CIOM_oLIN03_Rx_cfadb044_BswMReportFailToDemRef422.GetEventFailed
        OpEventGetEventFailed_GetEventFailed_EvtInfo_AutoCreatedDemEvent_CC_EnablePDUGroup_CIOM_oLIN03_Tx_99f717c2_BswMReportFa_39501e58: start-on-event=GetEventFailed, operation=EvtInfo_AutoCreatedDemEvent_CC_EnablePDUGroup_CIOM_oLIN03_Tx_99f717c2_BswMReportFailToDemRef422.GetEventFailed
        OpEventGetEventFailed_GetEventFailed_EvtInfo_AutoCreatedDemEvent_CC_EnablePDUGroup_CIOM_oLIN04_Rx_527a88fd_BswMReportFa_a454dd48: start-on-event=GetEventFailed, operation=EvtInfo_AutoCreatedDemEvent_CC_EnablePDUGroup_CIOM_oLIN04_Rx_527a88fd_BswMReportFailToDemRef422.GetEventFailed
        OpEventGetEventFailed_GetEventFailed_EvtInfo_AutoCreatedDemEvent_CC_EnablePDUGroup_CIOM_oLIN04_Tx_04202f7b_BswMReportFa_3b5cde7d: start-on-event=GetEventFailed, operation=EvtInfo_AutoCreatedDemEvent_CC_EnablePDUGroup_CIOM_oLIN04_Tx_04202f7b_BswMReportFailToDemRef422.GetEventFailed
        OpEventGetEventFailed_GetEventFailed_EvtInfo_AutoCreatedDemEvent_CC_EnablePDUGroup_CIOM_oSecuritySubnet_Rx_3a3c1dbc_Bsw_110d478f: start-on-event=GetEventFailed, operation=EvtInfo_AutoCreatedDemEvent_CC_EnablePDUGroup_CIOM_oSecuritySubnet_Rx_3a3c1dbc_BswMReportFailToDemRef422.GetEventFailed
        OpEventGetEventFailed_GetEventFailed_EvtInfo_AutoCreatedDemEvent_CC_EnablePDUGroup_CIOM_oSecuritySubnet_Tx_6c66ba3a_Bsw_9887e529: start-on-event=GetEventFailed, operation=EvtInfo_AutoCreatedDemEvent_CC_EnablePDUGroup_CIOM_oSecuritySubnet_Tx_6c66ba3a_BswMReportFailToDemRef422.GetEventFailed
        OpEventGetEventFailed_GetEventFailed_EvtInfo_AutoCreatedDemEvent_CC_J1939RmStateSwitch_CN_Backbone1J1939_0b1f4bae_CIOM_6eb96cba: start-on-event=GetEventFailed, operation=EvtInfo_AutoCreatedDemEvent_CC_J1939RmStateSwitch_CN_Backbone1J1939_0b1f4bae_CIOM_4d5cd289_J1939RM_STATE_OFFLINE_BswMRe_f9c55035.GetEventFailed
        OpEventGetEventFailed_GetEventFailed_EvtInfo_AutoCreatedDemEvent_CC_J1939RmStateSwitch_CN_Backbone1J1939_0b1f4bae_CIOM_28e5e9b0: start-on-event=GetEventFailed, operation=EvtInfo_AutoCreatedDemEvent_CC_J1939RmStateSwitch_CN_Backbone1J1939_0b1f4bae_CIOM_4d5cd289_J1939RM_STATE_ONLINE_BswMRep_5375d7eb.GetEventFailed
        OpEventGetEventFailed_GetEventFailed_EvtInfo_AutoCreatedDemEvent_CC_J1939RmStateSwitch_CN_FMSNet_fce1aae5_CIOM_3a3d59b1_36984c54: start-on-event=GetEventFailed, operation=EvtInfo_AutoCreatedDemEvent_CC_J1939RmStateSwitch_CN_FMSNet_fce1aae5_CIOM_3a3d59b1_J1939RM_STATE_OFFLINE_BswMReportFail_5f9bde08.GetEventFailed
        OpEventGetEventFailed_GetEventFailed_EvtInfo_AutoCreatedDemEvent_CC_J1939RmStateSwitch_CN_FMSNet_fce1aae5_CIOM_3a3d59b1_d88040da: start-on-event=GetEventFailed, operation=EvtInfo_AutoCreatedDemEvent_CC_J1939RmStateSwitch_CN_FMSNet_fce1aae5_CIOM_3a3d59b1_J1939RM_STATE_ONLINE_BswMReportFailT_e97c0723.GetEventFailed
        OpEventGetEventFailed_GetEventFailed_EvtInfo_AutoCreatedDemEvent_CHNL_53cce282_CANSM_E_BUS_OFF422: start-on-event=GetEventFailed, operation=EvtInfo_AutoCreatedDemEvent_CHNL_53cce282_CANSM_E_BUS_OFF422.GetEventFailed
        OpEventGetEventFailed_GetEventFailed_EvtInfo_AutoCreatedDemEvent_CHNL_53cce282_CANSM_E_MODE_REQUEST_TIMEOUT422: start-on-event=GetEventFailed, operation=EvtInfo_AutoCreatedDemEvent_CHNL_53cce282_CANSM_E_MODE_REQUEST_TIMEOUT422.GetEventFailed
        OpEventGetEventFailed_GetEventFailed_EvtInfo_AutoCreatedDemEvent_CHNL_17344684_CANSM_E_BUS_OFF422: start-on-event=GetEventFailed, operation=EvtInfo_AutoCreatedDemEvent_CHNL_17344684_CANSM_E_BUS_OFF422.GetEventFailed
        OpEventGetEventFailed_GetEventFailed_EvtInfo_AutoCreatedDemEvent_CHNL_17344684_CANSM_E_MODE_REQUEST_TIMEOUT422: start-on-event=GetEventFailed, operation=EvtInfo_AutoCreatedDemEvent_CHNL_17344684_CANSM_E_MODE_REQUEST_TIMEOUT422.GetEventFailed
        OpEventGetEventFailed_GetEventFailed_EvtInfo_AutoCreatedDemEvent_CHNL_a6b6a922_CANSM_E_BUS_OFF422: start-on-event=GetEventFailed, operation=EvtInfo_AutoCreatedDemEvent_CHNL_a6b6a922_CANSM_E_BUS_OFF422.GetEventFailed
        OpEventGetEventFailed_GetEventFailed_EvtInfo_AutoCreatedDemEvent_CHNL_a6b6a922_CANSM_E_MODE_REQUEST_TIMEOUT422: start-on-event=GetEventFailed, operation=EvtInfo_AutoCreatedDemEvent_CHNL_a6b6a922_CANSM_E_MODE_REQUEST_TIMEOUT422.GetEventFailed
        OpEventGetEventFailed_GetEventFailed_EvtInfo_AutoCreatedDemEvent_CHNL_df893ad5_CANSM_E_BUS_OFF422: start-on-event=GetEventFailed, operation=EvtInfo_AutoCreatedDemEvent_CHNL_df893ad5_CANSM_E_BUS_OFF422.GetEventFailed
        OpEventGetEventFailed_GetEventFailed_EvtInfo_AutoCreatedDemEvent_CHNL_df893ad5_CANSM_E_MODE_REQUEST_TIMEOUT422: start-on-event=GetEventFailed, operation=EvtInfo_AutoCreatedDemEvent_CHNL_df893ad5_CANSM_E_MODE_REQUEST_TIMEOUT422.GetEventFailed
        OpEventGetEventFailed_GetEventFailed_EvtInfo_AutoCreatedDemEvent_CHNL_e058b4ae_CANSM_E_BUS_OFF422: start-on-event=GetEventFailed, operation=EvtInfo_AutoCreatedDemEvent_CHNL_e058b4ae_CANSM_E_BUS_OFF422.GetEventFailed
        OpEventGetEventFailed_GetEventFailed_EvtInfo_AutoCreatedDemEvent_CHNL_e058b4ae_CANSM_E_MODE_REQUEST_TIMEOUT422: start-on-event=GetEventFailed, operation=EvtInfo_AutoCreatedDemEvent_CHNL_e058b4ae_CANSM_E_MODE_REQUEST_TIMEOUT422.GetEventFailed
        OpEventGetEventFailed_GetEventFailed_EvtInfo_AutoCreatedDemEvent_ECUM_E_ALL_RUN_REQUESTS_KILLED422: start-on-event=GetEventFailed, operation=EvtInfo_AutoCreatedDemEvent_ECUM_E_ALL_RUN_REQUESTS_KILLED422.GetEventFailed
        OpEventGetEventFailed_GetEventFailed_EvtInfo_AutoCreatedDemEvent_ECUM_E_CONFIGURATION_DATA_INCONSISTENT422: start-on-event=GetEventFailed, operation=EvtInfo_AutoCreatedDemEvent_ECUM_E_CONFIGURATION_DATA_INCONSISTENT422.GetEventFailed
        OpEventGetEventFailed_GetEventFailed_EvtInfo_AutoCreatedDemEvent_ECUM_E_IMPROPER_CALLER422: start-on-event=GetEventFailed, operation=EvtInfo_AutoCreatedDemEvent_ECUM_E_IMPROPER_CALLER422.GetEventFailed
        OpEventGetEventFailed_GetEventFailed_EvtInfo_AutoCreatedDemEvent_ECUM_E_RAM_CHECK_FAILED422: start-on-event=GetEventFailed, operation=EvtInfo_AutoCreatedDemEvent_ECUM_E_RAM_CHECK_FAILED422.GetEventFailed
        OpEventGetEventFailed_GetEventFailed_EvtInfo_AutoCreatedDemEvent_ESH_Action_CancelNvMWriteAll_BswMReportFailToDemRef422: start-on-event=GetEventFailed, operation=EvtInfo_AutoCreatedDemEvent_ESH_Action_CancelNvMWriteAll_BswMReportFailToDemRef422.GetEventFailed
        OpEventGetEventFailed_GetEventFailed_EvtInfo_AutoCreatedDemEvent_ESH_Action_CancelWriteAllTimer_Start_BswMReportFailToDemRef422: start-on-event=GetEventFailed, operation=EvtInfo_AutoCreatedDemEvent_ESH_Action_CancelWriteAllTimer_Start_BswMReportFailToDemRef422.GetEventFailed
        OpEventGetEventFailed_GetEventFailed_EvtInfo_AutoCreatedDemEvent_ESH_Action_CancelWriteAllTimer_Stop_BswMReportFailToDemRef422: start-on-event=GetEventFailed, operation=EvtInfo_AutoCreatedDemEvent_ESH_Action_CancelWriteAllTimer_Stop_BswMReportFailToDemRef422.GetEventFailed
        OpEventGetEventFailed_GetEventFailed_EvtInfo_AutoCreatedDemEvent_ESH_Action_ComMAllow_CN_Backbone1J1939_0b1f4bae_BswMRe_04213a48: start-on-event=GetEventFailed, operation=EvtInfo_AutoCreatedDemEvent_ESH_Action_ComMAllow_CN_Backbone1J1939_0b1f4bae_BswMReportFailToDemRef422.GetEventFailed
        OpEventGetEventFailed_GetEventFailed_EvtInfo_AutoCreatedDemEvent_ESH_Action_ComMAllow_CN_Backbone1J1939_0b1f4bae_BswMRe_62089a90: start-on-event=GetEventFailed, operation=EvtInfo_AutoCreatedDemEvent_ESH_Action_ComMAllow_CN_Backbone1J1939_0b1f4bae_BswMReportFailToDemRef_1422.GetEventFailed
        OpEventGetEventFailed_GetEventFailed_EvtInfo_AutoCreatedDemEvent_ESH_Action_ComMAllow_CN_Backbone2_78967e2c_BswMReportF_dabcd89d: start-on-event=GetEventFailed, operation=EvtInfo_AutoCreatedDemEvent_ESH_Action_ComMAllow_CN_Backbone2_78967e2c_BswMReportFailToDemRef422.GetEventFailed
        OpEventGetEventFailed_GetEventFailed_EvtInfo_AutoCreatedDemEvent_ESH_Action_ComMAllow_CN_Backbone2_78967e2c_BswMReportF_d043f603: start-on-event=GetEventFailed, operation=EvtInfo_AutoCreatedDemEvent_ESH_Action_ComMAllow_CN_Backbone2_78967e2c_BswMReportFailToDemRef_1422.GetEventFailed
        OpEventGetEventFailed_GetEventFailed_EvtInfo_AutoCreatedDemEvent_ESH_Action_ComMAllow_CN_CabSubnet_9ea693f1_BswMReportF_76b6fe4b: start-on-event=GetEventFailed, operation=EvtInfo_AutoCreatedDemEvent_ESH_Action_ComMAllow_CN_CabSubnet_9ea693f1_BswMReportFailToDemRef422.GetEventFailed
        OpEventGetEventFailed_GetEventFailed_EvtInfo_AutoCreatedDemEvent_ESH_Action_ComMAllow_CN_CabSubnet_9ea693f1_BswMReportF_d52cbd6d: start-on-event=GetEventFailed, operation=EvtInfo_AutoCreatedDemEvent_ESH_Action_ComMAllow_CN_CabSubnet_9ea693f1_BswMReportFailToDemRef_1422.GetEventFailed
        OpEventGetEventFailed_GetEventFailed_EvtInfo_AutoCreatedDemEvent_ESH_Action_ComMAllow_CN_FMSNet_fce1aae5_BswMReportFail_5f29ce3c: start-on-event=GetEventFailed, operation=EvtInfo_AutoCreatedDemEvent_ESH_Action_ComMAllow_CN_FMSNet_fce1aae5_BswMReportFailToDemRef422.GetEventFailed
        OpEventGetEventFailed_GetEventFailed_EvtInfo_AutoCreatedDemEvent_ESH_Action_ComMAllow_CN_FMSNet_fce1aae5_BswMReportFail_938b4b6f: start-on-event=GetEventFailed, operation=EvtInfo_AutoCreatedDemEvent_ESH_Action_ComMAllow_CN_FMSNet_fce1aae5_BswMReportFailToDemRef_1422.GetEventFailed
        OpEventGetEventFailed_GetEventFailed_EvtInfo_AutoCreatedDemEvent_ESH_Action_ComMAllow_CN_LIN00_2cd9a7df_BswMReportFailT_eb4afd19: start-on-event=GetEventFailed, operation=EvtInfo_AutoCreatedDemEvent_ESH_Action_ComMAllow_CN_LIN00_2cd9a7df_BswMReportFailToDemRef422.GetEventFailed
        OpEventGetEventFailed_GetEventFailed_EvtInfo_AutoCreatedDemEvent_ESH_Action_ComMAllow_CN_LIN00_2cd9a7df_BswMReportFailT_c4a84efd: start-on-event=GetEventFailed, operation=EvtInfo_AutoCreatedDemEvent_ESH_Action_ComMAllow_CN_LIN00_2cd9a7df_BswMReportFailToDemRef_1422.GetEventFailed
        OpEventGetEventFailed_GetEventFailed_EvtInfo_AutoCreatedDemEvent_ESH_Action_ComMAllow_CN_LIN01_5bde9749_BswMReportFailT_d07a8c75: start-on-event=GetEventFailed, operation=EvtInfo_AutoCreatedDemEvent_ESH_Action_ComMAllow_CN_LIN01_5bde9749_BswMReportFailToDemRef422.GetEventFailed
        OpEventGetEventFailed_GetEventFailed_EvtInfo_AutoCreatedDemEvent_ESH_Action_ComMAllow_CN_LIN01_5bde9749_BswMReportFailT_2ae210cc: start-on-event=GetEventFailed, operation=EvtInfo_AutoCreatedDemEvent_ESH_Action_ComMAllow_CN_LIN01_5bde9749_BswMReportFailToDemRef_1422.GetEventFailed
        OpEventGetEventFailed_GetEventFailed_EvtInfo_AutoCreatedDemEvent_ESH_Action_ComMAllow_CN_LIN02_c2d7c6f3_BswMReportFailT_09194c44: start-on-event=GetEventFailed, operation=EvtInfo_AutoCreatedDemEvent_ESH_Action_ComMAllow_CN_LIN02_c2d7c6f3_BswMReportFailToDemRef422.GetEventFailed
        OpEventGetEventFailed_GetEventFailed_EvtInfo_AutoCreatedDemEvent_ESH_Action_ComMAllow_CN_LIN02_c2d7c6f3_BswMReportFailT_77db0cad: start-on-event=GetEventFailed, operation=EvtInfo_AutoCreatedDemEvent_ESH_Action_ComMAllow_CN_LIN02_c2d7c6f3_BswMReportFailToDemRef_1422.GetEventFailed
        OpEventGetEventFailed_GetEventFailed_EvtInfo_AutoCreatedDemEvent_ESH_Action_ComMAllow_CN_LIN03_b5d0f665_BswMReportFailT_171b0576: start-on-event=GetEventFailed, operation=EvtInfo_AutoCreatedDemEvent_ESH_Action_ComMAllow_CN_LIN03_b5d0f665_BswMReportFailToDemRef422.GetEventFailed
        OpEventGetEventFailed_GetEventFailed_EvtInfo_AutoCreatedDemEvent_ESH_Action_ComMAllow_CN_LIN03_b5d0f665_BswMReportFailT_95abbfea: start-on-event=GetEventFailed, operation=EvtInfo_AutoCreatedDemEvent_ESH_Action_ComMAllow_CN_LIN03_b5d0f665_BswMReportFailToDemRef_1422.GetEventFailed
        OpEventGetEventFailed_GetEventFailed_EvtInfo_AutoCreatedDemEvent_ESH_Action_ComMAllow_CN_LIN04_2bb463c6_BswMReportFailT_9c5fddee: start-on-event=GetEventFailed, operation=EvtInfo_AutoCreatedDemEvent_ESH_Action_ComMAllow_CN_LIN04_2bb463c6_BswMReportFailToDemRef422.GetEventFailed
        OpEventGetEventFailed_GetEventFailed_EvtInfo_AutoCreatedDemEvent_ESH_Action_ComMAllow_CN_LIN04_2bb463c6_BswMReportFailT_a43b6e5a: start-on-event=GetEventFailed, operation=EvtInfo_AutoCreatedDemEvent_ESH_Action_ComMAllow_CN_LIN04_2bb463c6_BswMReportFailToDemRef_1422.GetEventFailed
        OpEventGetEventFailed_GetEventFailed_EvtInfo_AutoCreatedDemEvent_ESH_Action_ComMAllow_CN_SecuritySubnet_e7a0ee54_BswMRe_bef61320: start-on-event=GetEventFailed, operation=EvtInfo_AutoCreatedDemEvent_ESH_Action_ComMAllow_CN_SecuritySubnet_e7a0ee54_BswMReportFailToDemRef422.GetEventFailed
        OpEventGetEventFailed_GetEventFailed_EvtInfo_AutoCreatedDemEvent_ESH_Action_ComMAllow_CN_SecuritySubnet_e7a0ee54_BswMRe_8d9e5984: start-on-event=GetEventFailed, operation=EvtInfo_AutoCreatedDemEvent_ESH_Action_ComMAllow_CN_SecuritySubnet_e7a0ee54_BswMReportFailToDemRef_1422.GetEventFailed
        OpEventGetEventFailed_GetEventFailed_EvtInfo_AutoCreatedDemEvent_ESH_Action_ComMCheckPendingRequests_BswMReportFailToDemRef422: start-on-event=GetEventFailed, operation=EvtInfo_AutoCreatedDemEvent_ESH_Action_ComMCheckPendingRequests_BswMReportFailToDemRef422.GetEventFailed
        OpEventGetEventFailed_GetEventFailed_EvtInfo_AutoCreatedDemEvent_ESH_Action_ComMCheckPendingRequests_BswMReportFailToDemRef_1422: start-on-event=GetEventFailed, operation=EvtInfo_AutoCreatedDemEvent_ESH_Action_ComMCheckPendingRequests_BswMReportFailToDemRef_1422.GetEventFailed
        OpEventGetEventFailed_GetEventFailed_EvtInfo_AutoCreatedDemEvent_ESH_Action_ComMCheckPendingRequests_BswMReportFailToDemRef_2422: start-on-event=GetEventFailed, operation=EvtInfo_AutoCreatedDemEvent_ESH_Action_ComMCheckPendingRequests_BswMReportFailToDemRef_2422.GetEventFailed
        OpEventGetEventFailed_GetEventFailed_EvtInfo_AutoCreatedDemEvent_ESH_Action_ComMDisallow_CN_Backbone1J1939_0b1f4bae_Bsw_5a50be8d: start-on-event=GetEventFailed, operation=EvtInfo_AutoCreatedDemEvent_ESH_Action_ComMDisallow_CN_Backbone1J1939_0b1f4bae_BswMReportFailToDemRef422.GetEventFailed
        OpEventGetEventFailed_GetEventFailed_EvtInfo_AutoCreatedDemEvent_ESH_Action_ComMDisallow_CN_Backbone2_78967e2c_BswMRepo_811f1291: start-on-event=GetEventFailed, operation=EvtInfo_AutoCreatedDemEvent_ESH_Action_ComMDisallow_CN_Backbone2_78967e2c_BswMReportFailToDemRef422.GetEventFailed
        OpEventGetEventFailed_GetEventFailed_EvtInfo_AutoCreatedDemEvent_ESH_Action_ComMDisallow_CN_CabSubnet_9ea693f1_BswMRepo_2d153447: start-on-event=GetEventFailed, operation=EvtInfo_AutoCreatedDemEvent_ESH_Action_ComMDisallow_CN_CabSubnet_9ea693f1_BswMReportFailToDemRef422.GetEventFailed
        OpEventGetEventFailed_GetEventFailed_EvtInfo_AutoCreatedDemEvent_ESH_Action_ComMDisallow_CN_FMSNet_fce1aae5_BswMReportF_d64b9821: start-on-event=GetEventFailed, operation=EvtInfo_AutoCreatedDemEvent_ESH_Action_ComMDisallow_CN_FMSNet_fce1aae5_BswMReportFailToDemRef422.GetEventFailed
        OpEventGetEventFailed_GetEventFailed_EvtInfo_AutoCreatedDemEvent_ESH_Action_ComMDisallow_CN_LIN00_2cd9a7df_BswMReportFa_5a370080: start-on-event=GetEventFailed, operation=EvtInfo_AutoCreatedDemEvent_ESH_Action_ComMDisallow_CN_LIN00_2cd9a7df_BswMReportFailToDemRef422.GetEventFailed
        OpEventGetEventFailed_GetEventFailed_EvtInfo_AutoCreatedDemEvent_ESH_Action_ComMDisallow_CN_LIN01_5bde9749_BswMReportFa_610771ec: start-on-event=GetEventFailed, operation=EvtInfo_AutoCreatedDemEvent_ESH_Action_ComMDisallow_CN_LIN01_5bde9749_BswMReportFailToDemRef422.GetEventFailed
        OpEventGetEventFailed_GetEventFailed_EvtInfo_AutoCreatedDemEvent_ESH_Action_ComMDisallow_CN_LIN02_c2d7c6f3_BswMReportFa_b864b1dd: start-on-event=GetEventFailed, operation=EvtInfo_AutoCreatedDemEvent_ESH_Action_ComMDisallow_CN_LIN02_c2d7c6f3_BswMReportFailToDemRef422.GetEventFailed
        OpEventGetEventFailed_GetEventFailed_EvtInfo_AutoCreatedDemEvent_ESH_Action_ComMDisallow_CN_LIN03_b5d0f665_BswMReportFa_a666f8ef: start-on-event=GetEventFailed, operation=EvtInfo_AutoCreatedDemEvent_ESH_Action_ComMDisallow_CN_LIN03_b5d0f665_BswMReportFailToDemRef422.GetEventFailed
        OpEventGetEventFailed_GetEventFailed_EvtInfo_AutoCreatedDemEvent_ESH_Action_ComMDisallow_CN_LIN04_2bb463c6_BswMReportFa_2d222077: start-on-event=GetEventFailed, operation=EvtInfo_AutoCreatedDemEvent_ESH_Action_ComMDisallow_CN_LIN04_2bb463c6_BswMReportFailToDemRef422.GetEventFailed
        OpEventGetEventFailed_GetEventFailed_EvtInfo_AutoCreatedDemEvent_ESH_Action_ComMDisallow_CN_SecuritySubnet_e7a0ee54_Bsw_e08797e5: start-on-event=GetEventFailed, operation=EvtInfo_AutoCreatedDemEvent_ESH_Action_ComMDisallow_CN_SecuritySubnet_e7a0ee54_BswMReportFailToDemRef422.GetEventFailed
        OpEventGetEventFailed_GetEventFailed_EvtInfo_AutoCreatedDemEvent_ESH_Action_DemInit_BswMReportFailToDemRef422: start-on-event=GetEventFailed, operation=EvtInfo_AutoCreatedDemEvent_ESH_Action_DemInit_BswMReportFailToDemRef422.GetEventFailed
        OpEventGetEventFailed_GetEventFailed_EvtInfo_AutoCreatedDemEvent_ESH_Action_DemInitialized_BswMReportFailToDemRef422: start-on-event=GetEventFailed, operation=EvtInfo_AutoCreatedDemEvent_ESH_Action_DemInitialized_BswMReportFailToDemRef422.GetEventFailed
        OpEventGetEventFailed_GetEventFailed_EvtInfo_AutoCreatedDemEvent_ESH_Action_DemNotInitialized_BswMReportFailToDemRef422: start-on-event=GetEventFailed, operation=EvtInfo_AutoCreatedDemEvent_ESH_Action_DemNotInitialized_BswMReportFailToDemRef422.GetEventFailed
        OpEventGetEventFailed_GetEventFailed_EvtInfo_AutoCreatedDemEvent_ESH_Action_DemShutdown_BswMReportFailToDemRef422: start-on-event=GetEventFailed, operation=EvtInfo_AutoCreatedDemEvent_ESH_Action_DemShutdown_BswMReportFailToDemRef422.GetEventFailed
        OpEventGetEventFailed_GetEventFailed_EvtInfo_AutoCreatedDemEvent_ESH_Action_ESH_PostRun_BswMReportFailToDemRef422: start-on-event=GetEventFailed, operation=EvtInfo_AutoCreatedDemEvent_ESH_Action_ESH_PostRun_BswMReportFailToDemRef422.GetEventFailed
        OpEventGetEventFailed_GetEventFailed_EvtInfo_AutoCreatedDemEvent_ESH_Action_ESH_PrepShutdown_BswMReportFailToDemRef422: start-on-event=GetEventFailed, operation=EvtInfo_AutoCreatedDemEvent_ESH_Action_ESH_PrepShutdown_BswMReportFailToDemRef422.GetEventFailed
        OpEventGetEventFailed_GetEventFailed_EvtInfo_AutoCreatedDemEvent_ESH_Action_ESH_PrepShutdown_BswMReportFailToDemRef_1422: start-on-event=GetEventFailed, operation=EvtInfo_AutoCreatedDemEvent_ESH_Action_ESH_PrepShutdown_BswMReportFailToDemRef_1422.GetEventFailed
        OpEventGetEventFailed_GetEventFailed_EvtInfo_AutoCreatedDemEvent_ESH_Action_ESH_Run_BswMReportFailToDemRef422: start-on-event=GetEventFailed, operation=EvtInfo_AutoCreatedDemEvent_ESH_Action_ESH_Run_BswMReportFailToDemRef422.GetEventFailed
        OpEventGetEventFailed_GetEventFailed_EvtInfo_AutoCreatedDemEvent_ESH_Action_ESH_Run_BswMReportFailToDemRef_1422: start-on-event=GetEventFailed, operation=EvtInfo_AutoCreatedDemEvent_ESH_Action_ESH_Run_BswMReportFailToDemRef_1422.GetEventFailed
        OpEventGetEventFailed_GetEventFailed_EvtInfo_AutoCreatedDemEvent_ESH_Action_ESH_WaitForNvm_BswMReportFailToDemRef422: start-on-event=GetEventFailed, operation=EvtInfo_AutoCreatedDemEvent_ESH_Action_ESH_WaitForNvm_BswMReportFailToDemRef422.GetEventFailed
        OpEventGetEventFailed_GetEventFailed_EvtInfo_AutoCreatedDemEvent_ESH_Action_ESH_Wakeup_BswMReportFailToDemRef422: start-on-event=GetEventFailed, operation=EvtInfo_AutoCreatedDemEvent_ESH_Action_ESH_Wakeup_BswMReportFailToDemRef422.GetEventFailed
        OpEventGetEventFailed_GetEventFailed_EvtInfo_AutoCreatedDemEvent_ESH_Action_ESH_Wakeup_BswMReportFailToDemRef_1422: start-on-event=GetEventFailed, operation=EvtInfo_AutoCreatedDemEvent_ESH_Action_ESH_Wakeup_BswMReportFailToDemRef_1422.GetEventFailed
        OpEventGetEventFailed_GetEventFailed_EvtInfo_AutoCreatedDemEvent_ESH_Action_EcuMClearValidatedWakeupEvents_BswMReportFa_56ad424a: start-on-event=GetEventFailed, operation=EvtInfo_AutoCreatedDemEvent_ESH_Action_EcuMClearValidatedWakeupEvents_BswMReportFailToDemRef422.GetEventFailed
        OpEventGetEventFailed_GetEventFailed_EvtInfo_AutoCreatedDemEvent_ESH_Action_EcuMGoToSelectedShutdownTarget_BswMReportFa_ad650d5f: start-on-event=GetEventFailed, operation=EvtInfo_AutoCreatedDemEvent_ESH_Action_EcuMGoToSelectedShutdownTarget_BswMReportFailToDemRef422.GetEventFailed
        OpEventGetEventFailed_GetEventFailed_EvtInfo_AutoCreatedDemEvent_ESH_Action_EnterExclusiveArea_BswMReportFailToDemRef422: start-on-event=GetEventFailed, operation=EvtInfo_AutoCreatedDemEvent_ESH_Action_EnterExclusiveArea_BswMReportFailToDemRef422.GetEventFailed
        OpEventGetEventFailed_GetEventFailed_EvtInfo_AutoCreatedDemEvent_ESH_Action_EnterExclusiveArea_BswMReportFailToDemRef_1422: start-on-event=GetEventFailed, operation=EvtInfo_AutoCreatedDemEvent_ESH_Action_EnterExclusiveArea_BswMReportFailToDemRef_1422.GetEventFailed
        OpEventGetEventFailed_GetEventFailed_EvtInfo_AutoCreatedDemEvent_ESH_Action_ExitExclusiveArea_BswMReportFailToDemRef422: start-on-event=GetEventFailed, operation=EvtInfo_AutoCreatedDemEvent_ESH_Action_ExitExclusiveArea_BswMReportFailToDemRef422.GetEventFailed
        OpEventGetEventFailed_GetEventFailed_EvtInfo_AutoCreatedDemEvent_ESH_Action_ExitExclusiveArea_BswMReportFailToDemRef_1422: start-on-event=GetEventFailed, operation=EvtInfo_AutoCreatedDemEvent_ESH_Action_ExitExclusiveArea_BswMReportFailToDemRef_1422.GetEventFailed
        OpEventGetEventFailed_GetEventFailed_EvtInfo_AutoCreatedDemEvent_ESH_Action_NvMWriteAll_BswMReportFailToDemRef422: start-on-event=GetEventFailed, operation=EvtInfo_AutoCreatedDemEvent_ESH_Action_NvMWriteAll_BswMReportFailToDemRef422.GetEventFailed
        OpEventGetEventFailed_GetEventFailed_EvtInfo_AutoCreatedDemEvent_ESH_Action_OnEnterPostRun_BswMReportFailToDemRef422: start-on-event=GetEventFailed, operation=EvtInfo_AutoCreatedDemEvent_ESH_Action_OnEnterPostRun_BswMReportFailToDemRef422.GetEventFailed
        OpEventGetEventFailed_GetEventFailed_EvtInfo_AutoCreatedDemEvent_ESH_Action_OnEnterPrepShutdown_BswMReportFailToDemRef422: start-on-event=GetEventFailed, operation=EvtInfo_AutoCreatedDemEvent_ESH_Action_OnEnterPrepShutdown_BswMReportFailToDemRef422.GetEventFailed
        OpEventGetEventFailed_GetEventFailed_EvtInfo_AutoCreatedDemEvent_ESH_Action_OnEnterPrepShutdown_BswMReportFailToDemRef_1422: start-on-event=GetEventFailed, operation=EvtInfo_AutoCreatedDemEvent_ESH_Action_OnEnterPrepShutdown_BswMReportFailToDemRef_1422.GetEventFailed
        OpEventGetEventFailed_GetEventFailed_EvtInfo_AutoCreatedDemEvent_ESH_Action_OnEnterRun_BswMReportFailToDemRef422: start-on-event=GetEventFailed, operation=EvtInfo_AutoCreatedDemEvent_ESH_Action_OnEnterRun_BswMReportFailToDemRef422.GetEventFailed
        OpEventGetEventFailed_GetEventFailed_EvtInfo_AutoCreatedDemEvent_ESH_Action_OnEnterRun_BswMReportFailToDemRef_1422: start-on-event=GetEventFailed, operation=EvtInfo_AutoCreatedDemEvent_ESH_Action_OnEnterRun_BswMReportFailToDemRef_1422.GetEventFailed
        OpEventGetEventFailed_GetEventFailed_EvtInfo_AutoCreatedDemEvent_ESH_Action_OnEnterShutdown_BswMReportFailToDemRef422: start-on-event=GetEventFailed, operation=EvtInfo_AutoCreatedDemEvent_ESH_Action_OnEnterShutdown_BswMReportFailToDemRef422.GetEventFailed
        OpEventGetEventFailed_GetEventFailed_EvtInfo_AutoCreatedDemEvent_ESH_Action_OnEnterWaitForNvm_BswMReportFailToDemRef422: start-on-event=GetEventFailed, operation=EvtInfo_AutoCreatedDemEvent_ESH_Action_OnEnterWaitForNvm_BswMReportFailToDemRef422.GetEventFailed
        OpEventGetEventFailed_GetEventFailed_EvtInfo_AutoCreatedDemEvent_ESH_Action_OnEnterWakeup_BswMReportFailToDemRef422: start-on-event=GetEventFailed, operation=EvtInfo_AutoCreatedDemEvent_ESH_Action_OnEnterWakeup_BswMReportFailToDemRef422.GetEventFailed
        OpEventGetEventFailed_GetEventFailed_EvtInfo_AutoCreatedDemEvent_ESH_Action_OnEnterWakeup_BswMReportFailToDemRef_1422: start-on-event=GetEventFailed, operation=EvtInfo_AutoCreatedDemEvent_ESH_Action_OnEnterWakeup_BswMReportFailToDemRef_1422.GetEventFailed
        OpEventGetEventFailed_GetEventFailed_EvtInfo_AutoCreatedDemEvent_ESH_Action_SelfRunRequestTimer_Start_BswMReportFailToDemRef422: start-on-event=GetEventFailed, operation=EvtInfo_AutoCreatedDemEvent_ESH_Action_SelfRunRequestTimer_Start_BswMReportFailToDemRef422.GetEventFailed
        OpEventGetEventFailed_GetEventFailed_EvtInfo_AutoCreatedDemEvent_ESH_Action_SelfRunRequestTimer_Start_BswMReportFailToD_4f6740a1: start-on-event=GetEventFailed, operation=EvtInfo_AutoCreatedDemEvent_ESH_Action_SelfRunRequestTimer_Start_BswMReportFailToDemRef_1422.GetEventFailed
        OpEventGetEventFailed_GetEventFailed_EvtInfo_AutoCreatedDemEvent_ESH_Action_SwitchPostRun_BswMReportFailToDemRef422: start-on-event=GetEventFailed, operation=EvtInfo_AutoCreatedDemEvent_ESH_Action_SwitchPostRun_BswMReportFailToDemRef422.GetEventFailed
        OpEventGetEventFailed_GetEventFailed_EvtInfo_AutoCreatedDemEvent_ESH_Action_SwitchRun_BswMReportFailToDemRef422: start-on-event=GetEventFailed, operation=EvtInfo_AutoCreatedDemEvent_ESH_Action_SwitchRun_BswMReportFailToDemRef422.GetEventFailed
        OpEventGetEventFailed_GetEventFailed_EvtInfo_AutoCreatedDemEvent_ESH_Action_SwitchRun_BswMReportFailToDemRef_1422: start-on-event=GetEventFailed, operation=EvtInfo_AutoCreatedDemEvent_ESH_Action_SwitchRun_BswMReportFailToDemRef_1422.GetEventFailed
        OpEventGetEventFailed_GetEventFailed_EvtInfo_AutoCreatedDemEvent_ESH_Action_SwitchShutdown_BswMReportFailToDemRef422: start-on-event=GetEventFailed, operation=EvtInfo_AutoCreatedDemEvent_ESH_Action_SwitchShutdown_BswMReportFailToDemRef422.GetEventFailed
        OpEventGetEventFailed_GetEventFailed_EvtInfo_AutoCreatedDemEvent_ESH_Action_SwitchShutdown_BswMReportFailToDemRef_1422: start-on-event=GetEventFailed, operation=EvtInfo_AutoCreatedDemEvent_ESH_Action_SwitchShutdown_BswMReportFailToDemRef_1422.GetEventFailed
        OpEventGetEventFailed_GetEventFailed_EvtInfo_AutoCreatedDemEvent_ESH_Action_SwitchWakeup_BswMReportFailToDemRef422: start-on-event=GetEventFailed, operation=EvtInfo_AutoCreatedDemEvent_ESH_Action_SwitchWakeup_BswMReportFailToDemRef422.GetEventFailed
        OpEventGetEventFailed_GetEventFailed_EvtInfo_AutoCreatedDemEvent_ESH_Action_SwitchWakeup_BswMReportFailToDemRef_1422: start-on-event=GetEventFailed, operation=EvtInfo_AutoCreatedDemEvent_ESH_Action_SwitchWakeup_BswMReportFailToDemRef_1422.GetEventFailed
        OpEventGetEventFailed_GetEventFailed_EvtInfo_AutoCreatedDemEvent_ESH_Action_WriteAllTimer_Start_BswMReportFailToDemRef422: start-on-event=GetEventFailed, operation=EvtInfo_AutoCreatedDemEvent_ESH_Action_WriteAllTimer_Start_BswMReportFailToDemRef422.GetEventFailed
        OpEventGetEventFailed_GetEventFailed_EvtInfo_AutoCreatedDemEvent_ESH_Action_WriteAllTimer_Stop_BswMReportFailToDemRef422: start-on-event=GetEventFailed, operation=EvtInfo_AutoCreatedDemEvent_ESH_Action_WriteAllTimer_Stop_BswMReportFailToDemRef422.GetEventFailed
        OpEventGetEventFailed_GetEventFailed_EvtInfo_AutoCreatedDemEvent_ESH_Action_WriteAllTimer_Stop_BswMReportFailToDemRef_1422: start-on-event=GetEventFailed, operation=EvtInfo_AutoCreatedDemEvent_ESH_Action_WriteAllTimer_Stop_BswMReportFailToDemRef_1422.GetEventFailed
        OpEventGetEventFailed_GetEventFailed_EvtInfo_AutoCreatedDemEvent_ESH_DemInit_BswMReportFailToDemRef422: start-on-event=GetEventFailed, operation=EvtInfo_AutoCreatedDemEvent_ESH_DemInit_BswMReportFailToDemRef422.GetEventFailed
        OpEventGetEventFailed_GetEventFailed_EvtInfo_AutoCreatedDemEvent_ESH_PostRunNested_BswMReportFailToDemRef422: start-on-event=GetEventFailed, operation=EvtInfo_AutoCreatedDemEvent_ESH_PostRunNested_BswMReportFailToDemRef422.GetEventFailed
        OpEventGetEventFailed_GetEventFailed_EvtInfo_AutoCreatedDemEvent_ESH_PostRunToPrepNested_BswMReportFailToDemRef422: start-on-event=GetEventFailed, operation=EvtInfo_AutoCreatedDemEvent_ESH_PostRunToPrepNested_BswMReportFailToDemRef422.GetEventFailed
        OpEventGetEventFailed_GetEventFailed_EvtInfo_AutoCreatedDemEvent_ESH_RunToPostRunNested_BswMReportFailToDemRef422: start-on-event=GetEventFailed, operation=EvtInfo_AutoCreatedDemEvent_ESH_RunToPostRunNested_BswMReportFailToDemRef422.GetEventFailed
        OpEventGetEventFailed_GetEventFailed_EvtInfo_AutoCreatedDemEvent_FLS_E_COMPARE_FAILED422: start-on-event=GetEventFailed, operation=EvtInfo_AutoCreatedDemEvent_FLS_E_COMPARE_FAILED422.GetEventFailed
        OpEventGetEventFailed_GetEventFailed_EvtInfo_AutoCreatedDemEvent_FLS_E_ERASE_FAILED422: start-on-event=GetEventFailed, operation=EvtInfo_AutoCreatedDemEvent_FLS_E_ERASE_FAILED422.GetEventFailed
        OpEventGetEventFailed_GetEventFailed_EvtInfo_AutoCreatedDemEvent_FLS_E_READ_FAILED422: start-on-event=GetEventFailed, operation=EvtInfo_AutoCreatedDemEvent_FLS_E_READ_FAILED422.GetEventFailed
        OpEventGetEventFailed_GetEventFailed_EvtInfo_AutoCreatedDemEvent_FLS_E_UNEXPECTED_FLASH_ID422: start-on-event=GetEventFailed, operation=EvtInfo_AutoCreatedDemEvent_FLS_E_UNEXPECTED_FLASH_ID422.GetEventFailed
        OpEventGetEventFailed_GetEventFailed_EvtInfo_AutoCreatedDemEvent_FLS_E_WRITE_FAILED422: start-on-event=GetEventFailed, operation=EvtInfo_AutoCreatedDemEvent_FLS_E_WRITE_FAILED422.GetEventFailed
        OpEventGetEventFailed_GetEventFailed_EvtInfo_AutoCreatedDemEvent_GPT_E_TIMEOUT422: start-on-event=GetEventFailed, operation=EvtInfo_AutoCreatedDemEvent_GPT_E_TIMEOUT422.GetEventFailed
        OpEventGetEventFailed_GetEventFailed_EvtInfo_AutoCreatedDemEvent_INIT_Action_BrsHw_EnableHwAccess_BswMReportFailToDemRef422: start-on-event=GetEventFailed, operation=EvtInfo_AutoCreatedDemEvent_INIT_Action_BrsHw_EnableHwAccess_BswMReportFailToDemRef422.GetEventFailed
        OpEventGetEventFailed_GetEventFailed_EvtInfo_AutoCreatedDemEvent_INIT_Action_CanIf_Init_BswMReportFailToDemRef422: start-on-event=GetEventFailed, operation=EvtInfo_AutoCreatedDemEvent_INIT_Action_CanIf_Init_BswMReportFailToDemRef422.GetEventFailed
        OpEventGetEventFailed_GetEventFailed_EvtInfo_AutoCreatedDemEvent_INIT_Action_CanNm_Init_BswMReportFailToDemRef422: start-on-event=GetEventFailed, operation=EvtInfo_AutoCreatedDemEvent_INIT_Action_CanNm_Init_BswMReportFailToDemRef422.GetEventFailed
        OpEventGetEventFailed_GetEventFailed_EvtInfo_AutoCreatedDemEvent_INIT_Action_CanSM_Init_BswMReportFailToDemRef422: start-on-event=GetEventFailed, operation=EvtInfo_AutoCreatedDemEvent_INIT_Action_CanSM_Init_BswMReportFailToDemRef422.GetEventFailed
        OpEventGetEventFailed_GetEventFailed_EvtInfo_AutoCreatedDemEvent_INIT_Action_CanTp_Init_BswMReportFailToDemRef422: start-on-event=GetEventFailed, operation=EvtInfo_AutoCreatedDemEvent_INIT_Action_CanTp_Init_BswMReportFailToDemRef422.GetEventFailed
        OpEventGetEventFailed_GetEventFailed_EvtInfo_AutoCreatedDemEvent_INIT_Action_Can_Init_BswMReportFailToDemRef422: start-on-event=GetEventFailed, operation=EvtInfo_AutoCreatedDemEvent_INIT_Action_Can_Init_BswMReportFailToDemRef422.GetEventFailed
        OpEventGetEventFailed_GetEventFailed_EvtInfo_AutoCreatedDemEvent_INIT_Action_ComM_Init_BswMReportFailToDemRef422: start-on-event=GetEventFailed, operation=EvtInfo_AutoCreatedDemEvent_INIT_Action_ComM_Init_BswMReportFailToDemRef422.GetEventFailed
        OpEventGetEventFailed_GetEventFailed_EvtInfo_AutoCreatedDemEvent_INIT_Action_Com_Init_BswMReportFailToDemRef422: start-on-event=GetEventFailed, operation=EvtInfo_AutoCreatedDemEvent_INIT_Action_Com_Init_BswMReportFailToDemRef422.GetEventFailed
        OpEventGetEventFailed_GetEventFailed_EvtInfo_AutoCreatedDemEvent_INIT_Action_Dcm_Init_BswMReportFailToDemRef422: start-on-event=GetEventFailed, operation=EvtInfo_AutoCreatedDemEvent_INIT_Action_Dcm_Init_BswMReportFailToDemRef422.GetEventFailed
        OpEventGetEventFailed_GetEventFailed_EvtInfo_AutoCreatedDemEvent_INIT_Action_Dem_Init_BswMReportFailToDemRef422: start-on-event=GetEventFailed, operation=EvtInfo_AutoCreatedDemEvent_INIT_Action_Dem_Init_BswMReportFailToDemRef422.GetEventFailed
        OpEventGetEventFailed_GetEventFailed_EvtInfo_AutoCreatedDemEvent_INIT_Action_EnableInterrupts_BswMReportFailToDemRef422: start-on-event=GetEventFailed, operation=EvtInfo_AutoCreatedDemEvent_INIT_Action_EnableInterrupts_BswMReportFailToDemRef422.GetEventFailed
        OpEventGetEventFailed_GetEventFailed_EvtInfo_AutoCreatedDemEvent_INIT_Action_Fee_Init_BswMReportFailToDemRef422: start-on-event=GetEventFailed, operation=EvtInfo_AutoCreatedDemEvent_INIT_Action_Fee_Init_BswMReportFailToDemRef422.GetEventFailed
        OpEventGetEventFailed_GetEventFailed_EvtInfo_AutoCreatedDemEvent_INIT_Action_Issm_Init_BswMReportFailToDemRef422: start-on-event=GetEventFailed, operation=EvtInfo_AutoCreatedDemEvent_INIT_Action_Issm_Init_BswMReportFailToDemRef422.GetEventFailed
        OpEventGetEventFailed_GetEventFailed_EvtInfo_AutoCreatedDemEvent_INIT_Action_J1939Nm_Init_BswMReportFailToDemRef422: start-on-event=GetEventFailed, operation=EvtInfo_AutoCreatedDemEvent_INIT_Action_J1939Nm_Init_BswMReportFailToDemRef422.GetEventFailed
        OpEventGetEventFailed_GetEventFailed_EvtInfo_AutoCreatedDemEvent_INIT_Action_J1939Rm_Init_BswMReportFailToDemRef422: start-on-event=GetEventFailed, operation=EvtInfo_AutoCreatedDemEvent_INIT_Action_J1939Rm_Init_BswMReportFailToDemRef422.GetEventFailed
        OpEventGetEventFailed_GetEventFailed_EvtInfo_AutoCreatedDemEvent_INIT_Action_J1939Tp_Init_BswMReportFailToDemRef422: start-on-event=GetEventFailed, operation=EvtInfo_AutoCreatedDemEvent_INIT_Action_J1939Tp_Init_BswMReportFailToDemRef422.GetEventFailed
        OpEventGetEventFailed_GetEventFailed_EvtInfo_AutoCreatedDemEvent_INIT_Action_LinIf_Init_BswMReportFailToDemRef422: start-on-event=GetEventFailed, operation=EvtInfo_AutoCreatedDemEvent_INIT_Action_LinIf_Init_BswMReportFailToDemRef422.GetEventFailed
        OpEventGetEventFailed_GetEventFailed_EvtInfo_AutoCreatedDemEvent_INIT_Action_LinSM_Init_BswMReportFailToDemRef422: start-on-event=GetEventFailed, operation=EvtInfo_AutoCreatedDemEvent_INIT_Action_LinSM_Init_BswMReportFailToDemRef422.GetEventFailed
        OpEventGetEventFailed_GetEventFailed_EvtInfo_AutoCreatedDemEvent_INIT_Action_LinTp_Init_BswMReportFailToDemRef422: start-on-event=GetEventFailed, operation=EvtInfo_AutoCreatedDemEvent_INIT_Action_LinTp_Init_BswMReportFailToDemRef422.GetEventFailed
        OpEventGetEventFailed_GetEventFailed_EvtInfo_AutoCreatedDemEvent_INIT_Action_Lin_Init_BswMReportFailToDemRef422: start-on-event=GetEventFailed, operation=EvtInfo_AutoCreatedDemEvent_INIT_Action_Lin_Init_BswMReportFailToDemRef422.GetEventFailed
        OpEventGetEventFailed_GetEventFailed_EvtInfo_AutoCreatedDemEvent_INIT_Action_Nm_Init_BswMReportFailToDemRef422: start-on-event=GetEventFailed, operation=EvtInfo_AutoCreatedDemEvent_INIT_Action_Nm_Init_BswMReportFailToDemRef422.GetEventFailed
        OpEventGetEventFailed_GetEventFailed_EvtInfo_AutoCreatedDemEvent_INIT_Action_NvMReadAll_BswMReportFailToDemRef422: start-on-event=GetEventFailed, operation=EvtInfo_AutoCreatedDemEvent_INIT_Action_NvMReadAll_BswMReportFailToDemRef422.GetEventFailed
        OpEventGetEventFailed_GetEventFailed_EvtInfo_AutoCreatedDemEvent_INIT_Action_NvM_Init_BswMReportFailToDemRef422: start-on-event=GetEventFailed, operation=EvtInfo_AutoCreatedDemEvent_INIT_Action_NvM_Init_BswMReportFailToDemRef422.GetEventFailed
        OpEventGetEventFailed_GetEventFailed_EvtInfo_AutoCreatedDemEvent_INIT_Action_PduR_Init_BswMReportFailToDemRef422: start-on-event=GetEventFailed, operation=EvtInfo_AutoCreatedDemEvent_INIT_Action_PduR_Init_BswMReportFailToDemRef422.GetEventFailed
        OpEventGetEventFailed_GetEventFailed_EvtInfo_AutoCreatedDemEvent_INIT_Action_RteStart_BswMReportFailToDemRef422: start-on-event=GetEventFailed, operation=EvtInfo_AutoCreatedDemEvent_INIT_Action_RteStart_BswMReportFailToDemRef422.GetEventFailed
        OpEventGetEventFailed_GetEventFailed_EvtInfo_AutoCreatedDemEvent_J1939NM_E_ADDRESS_LOST422: start-on-event=GetEventFailed, operation=EvtInfo_AutoCreatedDemEvent_J1939NM_E_ADDRESS_LOST422.GetEventFailed
        OpEventGetEventFailed_GetEventFailed_EvtInfo_AutoCreatedDemEvent_J1939TpConfiguration_J1939TP_E_COMMUNICATION422: start-on-event=GetEventFailed, operation=EvtInfo_AutoCreatedDemEvent_J1939TpConfiguration_J1939TP_E_COMMUNICATION422.GetEventFailed
        OpEventGetEventFailed_GetEventFailed_EvtInfo_AutoCreatedDemEvent_LIN_E_TIMEOUT422: start-on-event=GetEventFailed, operation=EvtInfo_AutoCreatedDemEvent_LIN_E_TIMEOUT422.GetEventFailed
        OpEventGetEventFailed_GetEventFailed_EvtInfo_AutoCreatedDemEvent_MCL_E_DMA_BUS422: start-on-event=GetEventFailed, operation=EvtInfo_AutoCreatedDemEvent_MCL_E_DMA_BUS422.GetEventFailed
        OpEventGetEventFailed_GetEventFailed_EvtInfo_AutoCreatedDemEvent_MCL_E_DMA_DESCRIPTOR422: start-on-event=GetEventFailed, operation=EvtInfo_AutoCreatedDemEvent_MCL_E_DMA_DESCRIPTOR422.GetEventFailed
        OpEventGetEventFailed_GetEventFailed_EvtInfo_AutoCreatedDemEvent_MCL_E_DMA_ECC422: start-on-event=GetEventFailed, operation=EvtInfo_AutoCreatedDemEvent_MCL_E_DMA_ECC422.GetEventFailed
        OpEventGetEventFailed_GetEventFailed_EvtInfo_AutoCreatedDemEvent_MCL_E_DMA_INCONSISTENCY422: start-on-event=GetEventFailed, operation=EvtInfo_AutoCreatedDemEvent_MCL_E_DMA_INCONSISTENCY422.GetEventFailed
        OpEventGetEventFailed_GetEventFailed_EvtInfo_AutoCreatedDemEvent_MCL_E_DMA_PRIORITY422: start-on-event=GetEventFailed, operation=EvtInfo_AutoCreatedDemEvent_MCL_E_DMA_PRIORITY422.GetEventFailed
        OpEventGetEventFailed_GetEventFailed_EvtInfo_AutoCreatedDemEvent_MCL_E_DMA_UNRECOGNIZED422: start-on-event=GetEventFailed, operation=EvtInfo_AutoCreatedDemEvent_MCL_E_DMA_UNRECOGNIZED422.GetEventFailed
        OpEventGetEventFailed_GetEventFailed_EvtInfo_AutoCreatedDemEvent_MCU_E_CLOCK_FAILURE422: start-on-event=GetEventFailed, operation=EvtInfo_AutoCreatedDemEvent_MCU_E_CLOCK_FAILURE422.GetEventFailed
        OpEventGetEventFailed_GetEventFailed_EvtInfo_AutoCreatedDemEvent_MCU_E_INVALIDMODE_CONFIG422: start-on-event=GetEventFailed, operation=EvtInfo_AutoCreatedDemEvent_MCU_E_INVALIDMODE_CONFIG422.GetEventFailed
        OpEventGetEventFailed_GetEventFailed_EvtInfo_AutoCreatedDemEvent_MCU_E_SSCM_CER_FAILURE422: start-on-event=GetEventFailed, operation=EvtInfo_AutoCreatedDemEvent_MCU_E_SSCM_CER_FAILURE422.GetEventFailed
        OpEventGetEventFailed_GetEventFailed_EvtInfo_AutoCreatedDemEvent_MCU_E_TIMEOUT_FAILURE422: start-on-event=GetEventFailed, operation=EvtInfo_AutoCreatedDemEvent_MCU_E_TIMEOUT_FAILURE422.GetEventFailed
        OpEventGetEventFailed_GetEventFailed_EvtInfo_AutoCreatedDemEvent_NVM_E_INTEGRITY_FAILED422: start-on-event=GetEventFailed, operation=EvtInfo_AutoCreatedDemEvent_NVM_E_INTEGRITY_FAILED422.GetEventFailed
        OpEventGetEventFailed_GetEventFailed_EvtInfo_AutoCreatedDemEvent_NVM_E_LOSS_OF_REDUNDANCY422: start-on-event=GetEventFailed, operation=EvtInfo_AutoCreatedDemEvent_NVM_E_LOSS_OF_REDUNDANCY422.GetEventFailed
        OpEventGetEventFailed_GetEventFailed_EvtInfo_AutoCreatedDemEvent_NVM_E_QUEUE_OVERFLOW422: start-on-event=GetEventFailed, operation=EvtInfo_AutoCreatedDemEvent_NVM_E_QUEUE_OVERFLOW422.GetEventFailed
        OpEventGetEventFailed_GetEventFailed_EvtInfo_AutoCreatedDemEvent_NVM_E_REQ_FAILED422: start-on-event=GetEventFailed, operation=EvtInfo_AutoCreatedDemEvent_NVM_E_REQ_FAILED422.GetEventFailed
        OpEventGetEventFailed_GetEventFailed_EvtInfo_AutoCreatedDemEvent_NVM_E_VERIFY_FAILED422: start-on-event=GetEventFailed, operation=EvtInfo_AutoCreatedDemEvent_NVM_E_VERIFY_FAILED422.GetEventFailed
        OpEventGetEventFailed_GetEventFailed_EvtInfo_AutoCreatedDemEvent_NVM_E_WRITE_PROTECTED422: start-on-event=GetEventFailed, operation=EvtInfo_AutoCreatedDemEvent_NVM_E_WRITE_PROTECTED422.GetEventFailed
        OpEventGetEventFailed_GetEventFailed_EvtInfo_AutoCreatedDemEvent_NVM_E_WRONG_BLOCK_ID422: start-on-event=GetEventFailed, operation=EvtInfo_AutoCreatedDemEvent_NVM_E_WRONG_BLOCK_ID422.GetEventFailed
        OpEventGetEventFailed_GetEventFailed_EvtInfo_AutoCreatedDemEvent_SPI_E_HARDWARE_ERROR422: start-on-event=GetEventFailed, operation=EvtInfo_AutoCreatedDemEvent_SPI_E_HARDWARE_ERROR422.GetEventFailed
        OpEventGetEventFailed_GetEventFailed_EvtInfo_AutoCreatedDemEvent_SpiDriver_SPI_E_HARDWARE_ERROR422: start-on-event=GetEventFailed, operation=EvtInfo_AutoCreatedDemEvent_SpiDriver_SPI_E_HARDWARE_ERROR422.GetEventFailed
        OpEventGetEventFailed_GetEventFailed_EvtInfo_AutoCreatedDemEvent_WDG_E_CORRUPT_CONFIG422: start-on-event=GetEventFailed, operation=EvtInfo_AutoCreatedDemEvent_WDG_E_CORRUPT_CONFIG422.GetEventFailed
        OpEventGetEventFailed_GetEventFailed_EvtInfo_AutoCreatedDemEvent_WDG_E_DISABLE_REJECTED422: start-on-event=GetEventFailed, operation=EvtInfo_AutoCreatedDemEvent_WDG_E_DISABLE_REJECTED422.GetEventFailed
        OpEventGetEventFailed_GetEventFailed_EvtInfo_AutoCreatedDemEvent_WDG_E_FORBIDDEN_INVOCATION422: start-on-event=GetEventFailed, operation=EvtInfo_AutoCreatedDemEvent_WDG_E_FORBIDDEN_INVOCATION422.GetEventFailed
        OpEventGetEventFailed_GetEventFailed_EvtInfo_AutoCreatedDemEvent_WDG_E_INVALID_CALL422: start-on-event=GetEventFailed, operation=EvtInfo_AutoCreatedDemEvent_WDG_E_INVALID_CALL422.GetEventFailed
        OpEventGetEventFailed_GetEventFailed_EvtInfo_AutoCreatedDemEvent_WDG_E_INVALID_PARAMETER422: start-on-event=GetEventFailed, operation=EvtInfo_AutoCreatedDemEvent_WDG_E_INVALID_PARAMETER422.GetEventFailed
        OpEventGetEventFailed_GetEventFailed_EvtInfo_AutoCreatedDemEvent_WDG_E_MODE_FAILED422: start-on-event=GetEventFailed, operation=EvtInfo_AutoCreatedDemEvent_WDG_E_MODE_FAILED422.GetEventFailed
        OpEventGetEventFailed_GetEventFailed_EvtInfo_AutoCreatedDemEvent_WDG_E_UNLOCKED422: start-on-event=GetEventFailed, operation=EvtInfo_AutoCreatedDemEvent_WDG_E_UNLOCKED422.GetEventFailed
        OpEventGetEventTested_GetEventTested_EvtInfo_AutoCreatedDemEvent_ADC_E_TIMEOUT422: start-on-event=GetEventTested, operation=EvtInfo_AutoCreatedDemEvent_ADC_E_TIMEOUT422.GetEventTested
        OpEventGetEventTested_GetEventTested_EvtInfo_AutoCreatedDemEvent_CC_DisableDM_CIOM_oBackbone1J1939_Rx_BC_405bc776_BswMR_4896bd50: start-on-event=GetEventTested, operation=EvtInfo_AutoCreatedDemEvent_CC_DisableDM_CIOM_oBackbone1J1939_Rx_BC_405bc776_BswMReportFailToDemRef422.GetEventTested
        OpEventGetEventTested_GetEventTested_EvtInfo_AutoCreatedDemEvent_CC_DisableDM_CIOM_oBackbone2_Rx_4e624434_BswMReportFai_e7de1028: start-on-event=GetEventTested, operation=EvtInfo_AutoCreatedDemEvent_CC_DisableDM_CIOM_oBackbone2_Rx_4e624434_BswMReportFailToDemRef422.GetEventTested
        OpEventGetEventTested_GetEventTested_EvtInfo_AutoCreatedDemEvent_CC_DisableDM_CIOM_oCabSubnet_Rx_063a5fbc_BswMReportFai_9a9c5ba2: start-on-event=GetEventTested, operation=EvtInfo_AutoCreatedDemEvent_CC_DisableDM_CIOM_oCabSubnet_Rx_063a5fbc_BswMReportFailToDemRef422.GetEventTested
        OpEventGetEventTested_GetEventTested_EvtInfo_AutoCreatedDemEvent_CC_DisableDM_CIOM_oFMSNet_Rx_BC_dd2c1510_BswMReportFai_858c9a24: start-on-event=GetEventTested, operation=EvtInfo_AutoCreatedDemEvent_CC_DisableDM_CIOM_oFMSNet_Rx_BC_dd2c1510_BswMReportFailToDemRef422.GetEventTested
        OpEventGetEventTested_GetEventTested_EvtInfo_AutoCreatedDemEvent_CC_DisableDM_CIOM_oSecuritySubnet_Rx_3a3c1dbc_BswMRepo_837e3f48: start-on-event=GetEventTested, operation=EvtInfo_AutoCreatedDemEvent_CC_DisableDM_CIOM_oSecuritySubnet_Rx_3a3c1dbc_BswMReportFailToDemRef422.GetEventTested
        OpEventGetEventTested_GetEventTested_EvtInfo_AutoCreatedDemEvent_CC_DisablePDUGroup_CIOM_oBackbone1J1939_Rx_BC_405bc776_88b23f99: start-on-event=GetEventTested, operation=EvtInfo_AutoCreatedDemEvent_CC_DisablePDUGroup_CIOM_oBackbone1J1939_Rx_BC_405bc776_BswMReportFailToDemRef422.GetEventTested
        OpEventGetEventTested_GetEventTested_EvtInfo_AutoCreatedDemEvent_CC_DisablePDUGroup_CIOM_oBackbone1J1939_Tx_0x31_BC_378_8a758a38: start-on-event=GetEventTested, operation=EvtInfo_AutoCreatedDemEvent_CC_DisablePDUGroup_CIOM_oBackbone1J1939_Tx_0x31_BC_3782f500_BswMReportFailToDemRef422.GetEventTested
        OpEventGetEventTested_GetEventTested_EvtInfo_AutoCreatedDemEvent_CC_DisablePDUGroup_CIOM_oBackbone2_Rx_4e624434_BswMRep_f10a00ca: start-on-event=GetEventTested, operation=EvtInfo_AutoCreatedDemEvent_CC_DisablePDUGroup_CIOM_oBackbone2_Rx_4e624434_BswMReportFailToDemRef422.GetEventTested
        OpEventGetEventTested_GetEventTested_EvtInfo_AutoCreatedDemEvent_CC_DisablePDUGroup_CIOM_oBackbone2_Tx_1838e3b2_BswMRep_fddca6e4: start-on-event=GetEventTested, operation=EvtInfo_AutoCreatedDemEvent_CC_DisablePDUGroup_CIOM_oBackbone2_Tx_1838e3b2_BswMReportFailToDemRef422.GetEventTested
        OpEventGetEventTested_GetEventTested_EvtInfo_AutoCreatedDemEvent_CC_DisablePDUGroup_CIOM_oCabSubnet_Rx_063a5fbc_BswMRep_8c484b40: start-on-event=GetEventTested, operation=EvtInfo_AutoCreatedDemEvent_CC_DisablePDUGroup_CIOM_oCabSubnet_Rx_063a5fbc_BswMReportFailToDemRef422.GetEventTested
        OpEventGetEventTested_GetEventTested_EvtInfo_AutoCreatedDemEvent_CC_DisablePDUGroup_CIOM_oCabSubnet_Tx_5060f83a_BswMRep_1e3a1472: start-on-event=GetEventTested, operation=EvtInfo_AutoCreatedDemEvent_CC_DisablePDUGroup_CIOM_oCabSubnet_Tx_5060f83a_BswMReportFailToDemRef422.GetEventTested
        OpEventGetEventTested_GetEventTested_EvtInfo_AutoCreatedDemEvent_CC_DisablePDUGroup_CIOM_oFMSNet_Rx_BC_dd2c1510_BswMRep_93588ac6: start-on-event=GetEventTested, operation=EvtInfo_AutoCreatedDemEvent_CC_DisablePDUGroup_CIOM_oFMSNet_Rx_BC_dd2c1510_BswMReportFailToDemRef422.GetEventTested
        OpEventGetEventTested_GetEventTested_EvtInfo_AutoCreatedDemEvent_CC_DisablePDUGroup_CIOM_oFMSNet_Tx_0x31_BC_38fc8c7d_Bs_a7a685ff: start-on-event=GetEventTested, operation=EvtInfo_AutoCreatedDemEvent_CC_DisablePDUGroup_CIOM_oFMSNet_Tx_0x31_BC_38fc8c7d_BswMReportFailToDemRef422.GetEventTested
        OpEventGetEventTested_GetEventTested_EvtInfo_AutoCreatedDemEvent_CC_DisablePDUGroup_CIOM_oLIN00_Rx_dd181faa_BswMReportF_87106424: start-on-event=GetEventTested, operation=EvtInfo_AutoCreatedDemEvent_CC_DisablePDUGroup_CIOM_oLIN00_Rx_dd181faa_BswMReportFailToDemRef422.GetEventTested
        OpEventGetEventTested_GetEventTested_EvtInfo_AutoCreatedDemEvent_CC_DisablePDUGroup_CIOM_oLIN00_Tx_8b42b82c_BswMReportF_fbf7aaed: start-on-event=GetEventTested, operation=EvtInfo_AutoCreatedDemEvent_CC_DisablePDUGroup_CIOM_oLIN00_Tx_8b42b82c_BswMReportFailToDemRef422.GetEventTested
        OpEventGetEventTested_GetEventTested_EvtInfo_AutoCreatedDemEvent_CC_DisablePDUGroup_CIOM_oLIN01_Rx_65a478cf_BswMReportF_bea04321: start-on-event=GetEventTested, operation=EvtInfo_AutoCreatedDemEvent_CC_DisablePDUGroup_CIOM_oLIN01_Rx_65a478cf_BswMReportFailToDemRef422.GetEventTested
        OpEventGetEventTested_GetEventTested_EvtInfo_AutoCreatedDemEvent_CC_DisablePDUGroup_CIOM_oLIN01_Tx_33fedf49_BswMReportF_2033b986: start-on-event=GetEventTested, operation=EvtInfo_AutoCreatedDemEvent_CC_DisablePDUGroup_CIOM_oLIN01_Tx_33fedf49_BswMReportFailToDemRef422.GetEventTested
        OpEventGetEventTested_GetEventTested_EvtInfo_AutoCreatedDemEvent_CC_DisablePDUGroup_CIOM_oLIN02_Rx_7711d721_BswMReportF_50b9bfd5: start-on-event=GetEventTested, operation=EvtInfo_AutoCreatedDemEvent_CC_DisablePDUGroup_CIOM_oLIN02_Rx_7711d721_BswMReportFailToDemRef422.GetEventTested
        OpEventGetEventTested_GetEventTested_EvtInfo_AutoCreatedDemEvent_CC_DisablePDUGroup_CIOM_oLIN02_Tx_214b70a7_BswMReportF_808c0f6e: start-on-event=GetEventTested, operation=EvtInfo_AutoCreatedDemEvent_CC_DisablePDUGroup_CIOM_oLIN02_Tx_214b70a7_BswMReportFailToDemRef422.GetEventTested
        OpEventGetEventTested_GetEventTested_EvtInfo_AutoCreatedDemEvent_CC_DisablePDUGroup_CIOM_oLIN03_Rx_cfadb044_BswMReportF_ccd7084d: start-on-event=GetEventTested, operation=EvtInfo_AutoCreatedDemEvent_CC_DisablePDUGroup_CIOM_oLIN03_Rx_cfadb044_BswMReportFailToDemRef422.GetEventTested
        OpEventGetEventTested_GetEventTested_EvtInfo_AutoCreatedDemEvent_CC_DisablePDUGroup_CIOM_oLIN03_Tx_99f717c2_BswMReportF_c3601619: start-on-event=GetEventTested, operation=EvtInfo_AutoCreatedDemEvent_CC_DisablePDUGroup_CIOM_oLIN03_Tx_99f717c2_BswMReportFailToDemRef422.GetEventTested
        OpEventGetEventTested_GetEventTested_EvtInfo_AutoCreatedDemEvent_CC_DisablePDUGroup_CIOM_oLIN04_Rx_527a88fd_BswMReportF_5e64d509: start-on-event=GetEventTested, operation=EvtInfo_AutoCreatedDemEvent_CC_DisablePDUGroup_CIOM_oLIN04_Rx_527a88fd_BswMReportFailToDemRef422.GetEventTested
